VERSION "Generated from PQ35_46 ACAN KMatrix"

NS_ :

BS_:

BU_: XXX AFS Airbag Allrad AppGW_SK BAP_Tester BMS_Hybrid Bremse_ESP_AU714 Bremse_ESP_EPB_EBC460Vi Bremse_MK100_ESC Bremse_MK60EC Bremse_MK70MABS Bremse_TRW_EBC450M Bremse_TRW_ESP Daempfer EPB_TRW EPB_TRW_VW411CS ESP_AU316 FLA Gateway_PQ35 Getriebe_AG6 Getriebe_DL800_R8 Getriebe_DL800_ZSG_R8 Getriebe_DQ Getriebe_DQ_Hyb Getriebe_Sele Gurtmikro_PQ35 HCA LEH_Hybrid LH_EPS_APA LH_EPS_ZF_2G LH_EPS_ZF_3G LPG_Interface_Box LWR LWS Magne_Ride Motor_Diesel Motor_Hybrid Motor_Otto Motor_Slave PDC_PLA Quersperre_VAQ RKA_Plus SAK Waehlhebel Waehlhebel_Sele

BO_ 1416 mMotor_7: 8 XXX
 SG_ MO7_Hoeheninfo : 16|8@1+ (0.0078125,0) [0|1.984375] "" Bremse_ESP_EPB_EBC460Vi,Bremse_MK100_ESC,Bremse_MK60EC,Bremse_MK70MABS,Bremse_TRW_EBC450M,Bremse_TRW_ESP,ESP_AU316,Gateway_PQ35,Getriebe_DL800_R8,Getriebe_DQ,Getriebe_DQ_Hyb,Getriebe_Sele
 SG_ MO7_LL_Solldz : 0|1@1+ (1,0) [0|1] "" Gateway_PQ35
 SG_ MO7_Fehler_VBegr : 1|1@1+ (1,0) [0|1] "" Gateway_PQ35
 SG_ MO7_Sta_VBegr : 2|1@1+ (1,0) [0|1] "" Gateway_PQ35,Getriebe_AG6,Getriebe_DL800_R8,Getriebe_DQ,Getriebe_DQ_Hyb
 SG_ MO7_Fehlereintr : 3|1@1+ (1,0) [0|1] "" Gateway_PQ35
 SG_ MO7_StaOeltemp : 4|1@1+ (1,0) [0|1] "" Gateway_PQ35,Getriebe_DL800_R8,Getriebe_DQ,Getriebe_DQ_Hyb
 SG_ MO7_Sta_PTC : 5|3@1+ (1,0) [0|7] "" Gateway_PQ35
 SG_ MO7_DFM : 8|8@1+ (0.4,0) [0|101.6] "Unit_PerCent" Gateway_PQ35
 SG_ MO7_Gradient_Dz : 24|7@1+ (1,0) [0|126] "Unit_MinutInver" Gateway_PQ35
 SG_ MO7_GradientVorz : 31|1@1+ (1,0) [0|1] "" Gateway_PQ35
 SG_ MO7_Ladedruckneu : 32|8@1+ (0.02,0) [0|5.08] "Unit_Bar" Gateway_PQ35
 SG_ MO7_GenLdResp : 40|2@1+ (3,0) [0|9] "Unit_Secon" Gateway_PQ35
 SG_ MO7_PTC_bereit : 42|2@1+ (1,0) [0|0] "" Gateway_PQ35
 SG_ MO7_Mot_weckfaehig : 44|1@1+ (1,0) [0|1] "" Gateway_PQ35
 SG_ MO7_Zus_Kuehl : 45|1@1+ (1,0) [0|1] "" Gateway_PQ35
 SG_ MO7_SleepInd : 46|1@1+ (1,0) [0|1] "" Gateway_PQ35
 SG_ MO7_RueckLLDz : 47|1@1+ (1,0) [0|1] "" Gateway_PQ35
 SG_ MO7_Lastabwurf : 48|2@1+ (1,0) [0|3] "" Gateway_PQ35
 SG_ MO7_Gen_ein : 50|1@1+ (1,0) [0|1] "" Gateway_PQ35
 SG_ MO7_Lastabw_Heiz : 51|1@1+ (1,0) [0|1] "" Gateway_PQ35
 SG_ MO7_StaGluehk : 52|4@1+ (8,0) [0|112] "Unit_PerCent" Gateway_PQ35
 SG_ MO7_Oeltemp : 56|8@1+ (1,-60) [-58|194] "Unit_DegreCelsi" Gateway_PQ35,Getriebe_DL800_R8,Getriebe_DQ,Getriebe_DQ_Hyb,Getriebe_Sele

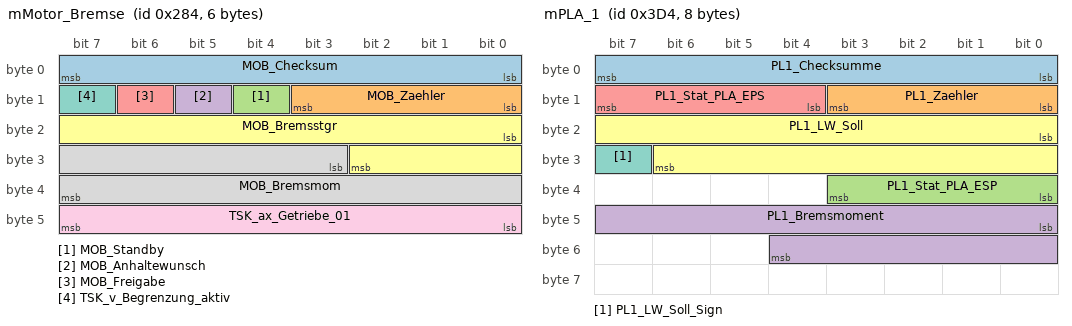
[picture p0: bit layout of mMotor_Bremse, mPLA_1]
BO_ 644 mMotor_Bremse: 6 XXX
 SG_ MOB_Checksum : 0|8@1+ (1,0) [0|255] "" Bremse_ESP_EPB_EBC460Vi,Bremse_MK100_ESC,Bremse_MK60EC,Bremse_TRW_EBC450M,Bremse_TRW_ESP
 SG_ MOB_Zaehler : 8|4@1+ (1,0) [0|15] "" Bremse_ESP_EPB_EBC460Vi,Bremse_MK100_ESC,Bremse_MK60EC,Bremse_TRW_EBC450M,Bremse_TRW_ESP
 SG_ MOB_Standby : 12|1@1+ (1,0) [0|1] "" Bremse_ESP_EPB_EBC460Vi,Bremse_MK100_ESC,Bremse_MK60EC,Bremse_TRW_EBC450M,Bremse_TRW_ESP
 SG_ MOB_Anhaltewunsch : 13|1@1+ (1,0) [0|1] "" Bremse_ESP_EPB_EBC460Vi,Bremse_MK100_ESC,Bremse_MK60EC,Bremse_TRW_EBC450M,Bremse_TRW_ESP,Getriebe_DL800_R8,Getriebe_DQ
 SG_ MOB_Freigabe : 14|1@1+ (1,0) [0|1] "" Bremse_ESP_EPB_EBC460Vi,Bremse_MK100_ESC,Bremse_MK60EC,Bremse_TRW_EBC450M,Bremse_TRW_ESP,Gateway_PQ35
 SG_ MOB_Bremsstgr : 16|11@1+ (0.048851978505129457743,0) [0|99.999999999999999999921] "Unit_PerCent" Bremse_ESP_EPB_EBC460Vi,Bremse_TRW_EBC450M,Bremse_TRW_ESP
 SG_ TSK_v_Begrenzung_aktiv : 15|1@1+ (1,0) [0|1] "" Getriebe_DQ
 SG_ MOB_Bremsmom : 27|13@1+ (4,0) [0|32760] "Unit_NewtoMeter" Bremse_MK100_ESC,Bremse_MK60EC
 SG_ TSK_ax_Getriebe_01 : 40|8@1+ (0.048,-2.016) [-2.016|10.176] "Unit_MeterPerSeconSquar" Getriebe_DQ

BO_ 980 mPLA_1: 8 XXX
 SG_ PL1_Checksumme : 0|8@1+ (1,0) [0|255] "" Bremse_ESP_EPB_EBC460Vi,Bremse_MK100_ESC,Bremse_MK60EC,Bremse_TRW_EBC450M,Bremse_TRW_ESP,Getriebe_DQ,Getriebe_DQ_Hyb,LH_EPS_APA,LH_EPS_ZF_2G,LH_EPS_ZF_3G
 SG_ PL1_Zaehler : 8|4@1+ (1,0) [0|15] "" Bremse_ESP_EPB_EBC460Vi,Bremse_MK100_ESC,Bremse_MK60EC,Bremse_TRW_EBC450M,Bremse_TRW_ESP,Getriebe_DQ,Getriebe_DQ_Hyb,LH_EPS_APA,LH_EPS_ZF_2G,LH_EPS_ZF_3G
 SG_ PL1_Stat_PLA_ESP : 32|4@1+ (1,0) [4|10] "" Bremse_ESP_EPB_EBC460Vi,Bremse_MK60EC,Bremse_TRW_EBC450M,Bremse_TRW_ESP
 SG_ PL1_Bremsmoment : 40|13@1+ (4,0) [0|32760] "Unit_NewtoMeter" Bremse_ESP_EPB_EBC460Vi,Bremse_MK100_ESC,Bremse_MK60EC,Bremse_TRW_EBC450M,Bremse_TRW_ESP,Getriebe_DQ,Getriebe_DQ_Hyb
 SG_ PL1_Stat_PLA_EPS : 12|4@1+ (1,0) [0|15] "" Bremse_MK100_ESC,LH_EPS_APA,LH_EPS_ZF_2G,LH_EPS_ZF_3G
 SG_ PL1_LW_Soll : 16|15@1+ (0.04375,0) [0|1433.55625] "Unit_DegreOfArc" LH_EPS_APA,LH_EPS_ZF_2G,LH_EPS_ZF_3G
 SG_ PL1_LW_Soll_Sign : 31|1@1+ (1,0) [0|1] "" LH_EPS_APA,LH_EPS_ZF_2G,LH_EPS_ZF_3G

BO_ 1488 mSysteminfo_1: 8 XXX
 SG_ SY1_Lenker : 28|1@1+ (1,0) [0|1] "" Bremse_ESP_EPB_EBC460Vi,Bremse_MK100_ESC,Bremse_MK60EC,Bremse_TRW_EBC450M,Bremse_TRW_ESP,ESP_AU316,Motor_Diesel
 SG_ SY1_CAN_extern : 0|1@1+ (1,0) [0|1] "" XXX
 SG_ SY1_Diag_Ant : 1|1@1+ (1,0) [0|1] "" XXX
 SG_ SY1_Sleep_Komf : 2|1@1+ (1,0) [0|1] "" XXX
 SG_ SY1_Diag_Komf : 3|1@1+ (1,0) [0|1] "" XXX
 SG_ SY1_Sleep_Info : 4|1@1+ (1,0) [0|1] "" XXX
 SG_ SY1_Diag_Info : 5|1@1+ (1,0) [0|1] "" XXX
 SG_ SY1_CAN_Info : 6|1@1+ (1,0) [0|1] "" XXX
 SG_ SY1_Verbauinfo : 7|1@1+ (1,0) [0|1] "" Bremse_MK100_ESC,Motor_Diesel
 SG_ SY1_Fzg_Klasse : 8|4@1+ (1,0) [0|9] "" XXX
 SG_ SY1_Fzg_Marke : 12|4@1+ (1,0) [0|15] "" XXX
 SG_ SY1_Fzg_Derivat : 16|4@1+ (1,0) [0|15] "" SAK
 SG_ SY1_Fzg_Gen : 20|4@1+ (1,0) [0|15] "" SAK
 SG_ SY1_Fzg_Index : 24|4@1+ (1,0) [0|15] "" XXX
 SG_ SY1_Tueren : 29|1@1+ (1,0) [0|1] "" XXX
 SG_ SY1_Transportmode : 30|1@1+ (1,0) [0|1] "" Daempfer,Motor_Diesel,Motor_Hybrid,Motor_Otto
 SG_ SY1_Fehlereintr : 31|1@1+ (1,0) [0|1] "" XXX
 SG_ SY1_Komf_NV : 32|4@1+ (1,0) [0|9] "" XXX
 SG_ SY1_Komf_HV : 36|4@1+ (1,0) [0|9] "" XXX
 SG_ SY1_Ant_NV : 40|4@1+ (1,0) [0|9] "" XXX
 SG_ SY1_Ant_HV : 44|4@1+ (1,0) [0|9] "" XXX
 SG_ SY1_Relais_FAS_Zweig : 48|2@1+ (1,0) [0|3] "" HCA
 SG_ SY1_ELV_Lock_Supply : 50|1@1+ (1,0) [0|1] "" XXX
 SG_ SY1_QRS_Messmodus : 51|1@1+ (1,0) [0|1] "" Motor_Diesel,Motor_Hybrid,Motor_Otto
 SG_ SY1_NWDF_gueltig : 54|1@1+ (1,0) [0|1] "" AFS,Allrad,FLA,LWR,PDC_PLA
 SG_ SY1_NWDF : 55|1@1+ (1,0) [0|1] "" AFS,Allrad,FLA,LWR,PDC_PLA
 SG_ SY1_Notbrems_Status : 56|1@1+ (1,0) [0|1] "" XXX

BO_ 1838 NMH_BMS: 7 XXX
 SG_ NMH_BMS_Start_1 : 0|1@1+ (1,0) [1|1] "" Bremse_ESP_EPB_EBC460Vi,Bremse_MK100_ESC,Bremse_MK60EC,Bremse_MK70MABS,Bremse_TRW_EBC450M,Bremse_TRW_ESP,EPB_TRW_VW411CS,Gateway_PQ35,Getriebe_AG6,Getriebe_DL800_ZSG_R8,LEH_Hybrid,Motor_Diesel,Motor_Hybrid,Motor_Otto
 SG_ NMH_BMS_Start_2 : 1|1@1+ (1,0) [1|1] "" XXX
 SG_ NMH_BMS_Normal_Mode_1 : 2|1@1+ (1,0) [1|1] "" XXX
 SG_ NMH_BMS_Normal_Mode_2 : 3|1@1+ (1,0) [1|1] "" XXX
 SG_ NMH_BMS_Car_WakeUp : 6|1@1+ (1,0) [1|1] "" XXX
 SG_ NMH_BMS_Per_WakeUp : 8|5@1+ (1,0) [0|3] "" XXX
 SG_ NMH_BMS_Fkt_WakeUp : 13|3@1+ (1,0) [0|0] "" XXX
 SG_ NMH_BMS_NM_aktiv_Klemme_15 : 16|1@1+ (1,0) [1|1] "" XXX
 SG_ NMH_BMS_NM_aktiv_Diagnose : 17|1@1+ (1,0) [1|1] "" XXX
 SG_ NMH_BMS_NM_aktiv_Start : 18|1@1+ (1,0) [1|1] "" XXX
 SG_ NMH_BMS_NL_aktiv_4 : 19|1@1+ (1,0) [1|1] "" XXX
 SG_ NMH_BMS_NL_aktiv_5 : 20|1@1+ (1,0) [1|1] "" XXX
 SG_ NMH_BMS_NL_aktiv_6 : 21|1@1+ (1,0) [1|1] "" XXX
 SG_ NMH_BMS_NL_aktiv_7 : 22|1@1+ (1,0) [1|1] "" XXX
 SG_ NMH_BMS_NL_aktiv_8 : 23|1@1+ (1,0) [1|1] "" XXX
 SG_ NMH_BMS_NL_0 : 24|1@1+ (1,0) [1|1] "" XXX
 SG_ NMH_BMS_NL_1 : 25|1@1+ (1,0) [1|1] "" XXX
 SG_ NMH_BMS_NL_2 : 26|1@1+ (1,0) [0|1] "" XXX
 SG_ NMH_BMS_NL_3 : 27|1@1+ (1,0) [0|1] "" XXX
 SG_ NMH_BMS_NL_4 : 28|1@1+ (1,0) [0|1] "" XXX
 SG_ NMH_BMS_NL_5 : 29|1@1+ (1,0) [0|1] "" XXX
 SG_ NMH_BMS_NL_6 : 30|1@1+ (1,0) [0|1] "" XXX
 SG_ NMH_BMS_NL_7 : 31|1@1+ (1,0) [0|1] "" XXX
 SG_ NMH_BMS_TimeOut_Fehler : 33|1@1+ (1,0) [1|1] "" XXX
 SG_ NMH_BMS_CAN_Diag_deaktiv : 34|1@1+ (1,0) [1|1] "" XXX
 SG_ NMH_BMS_KompSchutz : 35|1@1+ (1,0) [1|1] "" XXX
 SG_ NMH_BMS_Mute_Mode : 36|1@1+ (1,0) [1|1] "" XXX
 SG_ NMH_BMS_Transport_Mode : 37|1@1+ (1,0) [1|1] "" XXX
 SG_ NMH_BMS_Abschaltstufe_aktiv : 38|1@1+ (1,0) [1|1] "" XXX
 SG_ NMH_BMS_Eindraht_Fehler : 39|1@1+ (1,0) [1|1] "" XXX

BO_ 1839 NMH_EM: 7 XXX
 SG_ NMH_EM_Start_1 : 0|1@1+ (1,0) [1|1] "" BMS_Hybrid,Bremse_ESP_EPB_EBC460Vi,Bremse_MK100_ESC,Bremse_MK60EC,Bremse_MK70MABS,Bremse_TRW_EBC450M,Bremse_TRW_ESP,EPB_TRW_VW411CS,Gateway_PQ35,Getriebe_AG6,Getriebe_DL800_ZSG_R8,Motor_Diesel,Motor_Hybrid,Motor_Otto
 SG_ NMH_EM_Start_2 : 1|1@1+ (1,0) [1|1] "" XXX
 SG_ NMH_EM_Normal_Mode_1 : 2|1@1+ (1,0) [1|1] "" XXX
 SG_ NMH_EM_Normal_Mode_2 : 3|1@1+ (1,0) [1|1] "" XXX
 SG_ NMH_EM_Car_WakeUp : 6|1@1+ (1,0) [1|1] "" XXX
 SG_ NMH_EM_Per_WakeUp : 8|5@1+ (1,0) [0|3] "" XXX
 SG_ NMH_EM_Fkt_WakeUp : 13|3@1+ (1,0) [0|0] "" XXX
 SG_ NMH_EM_NM_aktiv_Klemme_15 : 16|1@1+ (1,0) [1|1] "" XXX
 SG_ NMH_EM_NM_aktiv_Diagnose : 17|1@1+ (1,0) [1|1] "" XXX
 SG_ NMH_EM_NM_aktiv_Start : 18|1@1+ (1,0) [1|1] "" XXX
 SG_ NMH_EM_NL_aktiv_4 : 19|1@1+ (1,0) [0|1] "" XXX
 SG_ NMH_EM_NL_aktiv_5 : 20|1@1+ (1,0) [1|1] "" XXX
 SG_ NMH_EM_NL_aktiv_6 : 21|1@1+ (1,0) [1|1] "" XXX
 SG_ NMH_EM_NL_aktiv_7 : 22|1@1+ (1,0) [1|1] "" XXX
 SG_ NMH_EM_NL_aktiv_8 : 23|1@1+ (1,0) [1|1] "" XXX
 SG_ NMH_EM_NL_0 : 24|1@1+ (1,0) [1|1] "" XXX
 SG_ NMH_EM_NL_1 : 25|1@1+ (1,0) [1|1] "" XXX
 SG_ NMH_EM_NL_2 : 26|1@1+ (1,0) [0|1] "" XXX
 SG_ NMH_EM_NL_3 : 27|1@1+ (1,0) [0|1] "" XXX
 SG_ NMH_EM_NL_4 : 28|1@1+ (1,0) [0|1] "" XXX
 SG_ NMH_EM_NL_5 : 29|1@1+ (1,0) [0|1] "" XXX
 SG_ NMH_EM_NL_6 : 30|1@1+ (1,0) [0|1] "" XXX
 SG_ NMH_EM_NL_7 : 31|1@1+ (1,0) [0|1] "" XXX
 SG_ NMH_EM_TimeOut_Fehler : 33|1@1+ (1,0) [1|1] "" XXX
 SG_ NMH_EM_CAN_Diag_deaktiv : 34|1@1+ (1,0) [1|1] "" XXX
 SG_ NMH_EM_KompSchutz : 35|1@1+ (1,0) [1|1] "" XXX
 SG_ NMH_EM_Mute_Mode : 36|1@1+ (1,0) [1|1] "" XXX
 SG_ NMH_EM_Transport_Mode : 37|1@1+ (1,0) [1|1] "" XXX
 SG_ NMH_EM_Abschaltstufe_aktiv : 38|1@1+ (1,0) [1|1] "" XXX
 SG_ NMH_EM_Eindraht_Fehler : 39|1@1+ (1,0) [1|1] "" XXX

BO_ 1849 NMH_EPB: 7 XXX
 SG_ NMH_EPB_Start_1 : 0|1@1+ (1,0) [1|1] "" BMS_Hybrid,Bremse_ESP_EPB_EBC460Vi,Bremse_MK100_ESC,Bremse_MK60EC,Bremse_MK70MABS,Bremse_TRW_EBC450M,Bremse_TRW_ESP,Gateway_PQ35,Getriebe_AG6,Getriebe_DL800_ZSG_R8,LEH_Hybrid,Motor_Diesel,Motor_Hybrid,Motor_Otto
 SG_ NMH_EPB_Start_2 : 1|1@1+ (1,0) [1|1] "" XXX
 SG_ NMH_EPB_Normal_Mode_1 : 2|1@1+ (1,0) [1|1] "" XXX
 SG_ NMH_EPB_Normal_Mode_2 : 3|1@1+ (1,0) [1|1] "" XXX
 SG_ NMH_EPB_Car_WakeUp : 6|1@1+ (1,0) [1|1] "" XXX
 SG_ NMH_EPB_Per_WakeUp : 8|5@1+ (1,0) [0|5] "" XXX
 SG_ NMH_EPB_Fkt_WakeUp : 13|3@1+ (1,0) [0|0] "" XXX
 SG_ NMH_EPB_NM_aktiv_Klemme_15 : 16|1@1+ (1,0) [1|1] "" XXX
 SG_ NMH_EPB_NM_aktiv_Diagnose : 17|1@1+ (1,0) [1|1] "" XXX
 SG_ NMH_EPB_NM_aktiv_Start : 18|1@1+ (1,0) [1|1] "" XXX
 SG_ NMH_EPB_NL_aktiv_4 : 19|1@1+ (1,0) [1|1] "" XXX
 SG_ NMH_EPB_NL_aktiv_5 : 20|1@1+ (1,0) [1|1] "" XXX
 SG_ NMH_EPB_NL_aktiv_6 : 21|1@1+ (1,0) [1|1] "" XXX
 SG_ NMH_EPB_NL_aktiv_7 : 22|1@1+ (1,0) [1|1] "" XXX
 SG_ NMH_EPB_NL_aktiv_8 : 23|1@1+ (1,0) [1|1] "" XXX
 SG_ NMH_EPB_NL_0 : 24|1@1+ (1,0) [0|1] "" XXX
 SG_ NMH_EPB_NL_1 : 25|1@1+ (1,0) [0|1] "" XXX
 SG_ NMH_EPB_NL_2 : 26|1@1+ (1,0) [0|1] "" XXX
 SG_ NMH_EPB_NL_3 : 27|1@1+ (1,0) [0|1] "" XXX
 SG_ NMH_EPB_NL_4 : 28|1@1+ (1,0) [0|1] "" XXX
 SG_ NMH_EPB_NL_5 : 29|1@1+ (1,0) [0|1] "" XXX
 SG_ NMH_EPB_NL_6 : 30|1@1+ (1,0) [0|1] "" XXX
 SG_ NMH_EPB_NL_7 : 31|1@1+ (1,0) [0|1] "" XXX
 SG_ NMH_EPB_TimeOut_Fehler : 33|1@1+ (1,0) [1|1] "" XXX
 SG_ NMH_EPB_CAN_Diag_deaktiv : 34|1@1+ (1,0) [1|1] "" XXX
 SG_ NMH_EPB_KompSchutz : 35|1@1+ (1,0) [1|1] "" XXX
 SG_ NMH_EPB_Mute_Mode : 36|1@1+ (1,0) [1|1] "" XXX
 SG_ NMH_EPB_Transport_Mode : 37|1@1+ (1,0) [1|1] "" XXX
 SG_ NMH_EPB_Abschaltstufe_aktiv : 38|1@1+ (1,0) [1|1] "" XXX
 SG_ NMH_EPB_Eindraht_Fehler : 39|1@1+ (1,0) [1|1] "" XXX

BO_ 1824 NMH_Gateway: 7 XXX
 SG_ NMH_GW_Start_1 : 0|1@1+ (1,0) [1|1] "" BMS_Hybrid,Bremse_ESP_EPB_EBC460Vi,Bremse_MK100_ESC,Bremse_MK60EC,Bremse_MK70MABS,Bremse_TRW_EBC450M,Bremse_TRW_ESP,EPB_TRW_VW411CS,ESP_AU316,Getriebe_AG6,Getriebe_DL800_ZSG_R8,LEH_Hybrid,Motor_Diesel,Motor_Hybrid,Motor_Otto
 SG_ NMH_GW_Start_2 : 1|1@1+ (1,0) [1|1] "" XXX
 SG_ NMH_GW_Normal_Mode_1 : 2|1@1+ (1,0) [1|1] "" XXX
 SG_ NMH_GW_Normal_Mode_2 : 3|1@1+ (1,0) [1|1] "" XXX
 SG_ NMH_GW_Car_WakeUp : 6|1@1+ (1,0) [1|1] "" XXX
 SG_ NMH_GW_Per_WakeUp : 8|5@1+ (1,0) [0|12] "" XXX
 SG_ NMH_GW_Fkt_WakeUp : 13|3@1+ (1,0) [0|7] "" XXX
 SG_ NMH_GW_NM_aktiv_Klemme_15 : 16|1@1+ (1,0) [1|1] "" XXX
 SG_ NMH_GW_NM_aktiv_Diagnose : 17|1@1+ (1,0) [1|1] "" XXX
 SG_ NMH_GW_NM_aktiv_Start : 18|1@1+ (1,0) [1|1] "" XXX
 SG_ NMH_GW_NL_aktiv_4 : 19|1@1+ (1,0) [1|1] "" XXX
 SG_ NMH_GW_NL_aktiv_5 : 20|1@1+ (1,0) [1|1] "" XXX
 SG_ NMH_GW_NL_aktiv_6 : 21|1@1+ (1,0) [1|1] "" XXX
 SG_ NMH_GW_NL_aktiv_7 : 22|1@1+ (1,0) [1|1] "" XXX
 SG_ NMH_GW_NL_aktiv_8 : 23|1@1+ (1,0) [1|1] "" XXX
 SG_ NMH_GW_NL_0 : 24|1@1+ (1,0) [1|1] "" XXX
 SG_ NMH_GW_NL_1 : 25|1@1+ (1,0) [0|1] "" XXX
 SG_ NMH_GW_NL_2 : 26|1@1+ (1,0) [0|1] "" XXX
 SG_ NMH_GW_NL_3 : 27|1@1+ (1,0) [0|1] "" XXX
 SG_ NMH_GW_NL_4 : 28|1@1+ (1,0) [0|1] "" XXX
 SG_ NMH_GW_NL_5 : 29|1@1+ (1,0) [0|1] "" XXX
 SG_ NMH_GW_NL_6 : 30|1@1+ (1,0) [0|1] "" XXX
 SG_ NMH_GW_NL_7 : 31|1@1+ (1,0) [0|1] "" XXX
 SG_ NMH_GW_TimeOut_Fehler : 33|1@1+ (1,0) [1|1] "" XXX
 SG_ NMH_GW_CAN_Diag_deaktiv : 34|1@1+ (1,0) [1|1] "" XXX
 SG_ NMH_GW_KompSchutz : 35|1@1+ (1,0) [1|1] "" XXX
 SG_ NMH_GW_Mute_Mode : 36|1@1+ (1,0) [1|1] "" XXX
 SG_ NMH_GW_Transport_Mode : 37|1@1+ (1,0) [1|1] "" XXX
 SG_ NMH_GW_Abschaltstufe_aktiv : 38|1@1+ (1,0) [1|1] "" XXX
 SG_ NMH_GW_Eindraht_Fehler : 39|1@1+ (1,0) [1|1] "" XXX

BO_ 1826 NMH_Getriebe: 7 XXX
 SG_ NMH_Getriebe_Start_1 : 0|1@1+ (1,0) [1|1] "" BMS_Hybrid,Bremse_ESP_EPB_EBC460Vi,Bremse_MK100_ESC,Bremse_MK60EC,Bremse_MK70MABS,Bremse_TRW_EBC450M,Bremse_TRW_ESP,EPB_TRW_VW411CS,Gateway_PQ35,Getriebe_DL800_ZSG_R8,LEH_Hybrid,Motor_Diesel,Motor_Hybrid,Motor_Otto
 SG_ NMH_Getriebe_Start_2 : 1|1@1+ (1,0) [1|1] "" XXX
 SG_ NMH_Getriebe_Normal_Mode_1 : 2|1@1+ (1,0) [1|1] "" XXX
 SG_ NMH_Getriebe_Normal_Mode_2 : 3|1@1+ (1,0) [1|1] "" XXX
 SG_ NMH_Getriebe_Car_WakeUp : 6|1@1+ (1,0) [1|1] "" XXX
 SG_ NMH_Getriebe_Per_WakeUp : 8|5@1+ (1,0) [0|3] "" XXX
 SG_ NMH_Getriebe_Fkt_WakeUp : 13|3@1+ (1,0) [0|0] "" XXX
 SG_ NMH_Getriebe_NM_aktiv_Klemme_15 : 16|1@1+ (1,0) [1|1] "" XXX
 SG_ NMH_Getriebe_NM_aktiv_Diagnose : 17|1@1+ (1,0) [1|1] "" XXX
 SG_ NMH_Getriebe_NM_aktiv_Start : 18|1@1+ (1,0) [1|1] "" XXX
 SG_ NMH_Getriebe_NL_aktiv_4 : 19|1@1+ (1,0) [1|1] "" XXX
 SG_ NMH_Getriebe_NL_aktiv_5 : 20|1@1+ (1,0) [1|1] "" XXX
 SG_ NMH_Getriebe_NL_aktiv_6 : 21|1@1+ (1,0) [1|1] "" XXX
 SG_ NMH_Getriebe_NL_aktiv_7 : 22|1@1+ (1,0) [1|1] "" XXX
 SG_ NMH_Getriebe_NL_aktiv_8 : 23|1@1+ (1,0) [1|1] "" XXX
 SG_ NMH_Getriebe_NL_0 : 24|1@1+ (1,0) [0|1] "" XXX
 SG_ NMH_Getriebe_NL_1 : 25|1@1+ (1,0) [0|1] "" XXX
 SG_ NMH_Getriebe_NL_2 : 26|1@1+ (1,0) [0|1] "" XXX
 SG_ NMH_Getriebe_NL_3 : 27|1@1+ (1,0) [0|1] "" XXX
 SG_ NMH_Getriebe_NL_4 : 28|1@1+ (1,0) [0|1] "" XXX
 SG_ NMH_Getriebe_NL_5 : 29|1@1+ (1,0) [0|1] "" XXX
 SG_ NMH_Getriebe_NL_6 : 30|1@1+ (1,0) [0|1] "" XXX
 SG_ NMH_Getriebe_NL_7 : 31|1@1+ (1,0) [0|1] "" XXX
 SG_ NMH_Getriebe_TimeOut_Fehler : 33|1@1+ (1,0) [1|1] "" XXX
 SG_ NMH_Getriebe_CAN_Diag_deaktiv : 34|1@1+ (1,0) [1|1] "" XXX
 SG_ NMH_Getriebe_KompSchutz : 35|1@1+ (1,0) [1|1] "" XXX
 SG_ NMH_Getriebe_Mute_Mode : 36|1@1+ (1,0) [1|1] "" XXX
 SG_ NMH_Getriebe_Transport_Mode : 37|1@1+ (1,0) [1|1] "" XXX
 SG_ NMH_Getriebe_Abschaltstufe_aktiv : 38|1@1+ (1,0) [1|1] "" XXX
 SG_ NMH_Getriebe_Eindraht_Fehler : 39|1@1+ (1,0) [1|1] "" XXX

BO_ 1834 NMH_Getriebe_02: 7 XXX
 SG_ NMH_GE_02_Start_1 : 0|1@1+ (1,0) [1|1] "" BMS_Hybrid,Bremse_ESP_EPB_EBC460Vi,Bremse_MK100_ESC,Bremse_MK60EC,Bremse_MK70MABS,Bremse_TRW_EBC450M,Bremse_TRW_ESP,EPB_TRW_VW411CS,Gateway_PQ35,Getriebe_AG6,LEH_Hybrid,Motor_Diesel,Motor_Hybrid,Motor_Otto
 SG_ NMH_GE_02_Start_2 : 1|1@1+ (1,0) [1|1] "" XXX
 SG_ NMH_GE_02_Normal_Mode_1 : 2|1@1+ (1,0) [1|1] "" XXX
 SG_ NMH_GE_02_Normal_Mode_2 : 3|1@1+ (1,0) [1|1] "" XXX
 SG_ NMH_GE_02_Car_WakeUp : 6|1@1+ (1,0) [1|1] "" XXX
 SG_ NMH_GE_02_Per_WakeUp : 8|5@1+ (1,0) [0|3] "" XXX
 SG_ NMH_GE_02_Fkt_WakeUp : 13|3@1+ (1,0) [0|0] "" XXX
 SG_ NMH_GE_02_NM_aktiv_Klemme_15 : 16|1@1+ (1,0) [1|1] "" XXX
 SG_ NMH_GE_02_NM_aktiv_Diagnose : 17|1@1+ (1,0) [1|1] "" XXX
 SG_ NMH_GE_02_NM_aktiv_Start : 18|1@1+ (1,0) [1|1] "" XXX
 SG_ NMH_GE_02_N_Haltephase : 19|1@1+ (1,0) [1|1] "" XXX
 SG_ NMH_GE_02_Positionsanzeige : 20|1@1+ (1,0) [1|1] "" XXX
 SG_ NMH_GE_02_kein_NL : 24|1@1+ (1,0) [1|1] "" XXX
 SG_ NMH_GE_02_NL_Daten_EEPROM : 25|1@1+ (1,0) [1|1] "" XXX
 SG_ NMH_GE_02_NL_Drucksens : 26|1@1+ (1,0) [1|1] "" XXX
 SG_ NMH_GE_02_NL_Abtrieb : 27|1@1+ (1,0) [1|1] "" XXX
 SG_ NMH_GE_02_NL_Waehlhebel : 28|1@1+ (1,0) [1|1] "" XXX
 SG_ NMH_GE_02_NL_Wegfahrsperre : 29|1@1+ (1,0) [1|1] "" XXX
 SG_ NMH_GE_02_Signalfehler : 32|1@1+ (1,0) [1|1] "" XXX
 SG_ NMH_GE_02_TimeOut_Fehler : 33|1@1+ (1,0) [1|1] "" XXX
 SG_ NMH_GE_02_CAN_Diag_deaktiv : 34|1@1+ (1,0) [1|1] "" XXX
 SG_ NMH_GE_02_KompSchutz : 35|1@1+ (1,0) [1|1] "" XXX
 SG_ NMH_GE_02_Mute_Mode : 36|1@1+ (1,0) [1|1] "" XXX
 SG_ NMH_GE_02_Transport_Mode : 37|1@1+ (1,0) [1|1] "" XXX
 SG_ NMH_GE_02_Abschaltstufe_aktiv : 38|1@1+ (1,0) [1|1] "" XXX
 SG_ NMH_GE_02_Eindraht_Fehler : 39|1@1+ (1,0) [1|1] "" XXX

BO_ 1836 NMH_Lademanager: 7 XXX
 SG_ NMH_Lademanager_Start_1 : 0|1@1+ (1,0) [1|1] "" BMS_Hybrid,Bremse_ESP_EPB_EBC460Vi,Bremse_MK100_ESC,Bremse_MK60EC,Bremse_MK70MABS,Bremse_TRW_EBC450M,Bremse_TRW_ESP,EPB_TRW_VW411CS,Gateway_PQ35,Getriebe_AG6,Getriebe_DL800_ZSG_R8,LEH_Hybrid,Motor_Diesel,Motor_Hybrid,Motor_Otto
 SG_ NMH_Lademanager_Start_2 : 1|1@1+ (1,0) [1|1] "" XXX
 SG_ NMH_Lademanager_Normal_Mode_1 : 2|1@1+ (1,0) [1|1] "" XXX
 SG_ NMH_Lademanager_Normal_Mode_2 : 3|1@1+ (1,0) [1|1] "" XXX
 SG_ NMH_Lademanager_Car_WakeUp : 6|1@1+ (1,0) [1|1] "" XXX
 SG_ NMH_Lademanager_Per_WakeUp : 8|5@1+ (1,0) [0|10] "" XXX
 SG_ NMH_Lademanager_Fkt_WakeUp : 13|3@1+ (1,0) [0|5] "" XXX
 SG_ NMH_Lademanager_NM_aktiv_Klemme_15 : 16|1@1+ (1,0) [1|1] "" XXX
 SG_ NMH_Lademanager_NM_aktiv_Diagnose : 17|1@1+ (1,0) [1|1] "" XXX
 SG_ NMH_Lademanager_NM_aktiv_Start : 18|1@1+ (1,0) [1|1] "" XXX
 SG_ NMH_Lademanager_NL_aktiv_4 : 19|1@1+ (1,0) [1|1] "" XXX
 SG_ NMH_Lademanager_NL_aktiv_5 : 20|1@1+ (1,0) [1|1] "" XXX
 SG_ NMH_Lademanager_NL_aktiv_6 : 21|1@1+ (1,0) [1|1] "" XXX
 SG_ NMH_Lademanager_NL_aktiv_7 : 22|1@1+ (1,0) [1|1] "" XXX
 SG_ NMH_Lademanager_NL_aktiv_8 : 23|1@1+ (1,0) [1|1] "" XXX
 SG_ NMH_Lademanager_NL_0 : 24|1@1+ (1,0) [0|1] "" XXX
 SG_ NMH_Lademanager_NL_1 : 25|1@1+ (1,0) [0|1] "" XXX
 SG_ NMH_Lademanager_NL_2 : 26|1@1+ (1,0) [0|1] "" XXX
 SG_ NMH_Lademanager_NL_3 : 27|1@1+ (1,0) [0|1] "" XXX
 SG_ NMH_Lademanager_NL_4 : 28|1@1+ (1,0) [0|1] "" XXX
 SG_ NMH_Lademanager_NL_5 : 29|1@1+ (1,0) [0|1] "" XXX
 SG_ NMH_Lademanager_NL_6 : 30|1@1+ (1,0) [0|1] "" XXX
 SG_ NMH_Lademanager_NL_7 : 31|1@1+ (1,0) [0|1] "" XXX
 SG_ NMH_Lademanager_TimeOut_Fehler : 33|1@1+ (1,0) [1|1] "" XXX
 SG_ NMH_Lademanager_CAN_Diag_deaktiv : 34|1@1+ (1,0) [1|1] "" XXX
 SG_ NMH_Lademanager_KompSchutz : 35|1@1+ (1,0) [1|1] "" XXX
 SG_ NMH_Lademanager_Mute_Mode : 36|1@1+ (1,0) [1|1] "" XXX
 SG_ NMH_Lademanager_Transport_Mode : 37|1@1+ (1,0) [1|1] "" XXX
 SG_ NMH_Lademanager_Abschaltstufe_aktiv : 38|1@1+ (1,0) [1|1] "" XXX
 SG_ NMH_Lademanager_Eindraht_Fehler : 39|1@1+ (1,0) [1|1] "" XXX

BO_ 1825 NMH_Motor: 7 XXX
 SG_ NMH_MO_Start_1 : 0|1@1+ (1,0) [1|1] "" BMS_Hybrid,Bremse_ESP_EPB_EBC460Vi,Bremse_MK100_ESC,Bremse_MK60EC,Bremse_MK70MABS,Bremse_TRW_EBC450M,Bremse_TRW_ESP,EPB_TRW_VW411CS,ESP_AU316,Gateway_PQ35,Getriebe_AG6,Getriebe_DL800_ZSG_R8,LEH_Hybrid
 SG_ NMH_MO_Start_2 : 1|1@1+ (1,0) [1|1] "" XXX
 SG_ NMH_MO_Normal_Mode_1 : 2|1@1+ (1,0) [1|1] "" XXX
 SG_ NMH_MO_Normal_Mode_2 : 3|1@1+ (1,0) [1|1] "" XXX
 SG_ NMH_MO_Car_WakeUp : 6|1@1+ (1,0) [1|1] "" XXX
 SG_ NMH_MO_Per_WakeUp : 8|5@1+ (1,0) [0|5] "" XXX
 SG_ NMH_MO_Fkt_WakeUp : 13|3@1+ (1,0) [0|0] "" XXX
 SG_ NMH_MO_NM_aktiv_Klemme_15 : 16|1@1+ (1,0) [1|1] "" XXX
 SG_ NMH_MO_NM_aktiv_Diagnose : 17|1@1+ (1,0) [1|1] "" XXX
 SG_ NMH_MO_NM_aktiv_Start : 18|1@1+ (1,0) [1|1] "" XXX
 SG_ NMH_MO_NL_aktiv_4 : 19|1@1+ (1,0) [1|1] "" XXX
 SG_ NMH_MO_NL_aktiv_5 : 20|1@1+ (1,0) [1|1] "" XXX
 SG_ NMH_MO_NL_aktiv_6 : 21|1@1+ (1,0) [1|1] "" XXX
 SG_ NMH_MO_NL_aktiv_7 : 22|1@1+ (1,0) [1|1] "" XXX
 SG_ NMH_MO_NL_aktiv_8 : 23|1@1+ (1,0) [1|1] "" XXX
 SG_ NMH_MO_NL_0 : 24|1@1+ (1,0) [0|1] "" XXX
 SG_ NMH_MO_NL_1 : 25|1@1+ (1,0) [1|1] "" XXX
 SG_ NMH_MO_NL_2 : 26|1@1+ (1,0) [1|1] "" XXX
 SG_ NMH_MO_NL_3 : 27|1@1+ (1,0) [1|1] "" XXX
 SG_ NMH_MO_NL_4 : 28|1@1+ (1,0) [1|1] "" XXX
 SG_ NMH_MO_NL_5 : 29|1@1+ (1,0) [1|1] "" XXX
 SG_ NMH_MO_NL_6 : 30|1@1+ (1,0) [0|1] "" XXX
 SG_ NMH_MO_NL_7 : 31|1@1+ (1,0) [0|1] "" XXX
 SG_ NMH_MO_TimeOut_Fehler : 33|1@1+ (1,0) [1|1] "" XXX
 SG_ NMH_MO_CAN_Diag_deaktiv : 34|1@1+ (1,0) [1|1] "" XXX
 SG_ NMH_MO_KompSchutz : 35|1@1+ (1,0) [1|1] "" XXX
 SG_ NMH_MO_Mute_Mode : 36|1@1+ (1,0) [1|1] "" XXX
 SG_ NMH_MO_Transport_Mode : 37|1@1+ (1,0) [1|1] "" XXX
 SG_ NMH_MO_Abschaltstufe_aktiv : 38|1@1+ (1,0) [1|1] "" XXX
 SG_ NMH_MO_Eindraht_Fehler : 39|1@1+ (1,0) [1|1] "" XXX

BO_ 1652 BAP_ACC: 8 XXX
 SG_ BAP_Data_ACC : 0|16@1+ (1,0) [0|65535] "" Gateway_PQ35

BO_ 1654 BAP_Anzeige: 8 XXX
 SG_ BAP_Data_Anzeige : 0|16@1+ (1,0) [0|65535] "" HCA,Motor_Hybrid,PDC_PLA

BO_ 1657 BAP_HYB: 8 XXX
 SG_ BAP_Data_HYB : 0|16@1+ (1,0) [0|65535] "" Gateway_PQ35

BO_ 1651 BAP_LDW: 8 XXX
 SG_ BAP_Data_LDW : 0|16@1+ (1,0) [0|65535] "" Gateway_PQ35

BO_ 1754 BAP_OPS: 8 XXX
 SG_ BAP_Data_OPS : 0|16@1+ (1,0) [0|65535] "" Gateway_PQ35

BO_ 1656 BAP_OPS_02: 8 XXX
 SG_ BAP_Data_OPS_02 : 0|16@1+ (1,0) [0|65535] "" Gateway_PQ35

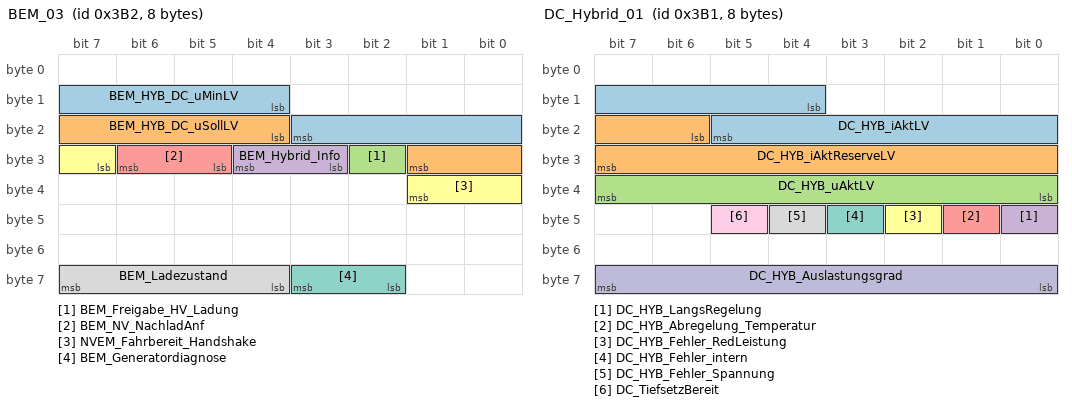
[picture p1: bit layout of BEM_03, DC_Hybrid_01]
BO_ 946 BEM_03: 8 XXX
 SG_ BEM_HYB_DC_uMinLV : 12|8@1+ (0.1,0) [0|25.3] "Unit_Volt" LEH_Hybrid
 SG_ BEM_HYB_DC_uSollLV : 20|6@1+ (0.1,10.6) [10.6|16] "Unit_Volt" LEH_Hybrid
 SG_ BEM_Freigabe_HV_Ladung : 26|1@1+ (1,0) [0|1] "" XXX
 SG_ BEM_Hybrid_Info : 27|2@1+ (1,0) [0|3] "" XXX
 SG_ BEM_NV_NachladAnf : 29|2@1+ (1,0) [0|3] "" XXX
 SG_ NVEM_Fahrbereit_Handshake : 31|3@1+ (1,0) [0|7] "" XXX
 SG_ BEM_Generatordiagnose : 58|2@1+ (1,0) [0|3] "" XXX
 SG_ BEM_Ladezustand : 60|4@1+ (10,0) [0|100] "Unit_PerCent" XXX

BO_ 945 DC_Hybrid_01: 8 XXX
 SG_ DC_HYB_iAktLV : 12|10@1+ (1,-511) [-511|510] "Unit_Amper" Gateway_PQ35
 SG_ DC_HYB_iAktReserveLV : 22|10@1+ (1,-511) [-511|510] "Unit_Amper" Gateway_PQ35
 SG_ DC_HYB_uAktLV : 32|8@1+ (0.1,0) [0|25.3] "Unit_Volt" Gateway_PQ35
 SG_ DC_HYB_LangsRegelung : 40|1@1+ (1,0) [0|1] "" Gateway_PQ35
 SG_ DC_HYB_Abregelung_Temperatur : 41|1@1+ (1,0) [0|1] "" Gateway_PQ35
 SG_ DC_HYB_Fehler_RedLeistung : 42|1@1+ (1,0) [0|1] "" Gateway_PQ35
 SG_ DC_HYB_Fehler_intern : 43|1@1+ (1,0) [0|1] "" Gateway_PQ35
 SG_ DC_HYB_Fehler_Spannung : 44|1@1+ (1,0) [0|1] "" Gateway_PQ35
 SG_ DC_TiefsetzBereit : 45|1@1+ (1,0) [0|1] "" Gateway_PQ35
 SG_ DC_HYB_Auslastungsgrad : 56|8@1+ (0.4,0) [0|100] "Unit_PerCent" Gateway_PQ35

BO_ 18 GSG_WFS_Anfrage: 8 XXX
 SG_ GSG_WFS_RND : 0|32@1+ (1,0) [0|4294967295] "" Gateway_PQ35
 SG_ GSG_WFS_CRC : 32|32@1+ (1,0) [0|4294967295] "" Gateway_PQ35

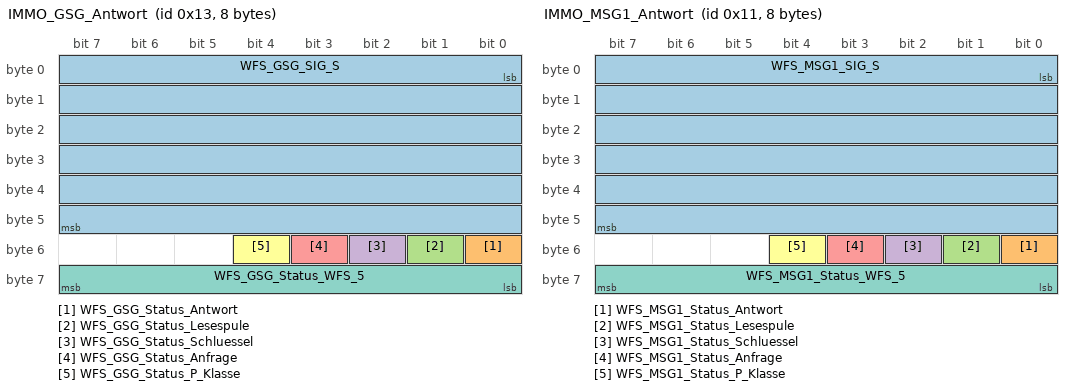
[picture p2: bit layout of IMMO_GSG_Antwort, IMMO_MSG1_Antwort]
BO_ 19 IMMO_GSG_Antwort: 8 XXX
 SG_ WFS_GSG_SIG_S : 0|48@1+ (1,0) [0|0] "" XXX
 SG_ WFS_GSG_Status_Antwort : 48|1@1+ (1,0) [0|1] "" XXX
 SG_ WFS_GSG_Status_Lesespule : 49|1@1+ (1,0) [0|1] "" XXX
 SG_ WFS_GSG_Status_Schluessel : 50|1@1+ (1,0) [0|1] "" XXX
 SG_ WFS_GSG_Status_Anfrage : 51|1@1+ (1,0) [0|1] "" XXX
 SG_ WFS_GSG_Status_P_Klasse : 52|1@1+ (1,0) [0|1] "" XXX
 SG_ WFS_GSG_Status_WFS_5 : 56|8@1+ (1,0) [0|255] "" XXX

BO_ 17 IMMO_MSG1_Antwort: 8 XXX
 SG_ WFS_MSG1_SIG_S : 0|48@1+ (1,0) [0|0] "" Motor_Diesel,Motor_Hybrid,Motor_Otto
 SG_ WFS_MSG1_Status_Antwort : 48|1@1+ (1,0) [0|1] "" Motor_Diesel,Motor_Hybrid,Motor_Otto
 SG_ WFS_MSG1_Status_Lesespule : 49|1@1+ (1,0) [0|1] "" Motor_Diesel,Motor_Hybrid,Motor_Otto
 SG_ WFS_MSG1_Status_Schluessel : 50|1@1+ (1,0) [0|1] "" Motor_Diesel,Motor_Hybrid,Motor_Otto
 SG_ WFS_MSG1_Status_Anfrage : 51|1@1+ (1,0) [0|1] "" Motor_Diesel,Motor_Hybrid,Motor_Otto
 SG_ WFS_MSG1_Status_P_Klasse : 52|1@1+ (1,0) [0|1] "" Motor_Diesel,Motor_Hybrid,Motor_Otto
 SG_ WFS_MSG1_Status_WFS_5 : 56|8@1+ (1,0) [0|255] "" Motor_Diesel,Motor_Hybrid,Motor_Otto

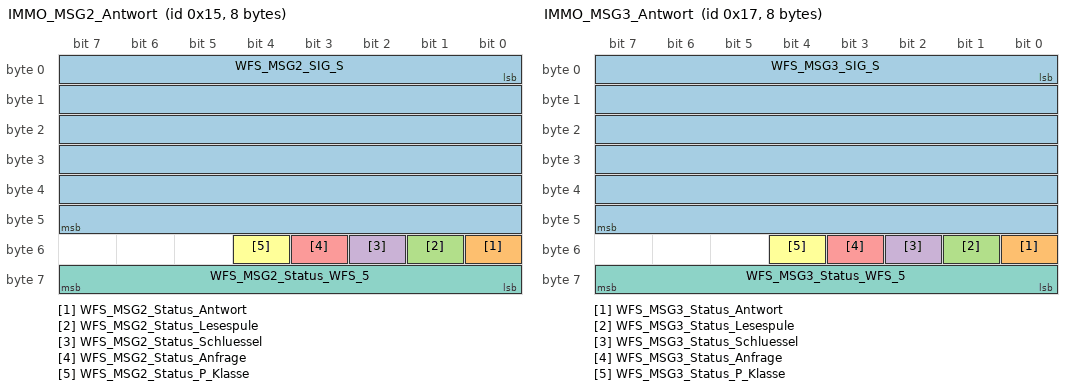
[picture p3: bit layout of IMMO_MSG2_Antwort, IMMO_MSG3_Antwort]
BO_ 21 IMMO_MSG2_Antwort: 8 XXX
 SG_ WFS_MSG2_SIG_S : 0|48@1+ (1,0) [0|0] "" Motor_Slave
 SG_ WFS_MSG2_Status_Antwort : 48|1@1+ (1,0) [0|1] "" Motor_Slave
 SG_ WFS_MSG2_Status_Lesespule : 49|1@1+ (1,0) [0|1] "" Motor_Slave
 SG_ WFS_MSG2_Status_Schluessel : 50|1@1+ (1,0) [0|1] "" Motor_Slave
 SG_ WFS_MSG2_Status_Anfrage : 51|1@1+ (1,0) [0|1] "" Motor_Slave
 SG_ WFS_MSG2_Status_P_Klasse : 52|1@1+ (1,0) [0|1] "" Motor_Slave
 SG_ WFS_MSG2_Status_WFS_5 : 56|8@1+ (1,0) [0|255] "" Motor_Slave

BO_ 23 IMMO_MSG3_Antwort: 8 XXX
 SG_ WFS_MSG3_SIG_S : 0|48@1+ (1,0) [0|0] "" XXX
 SG_ WFS_MSG3_Status_Antwort : 48|1@1+ (1,0) [0|1] "" XXX
 SG_ WFS_MSG3_Status_Lesespule : 49|1@1+ (1,0) [0|1] "" XXX
 SG_ WFS_MSG3_Status_Schluessel : 50|1@1+ (1,0) [0|1] "" XXX
 SG_ WFS_MSG3_Status_Anfrage : 51|1@1+ (1,0) [0|1] "" XXX
 SG_ WFS_MSG3_Status_P_Klasse : 52|1@1+ (1,0) [0|1] "" XXX
 SG_ WFS_MSG3_Status_WFS_5 : 56|8@1+ (1,0) [0|255] "" XXX

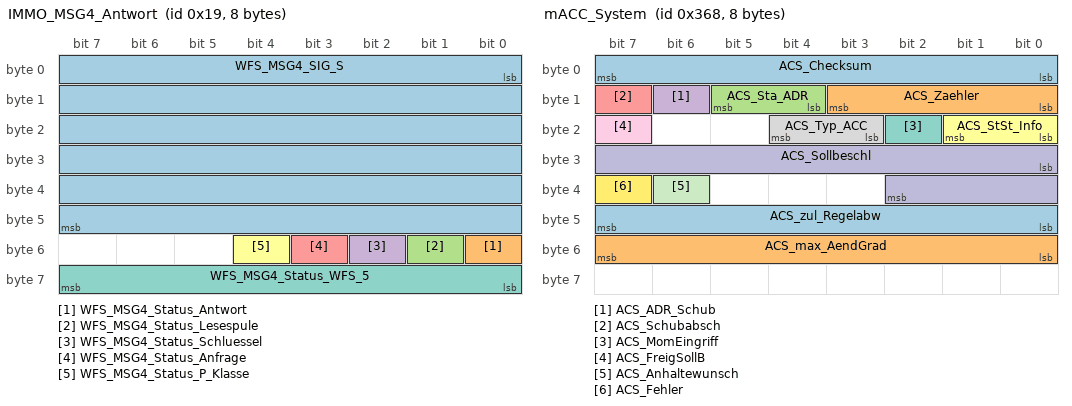
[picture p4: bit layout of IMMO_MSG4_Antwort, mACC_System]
BO_ 25 IMMO_MSG4_Antwort: 8 XXX
 SG_ WFS_MSG4_SIG_S : 0|48@1+ (1,0) [0|0] "" LEH_Hybrid
 SG_ WFS_MSG4_Status_Antwort : 48|1@1+ (1,0) [0|1] "" LEH_Hybrid
 SG_ WFS_MSG4_Status_Lesespule : 49|1@1+ (1,0) [0|1] "" LEH_Hybrid
 SG_ WFS_MSG4_Status_Schluessel : 50|1@1+ (1,0) [0|1] "" LEH_Hybrid
 SG_ WFS_MSG4_Status_Anfrage : 51|1@1+ (1,0) [0|1] "" LEH_Hybrid
 SG_ WFS_MSG4_Status_P_Klasse : 52|1@1+ (1,0) [0|1] "" LEH_Hybrid
 SG_ WFS_MSG4_Status_WFS_5 : 56|8@1+ (1,0) [0|255] "" LEH_Hybrid

BO_ 1879 ISO_ACC_Req: 8 XXX
 SG_ ISO_ACC_Req_Data : 0|64@1+ (1,0) [0|0] "" XXX

BO_ 1985 ISO_ACC_Resp: 8 XXX
 SG_ ISO_ACC_Resp_Data : 0|64@1+ (1,0) [0|0] "" Gateway_PQ35

BO_ 1892 ISO_AGA_Req: 8 XXX
 SG_ ISO_AGA_Req_Data : 0|64@1+ (1,0) [0|0] "" XXX

BO_ 1813 ISO_Airbag_01_Req: 8 XXX
 SG_ ISO_Airbag_01_Req_Data : 0|64@1+ (1,0) [0|0] "" Airbag

BO_ 1919 ISO_Airbag_01_Resp: 8 XXX
 SG_ ISO_Airbag_01_Resp_Data : 0|64@1+ (1,0) [0|0] "" Gateway_PQ35

BO_ 1807 ISO_Allrad_Req: 8 XXX
 SG_ ISO_Allrad_Req_Data : 0|64@1+ (1,0) [0|0] "" Allrad

BO_ 1913 ISO_Allrad_Resp: 8 XXX
 SG_ ISO_Allrad_Resp_Data : 0|64@1+ (1,0) [0|0] "" Gateway_PQ35

BO_ 1874 ISO_EPB_Req: 8 XXX
 SG_ ISO_EPB_Req_Data : 0|64@1+ (1,0) [0|0] "" EPB_TRW_VW411CS,RKA_Plus

BO_ 1980 ISO_EPB_Resp: 8 XXX
 SG_ ISO_EPB_Resp_Data : 0|64@1+ (1,0) [0|0] "" Gateway_PQ35

BO_ 1802 ISO_EPH_Req: 8 XXX
 SG_ ISO_EPH_Req_Data : 0|64@1+ (1,0) [0|0] "" PDC_PLA

BO_ 1908 ISO_EPH_Resp: 8 XXX
 SG_ ISO_EPH_Resp_Data : 0|64@1+ (1,0) [0|0] "" Gateway_PQ35

BO_ 1840 ISO_FLA_Req: 8 XXX
 SG_ ISO_FLA_Req_Data : 0|64@1+ (1,0) [0|0] "" FLA

BO_ 1946 ISO_FLA_Resp: 8 XXX
 SG_ ISO_FLA_Resp_Data : 0|64@1+ (1,0) [0|0] "" Gateway_PQ35

BO_ 1795 ISO_Funktionaler_Req_Abgas: 8 XXX
 SG_ ISO_Funktionaler_Req_Abgas : 0|64@1+ (1,0) [0|0] "" BMS_Hybrid,Getriebe_AG6,Getriebe_DL800_R8,Getriebe_DL800_ZSG_R8,Getriebe_DQ,Getriebe_DQ_Hyb,Getriebe_Sele,LEH_Hybrid,Motor_Diesel,Motor_Hybrid,Motor_Otto

BO_ 2015 ISO_Funktionaler_Req_OBD: 8 XXX
 SG_ ISO_OBD_Funktionaler_Req_Data : 0|64@1+ (1,0) [0|0] "" BMS_Hybrid,Getriebe_AG6,Getriebe_DL800_R8,Getriebe_DL800_ZSG_R8,Getriebe_DQ,Getriebe_DQ_Hyb,Getriebe_Sele,LEH_Hybrid,Motor_Diesel,Motor_Hybrid,Motor_Otto

BO_ 2017 ISO_Getriebe_01_Req: 8 XXX
 SG_ ISO_Getriebe_01_Req_Data : 0|64@1+ (1,0) [0|0] "" Getriebe_AG6,Getriebe_DL800_R8,Getriebe_DQ,Getriebe_DQ_Hyb,Getriebe_Sele

BO_ 2025 ISO_Getriebe_01_Resp: 8 XXX
 SG_ ISO_Getriebe_01_Resp_Data : 0|64@1+ (1,0) [0|0] "" Gateway_PQ35

BO_ 1891 ISO_Gurtmikro_Req: 8 XXX
 SG_ ISO_Gurtmikro_Req_Data : 0|64@1+ (1,0) [0|0] "" Gurtmikro_PQ35

BO_ 1997 ISO_Gurtmikro_Resp: 8 XXX
 SG_ ISO_Gurtmikro_Resp_Data : 0|64@1+ (1,0) [0|0] "" Gateway_PQ35

BO_ 1860 ISO_Ladegeraet_Req: 8 XXX
 SG_ ISO_Ladegeraet_Req_Data : 0|64@1+ (1,0) [0|0] "" Motor_Slave

BO_ 1810 ISO_Lenkhilfe_Req: 8 XXX
 SG_ ISO_Lenkhilfe_Req_Data : 0|64@1+ (1,0) [0|0] "" LH_EPS_ZF_3G

BO_ 1916 ISO_Lenkhilfe_Resp: 8 XXX
 SG_ ISO_Lenkhilfe_Resp_Data : 0|64@1+ (1,0) [0|0] "" Gateway_PQ35

BO_ 1832 ISO_LIN_Flash_Req: 8 XXX
 SG_ ISO_LIN_Flash_Req_Data : 0|64@1+ (1,0) [0|0] "" AFS

BO_ 1938 ISO_LIN_Flash_Resp: 8 XXX
 SG_ ISO_LIN_Flash_Resp_Data : 0|64@1+ (1,0) [0|0] "" Gateway_PQ35

BO_ 1876 ISO_LWRAFS_Req: 8 XXX
 SG_ ISO_LWRAFS_Req_Data : 0|64@1+ (1,0) [0|0] "" AFS

BO_ 1982 ISO_LWRAFS_Resp: 8 XXX
 SG_ ISO_LWRAFS_Resp_Data : 0|64@1+ (1,0) [0|0] "" Gateway_PQ35

BO_ 2016 ISO_MO_01_Req: 8 XXX
 SG_ ISO_MO_01_Req_Data : 0|64@1+ (1,0) [0|0] "" Motor_Diesel,Motor_Hybrid,Motor_Otto

BO_ 2024 ISO_MO_01_Resp: 8 XXX
 SG_ ISO_MO_01_Resp_Data : 0|64@1+ (1,0) [0|0] "" Gateway_PQ35

BO_ 2018 ISO_OBD_01_Req: 8 XXX
 SG_ ISO_OBD_01_Req_Data : 0|64@1+ (1,0) [0|0] "" Motor_Slave

BO_ 2026 ISO_OBD_01_Resp: 8 XXX
 SG_ ISO_OBD_01_Resp_Data : 0|64@1+ (1,0) [0|0] "" Gateway_PQ35

BO_ 2019 ISO_OBD_02_Req: 8 XXX
 SG_ ISO_OBD_02_Req_Data : 0|64@1+ (1,0) [0|0] "" Getriebe_DL800_ZSG_R8

BO_ 2027 ISO_OBD_02_Resp: 8 XXX
 SG_ ISO_OBD_02_Resp_Data : 0|64@1+ (1,0) [0|0] "" Gateway_PQ35

BO_ 2020 ISO_OBD_03_Req: 8 XXX
 SG_ ISO_OBD_03_Req_Data : 0|64@1+ (1,0) [0|0] "" XXX

BO_ 2028 ISO_OBD_03_Resp: 8 XXX
 SG_ ISO_OBD_03_Resp_Data : 0|64@1+ (1,0) [0|0] "" Gateway_PQ35

BO_ 2021 ISO_OBD_04_Req: 8 XXX
 SG_ ISO_OBD_04_Req_Data : 0|64@1+ (1,0) [0|0] "" BMS_Hybrid

BO_ 2029 ISO_OBD_04_Resp: 8 XXX
 SG_ ISO_OBD_04_Resp_Data : 0|64@1+ (1,0) [0|0] "" Gateway_PQ35

BO_ 2022 ISO_OBD_05_Req: 8 XXX
 SG_ ISO_OBD_05_Req_Data : 0|64@1+ (1,0) [0|0] "" LEH_Hybrid

BO_ 2030 ISO_OBD_05_Resp: 8 XXX
 SG_ ISO_OBD_05_Resp_Data : 0|64@1+ (1,0) [0|0] "" Gateway_PQ35

BO_ 2023 ISO_OBD_06_Req: 8 XXX
 SG_ ISO_OBD_06_Req_Data : 0|64@1+ (1,0) [0|0] "" XXX

BO_ 2031 ISO_OBD_06_Resp: 8 XXX
 SG_ ISO_OBD_06_Resp_Data : 0|64@1+ (1,0) [0|0] "" Gateway_PQ35

BO_ 1822 ISO_Quersperre_Req: 8 XXX
 SG_ ISO_Quersperre_Req_Data : 0|64@1+ (1,0) [0|0] "" XXX

BO_ 1928 ISO_Quersperre_Resp: 8 XXX
 SG_ ISO_Quersperre_Resp_Data : 0|64@1+ (1,0) [0|0] "" Gateway_PQ35

BO_ 1386 mACC_GRA_Anzeige: 8 XXX
 SG_ ACA_Checksum : 0|8@1+ (1,0) [0|255] "" Getriebe_AG6
 SG_ ACA_StaACC : 8|3@1+ (1,0) [0|7] "" PDC_PLA
 SG_ ACA_ID_StaACC : 11|5@1+ (1,0) [0|0] "" XXX
 SG_ ACA_Fahrerhinw : 16|1@1+ (1,0) [0|1] "" XXX
 SG_ ACA_AnzDisplay : 17|1@1+ (1,0) [0|1] "" XXX
 SG_ ACA_Zeitluecke : 18|4@1+ (1,0) [0|15] "" XXX
 SG_ ACA_V_Wunsch : 24|8@1+ (1,0) [0|254] "Unit_KiloMeterPerHour" Getriebe_AG6,Getriebe_DL800_R8,Getriebe_DQ,Getriebe_DQ_Hyb
 SG_ ACA_kmh_mph : 32|1@1+ (1,0) [0|1] "" XXX
 SG_ ACA_Akustik1 : 33|1@1+ (1,0) [0|1] "" XXX
 SG_ ACA_Akustik2 : 34|1@1+ (1,0) [0|1] "" XXX
 SG_ ACA_PrioDisp : 35|2@1+ (1,0) [0|3] "" XXX
 SG_ ACA_gemZeitl : 40|4@1+ (1,0) [0|15] "" XXX
 SG_ ACA_ACC_Verz : 44|1@1+ (1,0) [0|1] "" XXX
 SG_ ACA_StaGRA : 48|3@1+ (1,0) [0|7] "" XXX
 SG_ ACA_ID_StaGRA : 51|5@1+ (1,0) [0|0] "" XXX
 SG_ ACA_Codierung : 56|1@1+ (1,0) [0|1] "" Getriebe_DL800_R8,Getriebe_DQ
 SG_ ACA_Tachokranz : 57|1@1+ (1,0) [0|1] "" XXX
 SG_ ACA_Aend_Zeitluecke : 58|1@1+ (1,0) [0|1] "" XXX
 SG_ ACA_Zaehler : 60|4@1+ (1,0) [0|15] "" Getriebe_AG6

BO_ 872 mACC_System: 8 XXX
 SG_ ACS_Checksum : 0|8@1+ (1,0) [0|255] "" Daempfer,Getriebe_AG6,Getriebe_DQ,Motor_Diesel,Motor_Otto
 SG_ ACS_Zaehler : 8|4@1+ (1,0) [0|15] "" Daempfer,Getriebe_AG6,Getriebe_DQ,Motor_Diesel,Motor_Otto
 SG_ ACS_Sta_ADR : 12|2@1+ (1,0) [0|3] "" Getriebe_DQ,Motor_Diesel,Motor_Otto
 SG_ ACS_ADR_Schub : 14|1@1+ (1,0) [0|1] "" Getriebe_DQ,Motor_Diesel,Motor_Otto
 SG_ ACS_Schubabsch : 15|1@1+ (1,0) [0|1] "" Getriebe_DQ,Motor_Diesel,Motor_Otto
 SG_ ACS_StSt_Info : 16|2@1+ (1,0) [0|3] "" Motor_Diesel,Motor_Otto
 SG_ ACS_MomEingriff : 18|1@1+ (1,0) [0|1] "" Getriebe_DQ,Motor_Diesel,Motor_Otto
 SG_ ACS_Typ_ACC : 19|2@1+ (1,0) [0|3] "" Getriebe_DQ,Motor_Diesel,Motor_Otto
 SG_ ACS_FreigSollB : 23|1@1+ (1,0) [0|1] "" Daempfer,Getriebe_DQ,Motor_Diesel,Motor_Otto
 SG_ ACS_Sollbeschl : 24|11@1+ (0.005,-7.22) [-7.22|3.005] "Unit_MeterPerSeconSquar" Daempfer,Getriebe_AG6,Getriebe_DQ,Motor_Diesel,Motor_Otto
 SG_ ACS_Anhaltewunsch : 38|1@1+ (1,0) [0|1] "" Motor_Diesel,Motor_Otto
 SG_ ACS_Fehler : 39|1@1+ (1,0) [0|1] "" XXX
 SG_ ACS_zul_Regelabw : 40|8@1+ (0.005,0) [0|1.265] "Unit_MeterPerSeconSquar" Motor_Diesel,Motor_Otto
 SG_ ACS_max_AendGrad : 48|8@1+ (0.02,0) [0.02|5.06] "Unit_MeterPerSeconSquar" Motor_Diesel,Motor_Otto

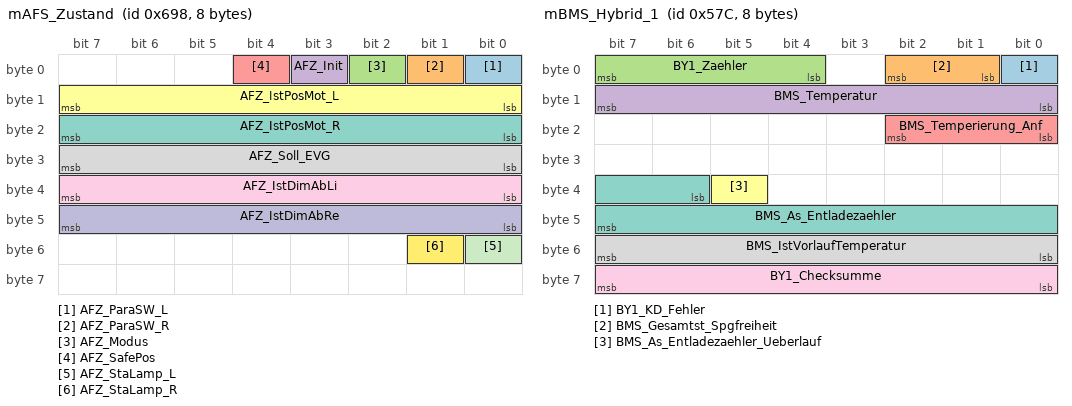
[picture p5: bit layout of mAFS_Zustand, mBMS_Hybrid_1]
BO_ 1688 mAFS_Zustand: 8 XXX
 SG_ AFZ_ParaSW_L : 0|1@1+ (1,0) [0|1] "" XXX
 SG_ AFZ_ParaSW_R : 1|1@1+ (1,0) [0|1] "" XXX
 SG_ AFZ_Modus : 2|1@1+ (1,0) [0|1] "" XXX
 SG_ AFZ_Init : 3|1@1+ (1,0) [0|1] "" XXX
 SG_ AFZ_SafePos : 4|1@1+ (1,0) [0|1] "" XXX
 SG_ AFZ_IstPosMot_L : 8|8@1+ (0.4,0) [0|100] "Unit_PerCent" XXX
 SG_ AFZ_IstPosMot_R : 16|8@1+ (0.4,0) [0|100] "Unit_PerCent" XXX
 SG_ AFZ_Soll_EVG : 24|8@1+ (0.4,0) [0|100] "Unit_PerCent" XXX
 SG_ AFZ_IstDimAbLi : 32|8@1+ (0.4,0) [0|100] "Unit_PerCent" XXX
 SG_ AFZ_IstDimAbRe : 40|8@1+ (0.4,0) [0|100] "Unit_PerCent" XXX
 SG_ AFZ_StaLamp_L : 48|1@1+ (1,0) [0|1] "" XXX
 SG_ AFZ_StaLamp_R : 49|1@1+ (1,0) [0|1] "" XXX

BO_ 1360 mAirbag_2: 8 XXX
 SG_ AB2_Checksum : 0|8@1+ (1,0) [0|255] "" Gateway_PQ35
 SG_ AB2_Beleg_HF : 8|2@1+ (1,0) [0|3] "" Gateway_PQ35
 SG_ AB2_Beleg_HBF : 10|2@1+ (1,0) [0|3] "" Gateway_PQ35
 SG_ AB2_Beleg_HM : 12|2@1+ (1,0) [0|3] "" Gateway_PQ35
 SG_ AB2_Beleg_BF : 14|2@1+ (1,0) [0|3] "" Gateway_PQ35,Gurtmikro_PQ35
 SG_ AB2_OOP_Fa : 16|3@1+ (1,0) [0|7] "" Gateway_PQ35
 SG_ AB2_OOP_BF : 19|3@1+ (1,0) [0|7] "" Gateway_PQ35
 SG_ AB2_Sta_BF : 22|2@1+ (1,0) [0|3] "" Gateway_PQ35
 SG_ AB2_Gurt_2FaS : 24|2@1+ (1,0) [0|3] "" Gateway_PQ35
 SG_ AB2_Gurt_2BfS : 26|2@1+ (1,0) [0|3] "" Gateway_PQ35
 SG_ AB2_Gurt_2Mi : 28|2@1+ (1,0) [0|3] "" Gateway_PQ35
 SG_ AB2_Gurt_3FaS : 30|2@1+ (1,0) [0|3] "" Gateway_PQ35
 SG_ AB2_Gurt_3BfS : 32|2@1+ (1,0) [0|3] "" Gateway_PQ35
 SG_ AB2_Gurt_3Mi : 34|2@1+ (1,0) [0|3] "" Gateway_PQ35
 SG_ AB_Deaktivierung_HV : 36|3@1+ (1,0) [0|7] "" Gateway_PQ35
 SG_ AB_Abschaltanf_SIH_BF : 39|1@1+ (1,0) [0|1] "" Gateway_PQ35
 SG_ AB2_Zaehler : 60|4@1+ (1,0) [0|15] "" Gateway_PQ35

BO_ 1404 mBMS_Hybrid_1: 8 XXX
 SG_ BY1_KD_Fehler : 0|1@1+ (1,0) [0|1] "" Gateway_PQ35
 SG_ BMS_Gesamtst_Spgfreiheit : 1|2@1+ (1,0) [0|3] "" Gateway_PQ35
 SG_ BY1_Zaehler : 4|4@1+ (1,0) [0|15] "" Gateway_PQ35
 SG_ BMS_Temperatur : 8|8@1+ (0.5,-40) [-40|86.5] "Unit_DegreCelsi" Gateway_PQ35
 SG_ BMS_Temperierung_Anf : 16|3@1+ (1,0) [0|7] "" Gateway_PQ35
 SG_ BMS_As_Entladezaehler_Ueberlauf : 37|1@1+ (1,0) [0|1] "" Gateway_PQ35
 SG_ BMS_As_Entladezaehler : 38|10@1+ (1,0) [0|1023] "Unit_AmperSecon" Gateway_PQ35
 SG_ BMS_IstVorlaufTemperatur : 48|8@1+ (0.5,-40) [-40|86.5] "Unit_DegreCelsi" Gateway_PQ35
 SG_ BY1_Checksumme : 56|8@1+ (1,0) [0|255] "" Gateway_PQ35

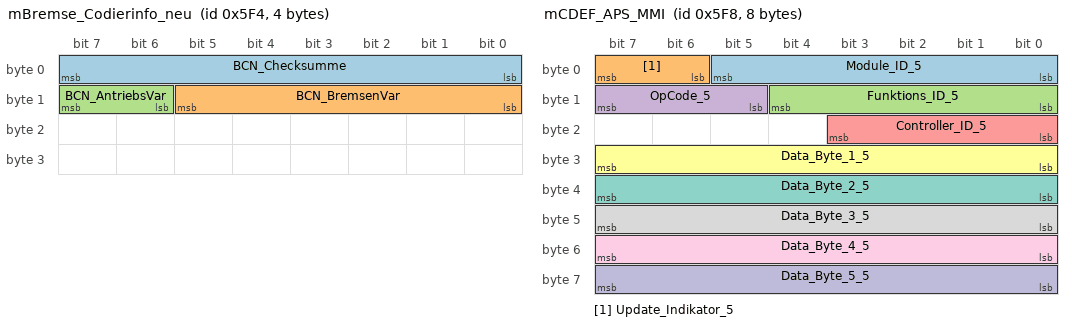
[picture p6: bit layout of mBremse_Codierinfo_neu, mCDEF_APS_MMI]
BO_ 1524 mBremse_Codierinfo_neu: 4 XXX
 SG_ BCN_Checksumme : 0|8@1+ (1,0) [0|255] "" Bremse_ESP_AU714,Bremse_MK60EC
 SG_ BCN_BremsenVar : 8|6@1+ (1,0) [0|63] "" Bremse_ESP_AU714,Bremse_MK60EC
 SG_ BCN_AntriebsVar : 14|2@1+ (1,0) [0|3] "" Bremse_ESP_AU714,Bremse_MK60EC

BO_ 1528 mCDEF_APS_MMI: 8 XXX
 SG_ Module_ID_5 : 0|6@1+ (1,0) [0|63] "" Gateway_PQ35
 SG_ Update_Indikator_5 : 6|2@1+ (1,0) [0|3] "" Gateway_PQ35
 SG_ Funktions_ID_5 : 8|5@1+ (1,0) [0|31] "" Gateway_PQ35
 SG_ OpCode_5 : 13|3@1+ (1,0) [0|7] "" Gateway_PQ35
 SG_ Controller_ID_5 : 16|4@1+ (1,0) [0|15] "" Gateway_PQ35
 SG_ Data_Byte_1_5 : 24|8@1+ (1,0) [0|255] "" Gateway_PQ35
 SG_ Data_Byte_2_5 : 32|8@1+ (1,0) [0|255] "" Gateway_PQ35
 SG_ Data_Byte_3_5 : 40|8@1+ (1,0) [0|255] "" Gateway_PQ35
 SG_ Data_Byte_4_5 : 48|8@1+ (1,0) [0|255] "" Gateway_PQ35
 SG_ Data_Byte_5_5 : 56|8@1+ (1,0) [0|255] "" Gateway_PQ35

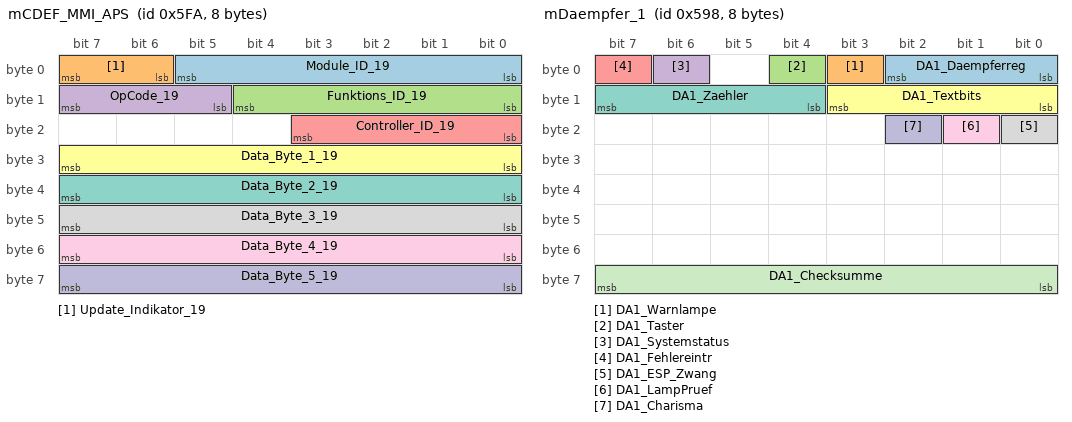
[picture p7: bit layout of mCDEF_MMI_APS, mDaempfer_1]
BO_ 1530 mCDEF_MMI_APS: 8 XXX
 SG_ Module_ID_19 : 0|6@1+ (1,0) [0|63] "" PDC_PLA
 SG_ Update_Indikator_19 : 6|2@1+ (1,0) [0|3] "" PDC_PLA
 SG_ Funktions_ID_19 : 8|5@1+ (1,0) [0|31] "" PDC_PLA
 SG_ OpCode_19 : 13|3@1+ (1,0) [0|7] "" PDC_PLA
 SG_ Controller_ID_19 : 16|4@1+ (1,0) [0|15] "" PDC_PLA
 SG_ Data_Byte_1_19 : 24|8@1+ (1,0) [0|255] "" PDC_PLA
 SG_ Data_Byte_2_19 : 32|8@1+ (1,0) [0|255] "" PDC_PLA
 SG_ Data_Byte_3_19 : 40|8@1+ (1,0) [0|255] "" PDC_PLA
 SG_ Data_Byte_4_19 : 48|8@1+ (1,0) [0|255] "" PDC_PLA
 SG_ Data_Byte_5_19 : 56|8@1+ (1,0) [0|255] "" PDC_PLA

BO_ 1504 mClima_1: 8 XXX
 SG_ CL1_LL_Dz : 0|1@1+ (1,0) [0|1] "" Motor_Diesel,Motor_Hybrid,Motor_Otto
 SG_ CL1_Fa_Zuheiz : 1|1@1+ (1,0) [0|1] "" Motor_Diesel,Motor_Hybrid,Motor_Otto
 SG_ CL1_Hecksch : 2|1@1+ (1,0) [0|1] "" XXX
 SG_ CL1_Frontsch : 3|1@1+ (1,0) [0|1] "" XXX
 SG_ CL1_Kompressor : 4|1@1+ (1,0) [0|1] "" Motor_Diesel,Motor_Hybrid,Motor_Otto
 SG_ CL1_Heizleist : 5|1@1+ (1,0) [0|1] "" Motor_Diesel
 SG_ CL1_Sta_Moment : 6|1@1+ (1,0) [0|1] "" Motor_Hybrid,Motor_Otto
 SG_ CL1_Sta_Druck : 7|1@1+ (1,0) [0|1] "" Motor_Hybrid,Motor_Otto
 SG_ CL1_Aussentemp : 8|8@1+ (0.5,-50) [-50|77] "Unit_DegreCelsi" XXX
 SG_ CL1_Druck : 16|8@1+ (0.2,0) [0|50.8] "Unit_Bar" Motor_Diesel,Motor_Hybrid,Motor_Otto
 SG_ CL1_Kompr_Last : 24|8@1+ (0.25,0) [0|63.5] "Unit_NewtoMeter" Motor_Diesel,Motor_Hybrid,Motor_Otto
 SG_ CL1_Gebl_last : 32|8@1+ (0.4,0) [0|100] "Unit_PerCent" BMS_Hybrid,Motor_Otto
 SG_ CL1_Luefter : 40|8@1+ (0.4,0) [0|100] "Unit_PerCent" Motor_Diesel,Motor_Hybrid,Motor_Otto
 SG_ CL1_Einheit_Temp : 48|1@1+ (1,0) [0|1] "" XXX
 SG_ CL1_AC_Schalter : 49|1@1+ (1,0) [0|1] "" Motor_Diesel,Motor_Hybrid,Motor_Otto
 SG_ CL1_WAPU_Zuschaltung : 50|1@1+ (1,0) [0|1] "" XXX
 SG_ CL1_Restwaerme : 51|1@1+ (1,0) [0|1] "" XXX
 SG_ CL1_PTC_Hzg : 52|3@1+ (25,0) [0|100] "Unit_PerCent" XXX
 SG_ CL1_Fehlereintr : 55|1@1+ (1,0) [0|1] "" XXX
 SG_ KL_Thermomanagement : 56|2@1+ (1,0) [0|3] "" Motor_Diesel,Motor_Hybrid,Motor_Otto
 SG_ KL_VK_Betriebsdauer : 58|6@1+ (1,0) [0|60] "Unit_Minut" XXX

BO_ 1432 mDaempfer_1: 8 XXX
 SG_ DA1_Daempferreg : 0|3@1+ (1,0) [0|7] "" Gateway_PQ35
 SG_ DA1_Warnlampe : 3|1@1+ (1,0) [0|1] "" Gateway_PQ35
 SG_ DA1_Taster : 4|1@1+ (1,0) [0|1] "" Gateway_PQ35
 SG_ DA1_Systemstatus : 6|1@1+ (1,0) [0|1] "" Gateway_PQ35
 SG_ DA1_Fehlereintr : 7|1@1+ (1,0) [0|1] "" Gateway_PQ35
 SG_ DA1_Textbits : 8|4@1+ (1,0) [0|0] "" Gateway_PQ35
 SG_ DA1_Zaehler : 12|4@1+ (1,0) [0|15] "" Bremse_ESP_AU714,Bremse_MK100_ESC,Bremse_MK60EC,Gateway_PQ35
 SG_ DA1_ESP_Zwang : 16|1@1+ (1,0) [0|1] "" Bremse_ESP_AU714,Bremse_MK100_ESC,Bremse_MK60EC,Gateway_PQ35
 SG_ DA1_LampPruef : 17|1@1+ (1,0) [0|1] "" Gateway_PQ35
 SG_ DA1_Charisma : 18|1@1+ (1,0) [0|1] "" Gateway_PQ35
 SG_ DA1_Checksumme : 56|8@1+ (1,0) [0|255] "" Bremse_ESP_AU714,Bremse_MK100_ESC,Bremse_MK60EC,Gateway_PQ35

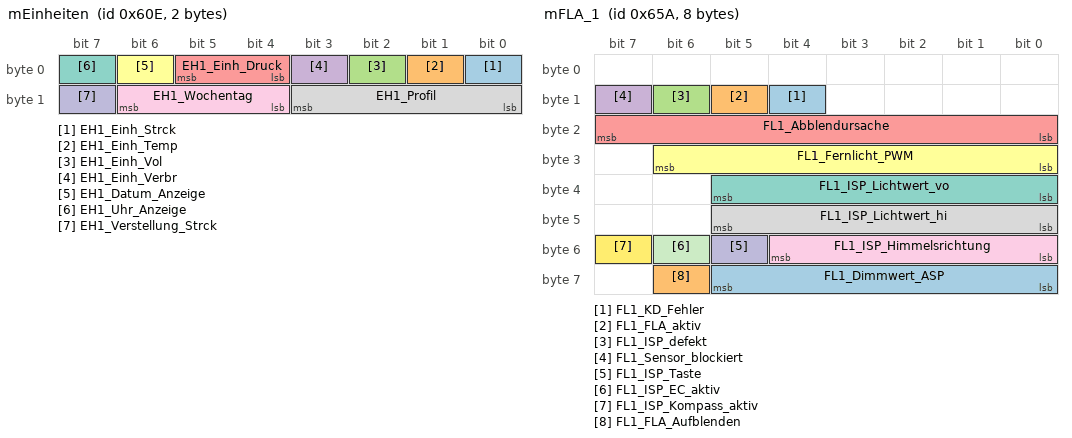
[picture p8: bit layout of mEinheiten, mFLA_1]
BO_ 1550 mEinheiten: 2 XXX
 SG_ EH1_Einh_Strck : 0|1@1+ (1,0) [0|1] "" XXX
 SG_ EH1_Einh_Temp : 1|1@1+ (1,0) [0|1] "" XXX
 SG_ EH1_Einh_Vol : 2|1@1+ (1,0) [0|1] "" Motor_Diesel
 SG_ EH1_Einh_Verbr : 3|1@1+ (1,0) [0|1] "" XXX
 SG_ EH1_Einh_Druck : 4|2@1+ (1,0) [0|3] "" XXX
 SG_ EH1_Datum_Anzeige : 6|1@1+ (1,0) [0|1] "" XXX
 SG_ EH1_Uhr_Anzeige : 7|1@1+ (1,0) [0|1] "" XXX
 SG_ EH1_Profil : 8|4@1+ (1,0) [0|15] "" XXX
 SG_ EH1_Wochentag : 12|3@1+ (1,0) [0|7] "" XXX
 SG_ EH1_Verstellung_Strck : 15|1@1+ (1,0) [0|1] "" XXX

BO_ 1406 mEM_Hybrid_1: 1 XXX
 SG_ EY1_KD_Fehler : 0|1@1+ (1,0) [0|1] "" Gateway_PQ35

BO_ 1626 mFLA_1: 8 XXX
 SG_ FL1_KD_Fehler : 12|1@1+ (1,0) [0|1] "" Gateway_PQ35
 SG_ FL1_FLA_aktiv : 13|1@1+ (1,0) [0|1] "" Gateway_PQ35
 SG_ FL1_ISP_defekt : 14|1@1+ (1,0) [0|1] "" Gateway_PQ35
 SG_ FL1_Sensor_blockiert : 15|1@1+ (1,0) [0|1] "" Gateway_PQ35
 SG_ FL1_Abblendursache : 16|8@1+ (1,0) [0|255] "" Gateway_PQ35
 SG_ FL1_Fernlicht_PWM : 24|7@1+ (1,0) [0|100] "Unit_PerCent" Gateway_PQ35
 SG_ FL1_ISP_Lichtwert_vo : 32|6@1+ (1,0) [0|61] "" Gateway_PQ35
 SG_ FL1_ISP_Lichtwert_hi : 40|6@1+ (1,0) [0|61] "" Gateway_PQ35
 SG_ FL1_ISP_Himmelsrichtung : 48|5@1+ (12,0) [0|348] "Unit_DegreOfArc" Gateway_PQ35
 SG_ FL1_ISP_Taste : 53|1@1+ (1,0) [0|1] "" Gateway_PQ35
 SG_ FL1_ISP_EC_aktiv : 54|1@1+ (1,0) [0|1] "" Gateway_PQ35
 SG_ FL1_ISP_Kompass_aktiv : 55|1@1+ (1,0) [0|1] "" Gateway_PQ35
 SG_ FL1_Dimmwert_ASP : 56|6@1+ (1.613,0) [0|100.006] "Unit_PerCent" Gateway_PQ35
 SG_ FL1_FLA_Aufblenden : 62|1@1+ (1,0) [0|1] "" Gateway_PQ35

CM_ SG_ 1416 MO7_Hoeheninfo "Korrekturfaktor Hoehe (1 entspricht 1013 mbar; 0,9 entspricht 1000m; 0,8 entspricht 2000m; 1,1 entspricht -1000m) | (Korrekturfaktor linear skaliert: delta Hoehe 1000m entsprechen delta Druck 101,3 mbar)";
CM_ SG_ 1416 MO7_LL_Solldz "Leerlauf-Solldrehzahl wurde angehoben, weil BSG_Last, Byte 2, Bit 0 oder Energiemananager 1, Byte 1, Bit 0 gesetzt war oder eine Klimaanforderung vorlag | Rueckmeldung Leerlauf-Solldrehzahl 1 fuer Lastmanagement";
CM_ SG_ 1416 MO7_Fehler_VBegr "Fehlerbit wird vom Motor-SG gesetzt, wenn dieses nicht in die Geschwindigkeits-begrenzung gehen kann, ein Fehler waehrend der v-Begrenzung auftritt oder v > v(begr.) - v(delta) | Geschwindigkeitsbegrenzung aktivierbar";
CM_ SG_ 1416 MO7_Sta_VBegr "Motor begrenzt aktuell die Geschwindigkeit des Fahrzeugs; Reaktion auf externe oder interne Anforderung | Statusbit Geschwindigkeitsbegrenzung aktiv";
CM_ SG_ 1416 MO7_Fehlereintr "Bei gesetztem Bit ist mindestens ein Kundendienstfehler eingetragen";
CM_ SG_ 1416 MO7_StaOeltemp "n.i.O. steht fuer Fehlerwert, ausserhalb des Messbereichs (ungenau), nicht verbaut oder noch kein aktueller Wert | Info aus Aufbereitung der TOG-Botschaft (nicht VW D1/Colorado, aber im Touareg GP/ D1 GP) | * Initwert 1 bei nicht verbautem Sensor oder nicht verfuegbarer Sensorinformation aus TOG-Botschaft | Fehlerstatus Oeltemperatur";
CM_ SG_ 1416 MO7_Sta_PTC "Rueckmeldung fuer das Lastmanagement, dass die PTC / Gluehstifte ausgeschaltet wurden";
CM_ SG_ 1416 MO7_DFM "Messwert Tastverhaeltnis DFM-Signal | (Nicht Audi D3 / C6!) (bei umgesetzter neuer Generatorschnittstelle wird das Signal im Colorado GP, D1GP/BY61x und Phaeton ab MJ07 nicht mehr bedient (abhaengig vom Motor-Projekt)) | Klemme_DFM";
CM_ SG_ 1416 MO7_Gradient_Dz "Differenz der Motordrehzahlen n(t) - n(t-20msec) aus der CAN-Botschaft 'Motor 1' | Motordrehzahlgradient";
CM_ SG_ 1416 MO7_GradientVorz "Positiv steht fuer steigende Drehzahl; Negativ fuer fallende Drehzahl | Vorzeichen Motordrehzahlgradient";
CM_ SG_ 1416 MO7_Ladedruckneu "Zur Anzeige im Kombi (z.Zt. nur Porsche Colorado, PQ35 Bi-Turbo, Audi RS6, TT-R) | Kombi im PQ35-Bi-Turbo und Audi RS6 und TT-R interpretiert die normierten CAN-Werte (0-254) als 0-100% der Anzeigeskala | (Aenderung Wertebereich fuer PQ35/46 mit V5.1.6 und Neuprojekte ohne Empfaenger) | | VW361/7: Nutzung als Anzeige ePowermeter (Rohwerte 1..253, 0..100,8%, Faktor 0.4, 0x0=Init/keine Anzeige, 0xFE=Funktion deaktiv/ausgegraut, 0xFF=Fehler/keine Anzeige) | VW120/7: Nutzung als Anzeige ePerformance (Rohwerte 1..253, 0..100,8%, Faktor 0.4, 0x0=Init/keine Anzeige, 0xFE=Funktion deaktiv/ausgegraut, 0xFF=Fehler/keine Anzeige)";
CM_ SG_ 1416 MO7_GenLdResp "Dient der Vermeidung der vom Generator erzeugten, mechanischen Lastspruengen und Leerlaufschwankungen durch traegere Ausregelung. Diese Massnahme darf nur kurzfristig bzw. als Notlauf wirksam sein (nicht VW D1/Colorado und PQ35/46). | Generator_Load_Response_Motor";
CM_ SG_ 1416 MO7_PTC_bereit "Bereitschaft dreistufiges PTC !!! (im AU716 und C6 ab 22/08) | Bereitschaft PTC-Heizung | 00 kein dreistufiges PTC verbaut | 0x 2x 300 W PTC-Stufe soll nicht eingeschaltet werden bzw. ist defekt (Diagnose) | 1x 2x 300 W PTC-Stufe soll eingeschaltet werden und ist bereit | x0 400 W PTC-Stufe soll nicht eingeschaltet werden bzw. ist defekt (Diagnose) | x1 400 W PTC-Stufe soll eingeschaltet werden und ist bereit";
CM_ SG_ 1416 MO7_Mot_weckfaehig "Anhand dieses Signals lernt das BSG, ob es zukuenftig bei bestimmten Ereignissen (Tuerkontakt, Anforderung Standheizung) ueber das Gateway das Wecken des Antriebs-CANs initieren soll. (nicht Audi) | Motor weckfaehig ueber CAN";
CM_ SG_ 1416 MO7_Zus_Kuehl "PQ25/35 (Diesel NAR): Ansteuerung Heckscheibenheizung | Nur Colorado V10 TDI: Zur Unterstuetzung der Motorkuehlung fordert Motor von Klima oder Zusatzheizung die Schaltung des Heizwasserkreislauf-Bypasses an (0: nein; 1: ja)";
CM_ SG_ 1416 MO7_SleepInd "Die Sleep-Bereitschaft wird nach Klemme 15 aus durch Setzen dieses Bits signalisiert | NMHigh-Teilnehmer der PQ35/46 muessen das Signal nach Kl.-15 aus weiterhin bedienen oder dauerhaft auf 1 = \"Sleep bereit\" setzen!";
CM_ SG_ 1416 MO7_RueckLLDz "Leerlauf-Solldrehzahl wurde aufgrund einer Lastmanagement-Anforderung (BSG_Last Byte 1, Bit 5 oder Energiemanager 1, Byte 1, Bit 1) auf die zweite Stufe angehoben | (nicht VW D1/Colorado) | Rueckmeldung_Leerlauf-Solldrehzahl 2";
CM_ SG_ 1416 MO7_Lastabwurf "Anforderung eines Lastabwurfs (fuer Notlauf): | Stufe 0: Keine Reduktion der Generatorspannung | Stufe 1: Generatorspannung = 13,3V | Stufe 2: Generatorspannung = 12,6V | Stufe 3: Generatorspannung = 11,8V | Anmerkung: Stufe 3 nur fuer aeussersten Notfall! | Schaltaktionen erfolgen seitens BEM mit Load-Response. | Solange die Generatorspannung reduziert ist, bleiben auch die Hochleistungsheizsysteme (Frontscheiben-heizung und PTC-Heizung) ausgeschaltet. Die Reduktion der Generatorspannung auf Stufe 2 und 3 darf max. fuer 10 sec aktiviert werden, danach wird das BEM die Generatorspannungsreduktion auf Stufe 1 setzen, solange bis Generatorspannung vom Motorsteuergeraet auf Stufe 0 gesetzt wird. | (nicht VW D1/Colorado, nicht PQ35/46);(im Touareg GP R5 TDI (fuer BSG)) | Lastabwurf (nur Generatorspannung)";
CM_ SG_ 1416 MO7_Gen_ein "Einschalten des Generators nach Motorstart. Einschalten evtl. mit Load-Response. | Anmerkung: Solange der Generator ausgeschaltet ist, bleiben auch die Hochleistungsheizsysteme deaktiviert. Spaetestens 5 s nach Motorstart wird der Generator zugeschaltet unabhaengig vom Einschaltsignal! | (im AU716 und C6 ab 22/08, nicht VW D1/Colorado ausser V6 TDI) | Im PQ25/35/46 wg. BEM im Gateway erforderlich.";
CM_ SG_ 1416 MO7_Lastabw_Heiz "Lastabwurf der Hochleistungsheizsysteme (z.B. Abschaltung von Frontscheibenheizung, PTC-Heizung und Heckscheibenheizung nach Motorstart und im Notfall). | Anmerkung: Der Lastabwurf der Hochleistungs-heizsysteme wird auch bei reduzierter Generatorspannung durchgefuehrt (siehe Byte 7 Bit 1,0). | (nicht VW D1/Colorado, ausser V6 TDI, nicht PQ35/46)";
CM_ SG_ 1416 MO7_StaGluehk "Einschaltzustand der Gluehkerzenheizung in Prozent (nicht VW D1/Colorado) | Gluehkerzen_Brennraum";
CM_ SG_ 1416 MO7_Oeltemp "realer Messbereich ca. -40..150 Grad | 0 fuer nicht verbaut | Info aus Aufbereitung der TOG-Botschaft (nicht VW D1/Colorado, aber im Touareg GP/D1 GP) | Oeltemperatur";
CM_ SG_ 644 MOB_Checksum "Pruefsumme mit Endwert 0x0, Definition im CAN Lastenheft (HS-CAN V4.2a, LS-CAN V1.42)";
CM_ SG_ 644 MOB_Zaehler "Freilaufender Botschaftszaehler gem. CAN-Lastenheft";
CM_ SG_ 644 MOB_Standby "Veranlasst Bremsbooster / die Bremse den Leerweg zu ueberfahren, bevor Bremsdruck erzeugt wird.";
CM_ SG_ 644 MOB_Anhaltewunsch "Erweiterung fuer ACC Follow to Stop | Anhaltewunsch";
CM_ SG_ 644 MOB_Freigabe "Anforderung Bremsstellgroesse (mMotor_Bremse: Byte 4,3) bzw. Summenradbremsmoment (mMotor_Bremse: Byte 5,4) wird freigegeben (Vorhalt) | Bremslicht wird angesteuert | Freigabe Bremsanforderung";
CM_ SG_ 644 MOB_Bremsstgr "Byte 3 LSB, Byte 4(2..0) MSB | Angeforderte (normierte) radbremsmomenten-proportionale Stellgroesse (im PQ46) | Anforderung Bremsstellgroesse";
CM_ SG_ 644 TSK_v_Begrenzung_aktiv "Limiter oder HGB begrenzen die Beschleunigung/das Moment";
CM_ SG_ 644 MOB_Bremsmom "13 Bit, in Byte 4 stehen die niederwertigsten 5 Bit, in Byte 5 die hoeherwertigen Bits | Alternativ zu Bremsdruckanforderung. Aeltere Systeme hoeren nur auf Bremsdruck, neue Systeme auf Radbremsmoment (im Touareg GP, D1GP, Golf GP, T5GP) | Anforderung Summenradbremsmoment";
CM_ SG_ 644 TSK_ax_Getriebe_01 "Beschleunigungsanforderung des Beschleunigungsreglers (u. a. fuer ACC, GRA, Speed Limiter). Das Signal wird vom Getriebe benutzt, um die von GRA/ACC geforderte Sollbeschleunigung in dem verbrauchsguenstigsten Gang einzustellen.";
CM_ SG_ 980 PL1_Checksumme "Pruefsumme mit Endwert 0x0, Definition im CAN Lastenheft (HS-CAN V4.2a, LS-CAN V1.42) | Achtung! Pruefsumme wird nur ueber Bytes 2-4 gebildet!";
CM_ SG_ 980 PL1_Zaehler "Ueberlaufender Botschaftszaehler, zur Lebenderkennung";
CM_ SG_ 980 PL1_Stat_PLA_ESP "Zustand der Statusmaschine des PLA fuer die korrespondierende Statusmaschine in der Bremse.";
CM_ SG_ 980 PL1_Bremsmoment "Anforderung eines Summenradbremsmomentes";
CM_ SG_ 980 PL1_Stat_PLA_EPS "16 Statuswerte (siehe LH PLA) | Status PLA EPS";
CM_ SG_ 980 PL1_LW_Soll "positiver Lenkradwinkel: nach links; negativer Lenkradwinkel: nach rechts | Solllenkwinkel";
CM_ SG_ 980 PL1_LW_Soll_Sign "Vorzeichen Solllenkwinkel";
CM_ SG_ 1488 SY1_Lenker "Info wird im Gateway-SG kodiert | Unkodierte PQ35/46-Gateway-SG geben 0 aus";
CM_ SG_ 1488 SY1_CAN_extern "zweipoliger Schalter, der den CAN-Antrieb auf den Diagnosestecker legt, ist geschlossen oder es werden Nutzdaten des CAN-Antrieb auf den Diagnose-CAN gespiegelt | CAN-Extern zugeschaltet";
CM_ SG_ 1488 SY1_Diag_Ant "mindestens ein Teilnehmer hat die Diagnoseeroeffnung auf dem CAN bestaetigt; im PQ35/46 derzeit nicht unterstuetzt | CAN-Antrieb in Diagnose";
CM_ SG_ 1488 SY1_Sleep_Komf "CAN-Komfort-Netzwerk schlaeft | VW526: Auf dem Sub_CAN_Infotainment wird durch das Gateway entsprechend des Zustandes der Busaktivitaet (NM) auf dem VW526_CAN_Dashboard gesendet (BAES): 0 = VW526_CAN_Dashboard aktiv; 1 = VW526_CAN_Dashboard in Busruhe";
CM_ SG_ 1488 SY1_Diag_Komf "mindestens ein Teilnehmer hat die Diagnoseeroeffnung auf dem Komfort-CAN bestaetigt; im PQ35/46 derzeit nicht unterstuetzt | CAN-Komfort in Diagnose";
CM_ SG_ 1488 SY1_Sleep_Info "CAN-Infotainment-Netzwerk schlaeft";
CM_ SG_ 1488 SY1_Diag_Info "mindestens ein Teilnehmer hat die Diagnoseeroeffnung auf dem Infotainment-CAN bestaetigt; im PQ35/46 derzeit nicht unterstuetzt | CAN-Infotainment in Diagnose";
CM_ SG_ 1488 SY1_CAN_Info "der CAN-Infotainment ist vom CAN-Komfort physikalisch getrennt";
CM_ SG_ 1488 SY1_Verbauinfo "ungueltig bedeutet: Verbauinformation ist noch nicht vollstaendig: Gateway nicht kodiert";
CM_ SG_ 1488 SY1_Fzg_Klasse "bei PQ24 wird z.Zt. A0-Klasse ausgegeben | Fahrzeug-Klasse";
CM_ SG_ 1488 SY1_Fzg_Marke "Marke wird im Gateway-SG kodiert: Unkodierte PQ35-Gateway-SG geben '1' aus | Fahrzeug-Marke";
CM_ SG_ 1488 SY1_Fzg_Derivat "Achtung: Derivate, die sich im Bordnetz nicht unterscheiden, werden ggfs. zusammengefasst | Derivat wird im Gateway-SG kodiert | Unkodierte PQ35/46-Gateway-SG geben 15d aus | 0 = Kurzheck oder Multivan | 1 = Stufenheck oder Nutzfzg. | 2 = Variant | 3 = Fliessheck | 4 = Coupe, Sportwagen | 5 = Cabrio, Roadstar, Spider | 6 = Offroad | 7 = CityVan, PickUp | 8 = MPV | 9 = sonstige | Nach Kenntnisstand des Senders | Fh = nicht bekannt";
CM_ SG_ 1488 SY1_Fzg_Gen "z.B. 5 fuer PQ35 | Fahrzeug-Generation";
CM_ SG_ 1488 SY1_Fzg_Index "Im PQ35/46 und AU210/AU316 derzeit nicht unterstuetzt: 15d fuer 'nicht bekannt' wird ausgegeben";
CM_ SG_ 1488 SY1_Tueren "Info wird im Gateway-SG kodiert | Unkodierte PQ35/46-Gateway-SG geben 0 aus";
CM_ SG_ 1488 SY1_Transportmode "1 = Transportmodus aktiv, funktionale Einschraenkungen bzw. Aenderungen fuer den Fzg.-Transport";
CM_ SG_ 1488 SY1_Fehlereintr "Bei gesetztem Bit ist mindestens ein KD-Fehler unter der Gateway Adresse abgelegt";
CM_ SG_ 1488 SY1_Komf_NV "CAN-Stand Komfort-Daten-Nebenversion | Anmerkung: das Gateway-Steuergeraet erfuellt die Funktionalitaet dieser CAN-Version | Hinweis PQ35/46/25: Mit Datenfestlegungsversion KCAN/ICAN >=3.9.x wird in diesem Signal der Wert auf \"9\" eingefroren und nicht weiter hochgezaehlt!";
CM_ SG_ 1488 SY1_Komf_HV "CAN-Stand Komfort-Daten-Hauptversion | Anmerkung: das Gateway-Steuergeraet erfuellt die Funktionalitaet dieser CAN-Version | Hinweis PQ35/46/25: Mit Datenfestlegungsversion KCAN/ICAN >=3.9.x wird in diesem Signal der Wert auf \"3\" eingefroren und nicht weiter hochgezaehlt!";
CM_ SG_ 1488 SY1_Ant_NV "CAN-Stand Antrieb-Daten-Nebenversion | Anmerkung: das Gateway-Steuergeraet erfuellt die Funktionalitaet dieser CAN-Version | Hinweis PQ35/46/25: Mit Datenfestlegungsversion ACAN >=5.9.x wird in diesem Signal der Wert auf \"9\" eingefroren und nicht weiter hochgezaehlt!";
CM_ SG_ 1488 SY1_Ant_HV "CAN-Stand Antrieb-Daten-Hauptversion | Anmerkung: das Gateway-Steuergeraet erfuellt die Funktionalitaet dieser CAN-Version | Hinweis PQ35/46/25: Mit Datenfestlegungsversion ACAN >=5.9.x wird in diesem Signal der Wert auf \"5\" eingefroren und nicht weiter hochgezaehlt!";
CM_ SG_ 1488 SY1_Relais_FAS_Zweig "FAS-Zweig (mit ACC, SWA,...) wird vom CAN-Antrieb ueber ein Relais abgetrennt: | 01: gewolltes Abschalten (zu schuetzende Kommunikation, z. B. im Hochlauf) | 10: nach zweimaligem BusOff bis \"Kl. 15\" aus abgetrennt | (im PQ46 und Touareg GP, D1GP/BY61x) | Hinweis: PQ46 bedient diese Bits auch dann, wenn die konkrete Hardwarevariante die Ansteuerung des Trennrelais nicht unterstuetzt | Fahrzeug-Konzepte ohne CAN-Relais schicken dauerhaft 00 (z. Zt. PQ35, VW47x, ...) | T5 GP mit Rekuperation / Start-Stopp: Bei einmal erkanntem Bus Off wird der Wert = 2 gesetzt u. nach 5 Sek stabilem Bus wieder zurueckgesetzt.";
CM_ SG_ 1488 SY1_ELV_Lock_Supply "Gateway gibt eine zusaetzliche Freigabe fuer die ELV (elektrische Lenkradverriegelung) (z. Zt. nur PQ46)";
CM_ SG_ 1488 SY1_QRS_Messmodus "1 = Quick-Ruhestrommessmodus (frueher: Fabrikmodus), Fzg geht innerhalb 1min in Ruhestrom | siehe auch Lastenheft LH_TRM_QRS";
CM_ SG_ 1488 SY1_NWDF_gueltig "Gueltigkeit der Netzwerk-Diagnose Freigabe (Byte 7, Bit 7)";
CM_ SG_ 1488 SY1_NWDF "Netzwerk-Diagnose Freigabe zur zentralen Aktivierung der Netzwerkdiagnose";
CM_ SG_ 1488 SY1_Notbrems_Status "Gateway erkennt Notbremssituation (z. Zt. nur PQ46, PQ35 ab MJ07) | Notbremsstatus";
CM_ SG_ 1838 NMH_BMS_Start_1 "Zustand Start (<--Sleep)";
CM_ SG_ 1838 NMH_BMS_Start_2 "Zustand Start (<--Prepare to Sleep)";
CM_ SG_ 1838 NMH_BMS_Normal_Mode_1 "Zustand Normal Mode (<-- Start)";
CM_ SG_ 1838 NMH_BMS_Normal_Mode_2 "Zustand Normal Mode (<-- Ready to Sleep)";
CM_ SG_ 1838 NMH_BMS_Car_WakeUp "Car WakeUp optional";
CM_ SG_ 1838 NMH_BMS_Per_WakeUp "Weckurasche Peripherie | 0 = wenn Funktionswakeup | 1 = CAN | 2 = P-Wakeup, Ursache nicht bekannt | 3 = KL 15 HW (falls vorhanden)";
CM_ SG_ 1838 NMH_BMS_Fkt_WakeUp "\"Weckursache Funktion\" | 0 = wenn Peripheriewakeup";
CM_ SG_ 1838 NMH_BMS_NM_aktiv_Klemme_15 "NM-Nachlaufursache, nicht \"Ready To Sleep\" | 1 = Klemme 15 ein";
CM_ SG_ 1838 NMH_BMS_NM_aktiv_Diagnose "NM-Nachlaufursache, nicht \"Ready To Sleep\" | 1 = Diagnose bei Kl 15 aus";
CM_ SG_ 1838 NMH_BMS_NM_aktiv_Start "NM-Nachlaufursache, nicht \"Ready To Sleep\" | 1 = Mindestaktivzeit Zustand \"Start\"";
CM_ SG_ 1838 NMH_BMS_NL_aktiv_4 "Nachlaufursache 4 | 1 = HV aktiv (Vorhalt)";
CM_ SG_ 1838 NMH_BMS_NL_aktiv_5 "Nachlaufursache 5";
CM_ SG_ 1838 NMH_BMS_NL_aktiv_6 "Nachlaufursache 6";
CM_ SG_ 1838 NMH_BMS_NL_aktiv_7 "Nachlaufursache 7";
CM_ SG_ 1838 NMH_BMS_NL_aktiv_8 "Nachlaufursache 8";
CM_ SG_ 1838 NMH_BMS_NL_0 "Nachlauf 0 | 1 = EEPROM Schreibzugriff";
CM_ SG_ 1838 NMH_BMS_NL_1 "Nachlauf 1 | 1 = Luefter aktiv";
CM_ SG_ 1838 NMH_BMS_NL_2 "Nachlauf 2";
CM_ SG_ 1838 NMH_BMS_NL_3 "Nachlauf 3";
CM_ SG_ 1838 NMH_BMS_NL_4 "Nachlauf 4";
CM_ SG_ 1838 NMH_BMS_NL_5 "Nachlauf 5";
CM_ SG_ 1838 NMH_BMS_NL_6 "Nachlauf 6";
CM_ SG_ 1838 NMH_BMS_NL_7 "Nachlauf 7";
CM_ SG_ 1838 NMH_BMS_TimeOut_Fehler "1 = Timeout Fehlerspeichereintrag";
CM_ SG_ 1838 NMH_BMS_CAN_Diag_deaktiv "1 = Keine CAN Bus bezogene Eigendiagnose";
CM_ SG_ 1838 NMH_BMS_KompSchutz "1 = Funktionseinschraenkung aufgrund Komponentenschutz / WFS aktiv";
CM_ SG_ 1838 NMH_BMS_Mute_Mode "1 = Funktionseinschraenkung aufgrund Mute Mode aktiv, nur VW";
CM_ SG_ 1838 NMH_BMS_Transport_Mode "1 = Funktionseinschraenkung aufgrund Transport Mode aktiv";
CM_ SG_ 1838 NMH_BMS_Abschaltstufe_aktiv "1 = Funktionsabschaltung wegen Abschaltstufe";
CM_ SG_ 1838 NMH_BMS_Eindraht_Fehler "1 = Eindrahtbetrieb erkannt";
CM_ SG_ 1839 NMH_EM_Start_1 "Zustand Start (<--Sleep)";
CM_ SG_ 1839 NMH_EM_Start_2 "Zustand Start (<--Prepare to Sleep)";
CM_ SG_ 1839 NMH_EM_Normal_Mode_1 "Zustand Normal Mode (<-- Start)";
CM_ SG_ 1839 NMH_EM_Normal_Mode_2 "Zustand Normal Mode (<-- Ready to Sleep)";
CM_ SG_ 1839 NMH_EM_Car_WakeUp "Car WakeUp optional";
CM_ SG_ 1839 NMH_EM_Per_WakeUp "Weckurasche Peripherie | 0 = wenn Funktionswakeup | 1 = CAN | 2 = P-Wakeup, Ursache nicht bekannt | 3 = KL 15 HW (falls vorhanden)";
CM_ SG_ 1839 NMH_EM_Fkt_WakeUp "\"Weckursache Funktion\" | 0 = wenn Peripheriewakeup";
CM_ SG_ 1839 NMH_EM_NM_aktiv_Klemme_15 "NM-Nachlaufursache, nicht \"Ready To Sleep\" | 1 = Klemme 15 ein";
CM_ SG_ 1839 NMH_EM_NM_aktiv_Diagnose "NM-Nachlaufursache, nicht \"Ready To Sleep\" | 1 = Diagnose bei Kl 15 aus";
CM_ SG_ 1839 NMH_EM_NM_aktiv_Start "NM-Nachlaufursache, nicht \"Ready To Sleep\" | 1 = Mindestaktivzeit Zustand \"Start\"";
CM_ SG_ 1839 NMH_EM_NL_aktiv_4 "Nachlaufursache 4 | 1 = HV-Entladung nicht moeglich";
CM_ SG_ 1839 NMH_EM_NL_aktiv_5 "Nachlaufursache 5";
CM_ SG_ 1839 NMH_EM_NL_aktiv_6 "Nachlaufursache 6";
CM_ SG_ 1839 NMH_EM_NL_aktiv_7 "Nachlaufursache 7";
CM_ SG_ 1839 NMH_EM_NL_aktiv_8 "Nachlaufursache 8";
CM_ SG_ 1839 NMH_EM_NL_0 "Nachlauf 0 | 1 = EEPROM Schreibzugriff";
CM_ SG_ 1839 NMH_EM_NL_1 "Nachlauf 1 | 1 = Ansteuerung der Kuehlpumpe an der LE";
CM_ SG_ 1839 NMH_EM_NL_2 "Nachlauf 2";
CM_ SG_ 1839 NMH_EM_NL_3 "Nachlauf 3";
CM_ SG_ 1839 NMH_EM_NL_4 "Nachlauf 4";
CM_ SG_ 1839 NMH_EM_NL_5 "Nachlauf 5";
CM_ SG_ 1839 NMH_EM_NL_6 "Nachlauf 6";
CM_ SG_ 1839 NMH_EM_NL_7 "Nachlauf 7";
CM_ SG_ 1839 NMH_EM_TimeOut_Fehler "1 = Timeout Fehlerspeichereintrag";
CM_ SG_ 1839 NMH_EM_CAN_Diag_deaktiv "1 = Keine CAN Bus bezogene Eigendiagnose";
CM_ SG_ 1839 NMH_EM_KompSchutz "1 = Funktionseinschraenkung aufgrund Komponentenschutz / WFS aktiv";
CM_ SG_ 1839 NMH_EM_Mute_Mode "1 = Funktionseinschraenkung aufgrund Mute Mode aktiv, nur VW";
CM_ SG_ 1839 NMH_EM_Transport_Mode "1 = Funktionseinschraenkung aufgrund Transport Mode aktiv";
CM_ SG_ 1839 NMH_EM_Abschaltstufe_aktiv "1 = Funktionsabschaltung wegen Abschaltstufe";
CM_ SG_ 1839 NMH_EM_Eindraht_Fehler "1 = Eindrahtbetrieb erkannt";
CM_ SG_ 1849 NMH_EPB_Start_1 "Zustand Start (<--Sleep)";
CM_ SG_ 1849 NMH_EPB_Start_2 "Zustand Start (<--Prepare to Sleep)";
CM_ SG_ 1849 NMH_EPB_Normal_Mode_1 "Zustand Normal Mode (<-- Start)";
CM_ SG_ 1849 NMH_EPB_Normal_Mode_2 "Zustand Normal Mode (<-- Ready to Sleep)";
CM_ SG_ 1849 NMH_EPB_Car_WakeUp "Car WakeUp optional";
CM_ SG_ 1849 NMH_EPB_Per_WakeUp "Weckurasche Peripherie | 0 = wenn Funktionswakeup | 1 = CAN | 2 = P-Wakeup, Ursache nicht bekannt | 3 = KL 15 HW (falls vorhanden) | 5 = Schalter EPB";
CM_ SG_ 1849 NMH_EPB_Fkt_WakeUp "\"Weckursache Funktion\" | 0 = wenn Peripheriewakeup";
CM_ SG_ 1849 NMH_EPB_NM_aktiv_Klemme_15 "NM-Nachlaufursache, nicht \"Ready To Sleep\" | 1 = Klemme 15 ein";
CM_ SG_ 1849 NMH_EPB_NM_aktiv_Diagnose "NM-Nachlaufursache, nicht \"Ready To Sleep\" | 1 = Diagnose bei Kl 15 aus";
CM_ SG_ 1849 NMH_EPB_NM_aktiv_Start "NM-Nachlaufursache, nicht \"Ready To Sleep\" | 1 = Mindestaktivzeit Zustand \"Start\"";
CM_ SG_ 1849 NMH_EPB_NL_aktiv_4 "Nachlaufursache 4";
CM_ SG_ 1849 NMH_EPB_NL_aktiv_5 "Nachlaufursache 5";
CM_ SG_ 1849 NMH_EPB_NL_aktiv_6 "Nachlaufursache 6";
CM_ SG_ 1849 NMH_EPB_NL_aktiv_7 "Nachlaufursache 7";
CM_ SG_ 1849 NMH_EPB_NL_aktiv_8 "Nachlaufursache 8";
CM_ SG_ 1849 NMH_EPB_NL_0 "Nachlauf 0";
CM_ SG_ 1849 NMH_EPB_NL_1 "Nachlauf 1";
CM_ SG_ 1849 NMH_EPB_NL_2 "Nachlauf 2";
CM_ SG_ 1849 NMH_EPB_NL_3 "Nachlauf 3";
CM_ SG_ 1849 NMH_EPB_NL_4 "Nachlauf 4";
CM_ SG_ 1849 NMH_EPB_NL_5 "Nachlauf 5";
CM_ SG_ 1849 NMH_EPB_NL_6 "Nachlauf 6";
CM_ SG_ 1849 NMH_EPB_NL_7 "Nachlauf 7";
CM_ SG_ 1849 NMH_EPB_TimeOut_Fehler "1 = Timeout Fehlerspeichereintrag";
CM_ SG_ 1849 NMH_EPB_CAN_Diag_deaktiv "1 = Keine CAN Bus bezogene Eigendiagnose";
CM_ SG_ 1849 NMH_EPB_KompSchutz "1 = Funktionseinschraenkung aufgrund Komponentenschutz / WFS aktiv";
CM_ SG_ 1849 NMH_EPB_Mute_Mode "1 = Funktionseinschraenkung aufgrund Mute Mode aktiv, nur VW";
CM_ SG_ 1849 NMH_EPB_Transport_Mode "1 = Funktionseinschraenkung aufgrund Transport Mode aktiv";
CM_ SG_ 1849 NMH_EPB_Abschaltstufe_aktiv "1 = Funktionsabschaltung wegen Abschaltstufe";
CM_ SG_ 1849 NMH_EPB_Eindraht_Fehler "1 = Eindrahtbetrieb erkannt";
CM_ SG_ 1824 NMH_GW_Start_1 "Zustand Start (<--Sleep)";
CM_ SG_ 1824 NMH_GW_Start_2 "Zustand Start (<--Prepare to Sleep)";
CM_ SG_ 1824 NMH_GW_Normal_Mode_1 "Zustand Normal Mode (<-- Start)";
CM_ SG_ 1824 NMH_GW_Normal_Mode_2 "Zustand Normal Mode (<-- Ready to Sleep)";
CM_ SG_ 1824 NMH_GW_Car_WakeUp "Car WakeUp optional";
CM_ SG_ 1824 NMH_GW_Per_WakeUp "Weckursache Peripherie | 0 = wenn Funktionswakeup | 1 = CAN | 2 = P-WakeUp, Ursache nicht bekannt | 3 = KL 15 HW (falls vorhanden) | 4 = Weckereignis am Antriebs-CAN-Transceiver erkannt | 5 = Weckereignis am Kombi-CAN-Transceiver erkannt | 6 = Weckereignis am Komfort-CAN-Transceiver erkannt | 7 = Weckereignis am Infotainment-CAN-Transceiver erkannt | 8 = Weckereignis am Extended-CAN-Transceiver erkannt | 9 = Weckereignis am LIN1-Transceiver erkannt | 10 = Weckereignis am LIN2-Transceiver erkannt | 11 = Weckereignis an der (Kombi-)Wakeup-Leitung | 12 = Weckereignis am Diagnose-CAN-Transceiver erkannt";
CM_ SG_ 1824 NMH_GW_Fkt_WakeUp "\"Weckursache Funktion\" | 0 = wenn Peripheriewakeup | 1 = Antriebs-CAN-Ereignis fordert diesen Bus | 2 = Kombi-CAN-Ereignis fordert diesen Bus | 3 = Komfort-CAN-Ereignis fordert diesen Bus | 4 = Infotainment-CAN-Ereignis fordert diesen Bus | 5 = Extended-CAN-Ereignis fordert diesen Bus | 6 = LIN1-CAN-Ereignis fordert diesen Bus | 7 = LIN2-CAN-Ereignis fordert diesen Bus";
CM_ SG_ 1824 NMH_GW_NM_aktiv_Klemme_15 "NM-Nachlaufursache, nicht \"Ready To Sleep\" | 1 = Klemme 15 ein";
CM_ SG_ 1824 NMH_GW_NM_aktiv_Diagnose "NM-Nachlaufursache, nicht \"Ready To Sleep\" | 1 = Diagnose bei Kl 15 aus";
CM_ SG_ 1824 NMH_GW_NM_aktiv_Start "NM-Nachlaufursache, nicht \"Ready To Sleep\" | 1 = Mindestaktivzeit Zustand \"Start\"";
CM_ SG_ 1824 NMH_GW_NL_aktiv_4 "Nachlaufursache 4 | 1 = ACAN-Nachlauf ueber Sleep-Indication-Bit (ACAN) | 1 = Kombi-Wakeup-Leitung aktiv (KombiCAN)";
CM_ SG_ 1824 NMH_GW_NL_aktiv_5 "Nachlaufursache 5 | 1 = Komfort-CAN fordert Antriebs-CAN (ACAN) | 1 = Kombi fordert Komfort oder Kombi-Sleep-Indication-Bit (KombiCAN)";
CM_ SG_ 1824 NMH_GW_NL_aktiv_6 "Nachlaufursache 6 | 1 = Antriebs-CAN-Nachlauf (inkl. NM-High) (KombiCAN)";
CM_ SG_ 1824 NMH_GW_NL_aktiv_7 "Nachlaufursache 7 | 1 = Infortainment-CAN aktiv (KombiCAN)";
CM_ SG_ 1824 NMH_GW_NL_aktiv_8 "Nachlaufursache 8 | 1 = Komfort-CAN aktiv (KombiCAN)";
CM_ SG_ 1824 NMH_GW_NL_0 "Nachlauf 0";
CM_ SG_ 1824 NMH_GW_NL_1 "Nachlauf 1";
CM_ SG_ 1824 NMH_GW_NL_2 "Nachlauf 2";
CM_ SG_ 1824 NMH_GW_NL_3 "Nachlauf 3";
CM_ SG_ 1824 NMH_GW_NL_4 "Nachlauf 4";
CM_ SG_ 1824 NMH_GW_NL_5 "Nachlauf 5";
CM_ SG_ 1824 NMH_GW_NL_6 "Nachlauf 6";
CM_ SG_ 1824 NMH_GW_NL_7 "Nachlauf 7";
CM_ SG_ 1824 NMH_GW_TimeOut_Fehler "1 = Timeout Fehlerspeichereintrag";
CM_ SG_ 1824 NMH_GW_CAN_Diag_deaktiv "1 = Keine CAN Bus bezogene Eigendiagnose";
CM_ SG_ 1824 NMH_GW_KompSchutz "1 = Funktionseinschraenkung aufgrund Komponentenschutz / WFS aktiv";
CM_ SG_ 1824 NMH_GW_Mute_Mode "1 = Funktionseinschraenkung aufgrund Mute Mode aktiv, nur VW";
CM_ SG_ 1824 NMH_GW_Transport_Mode "1 = Funktionseinschraenkung aufgrund Transport Mode aktiv";
CM_ SG_ 1824 NMH_GW_Abschaltstufe_aktiv "1 = Funktionsabschaltung wegen Abschaltstufe";
CM_ SG_ 1824 NMH_GW_Eindraht_Fehler "1 = Eindrahtbetrieb erkannt";
CM_ SG_ 1826 NMH_Getriebe_Start_1 "Zustand Start (<--Sleep)";
CM_ SG_ 1826 NMH_Getriebe_Start_2 "Zustand Start (<--Prepare to Sleep)";
CM_ SG_ 1826 NMH_Getriebe_Normal_Mode_1 "Zustand Normal Mode (<-- Start)";
CM_ SG_ 1826 NMH_Getriebe_Normal_Mode_2 "Zustand Normal Mode (<-- Ready to Sleep)";
CM_ SG_ 1826 NMH_Getriebe_Car_WakeUp "Car WakeUp optional";
CM_ SG_ 1826 NMH_Getriebe_Per_WakeUp "Weckurasche Peripherie | 0 = wenn Funktionswakeup | 1 = CAN | 2 = P-Wakeup, Ursache nicht bekannt | 3 = KL 15 HW (falls vorhanden)";
CM_ SG_ 1826 NMH_Getriebe_Fkt_WakeUp "\"Weckursache Funktion\" | 0 = wenn Peripheriewakeup";
CM_ SG_ 1826 NMH_Getriebe_NM_aktiv_Klemme_15 "NM-Nachlaufursache, nicht \"Ready To Sleep\" | 1 = Klemme 15 ein";
CM_ SG_ 1826 NMH_Getriebe_NM_aktiv_Diagnose "NM-Nachlaufursache, nicht \"Ready To Sleep\" | 1 = Diagnose bei Kl 15 aus";
CM_ SG_ 1826 NMH_Getriebe_NM_aktiv_Start "NM-Nachlaufursache, nicht \"Ready To Sleep\" | 1 = Mindestaktivzeit Zustand \"Start\"";
CM_ SG_ 1826 NMH_Getriebe_NL_aktiv_4 "Nachlaufursache 4 | SQ100: kein Fahrzeugstillstand erkannt";
CM_ SG_ 1826 NMH_Getriebe_NL_aktiv_5 "Nachlaufursache 5 | SQ100: keine Freigabe Anzeige-Bedien-Konzept (ABK)";
CM_ SG_ 1826 NMH_Getriebe_NL_aktiv_6 "Nachlaufursache 6 | SQ100: keine Freigabe Schalt-Kupplungs-Applikation (ZFSCW)";
CM_ SG_ 1826 NMH_Getriebe_NL_aktiv_7 "Nachlaufursache 7";
CM_ SG_ 1826 NMH_Getriebe_NL_aktiv_8 "Nachlaufursache 8";
CM_ SG_ 1826 NMH_Getriebe_NL_0 "Nachlauf 0";
CM_ SG_ 1826 NMH_Getriebe_NL_1 "Nachlauf 1";
CM_ SG_ 1826 NMH_Getriebe_NL_2 "Nachlauf 2";
CM_ SG_ 1826 NMH_Getriebe_NL_3 "Nachlauf 3";
CM_ SG_ 1826 NMH_Getriebe_NL_4 "Nachlauf 4";
CM_ SG_ 1826 NMH_Getriebe_NL_5 "Nachlauf 5";
CM_ SG_ 1826 NMH_Getriebe_NL_6 "Nachlauf 6";
CM_ SG_ 1826 NMH_Getriebe_NL_7 "Nachlauf 7";
CM_ SG_ 1826 NMH_Getriebe_TimeOut_Fehler "1 = Timeout Fehlerspeichereintrag";
CM_ SG_ 1826 NMH_Getriebe_CAN_Diag_deaktiv "1 = Keine CAN Bus bezogene Eigendiagnose";
CM_ SG_ 1826 NMH_Getriebe_KompSchutz "1 = Funktionseinschraenkung aufgrund Komponentenschutz / WFS aktiv";
CM_ SG_ 1826 NMH_Getriebe_Mute_Mode "1 = Funktionseinschraenkung aufgrund Mute Mode aktiv, nur VW";
CM_ SG_ 1826 NMH_Getriebe_Transport_Mode "1 = Funktionseinschraenkung aufgrund Transport Mode aktiv";
CM_ SG_ 1826 NMH_Getriebe_Abschaltstufe_aktiv "1 = Funktionsabschaltung wegen Abschaltstufe";
CM_ SG_ 1826 NMH_Getriebe_Eindraht_Fehler "1 = Eindrahtbetrieb erkannt";
CM_ SG_ 1834 NMH_GE_02_Start_1 "Zustand Start (<--Sleep)";
CM_ SG_ 1834 NMH_GE_02_Start_2 "Zustand Start (<--Prepare to Sleep)";
CM_ SG_ 1834 NMH_GE_02_Normal_Mode_1 "Zustand Normal Mode (<-- Start)";
CM_ SG_ 1834 NMH_GE_02_Normal_Mode_2 "Zustand Normal Mode (<-- Ready to Sleep)";
CM_ SG_ 1834 NMH_GE_02_Car_WakeUp "Car WakeUp optional";
CM_ SG_ 1834 NMH_GE_02_Per_WakeUp "Weckurasche Peripherie | 0 = wenn Funktionswakeup | 1 = CAN | 2 = P-Wakeup, Ursache nicht bekannt | 3 = KL 15 HW (falls vorhanden)";
CM_ SG_ 1834 NMH_GE_02_Fkt_WakeUp "\"Weckursache Funktion\" | 0 = wenn Peripheriewakeup";
CM_ SG_ 1834 NMH_GE_02_NM_aktiv_Klemme_15 "NM-Nachlaufursache, nicht \"Ready To Sleep\" | 1 = Klemme 15 ein";
CM_ SG_ 1834 NMH_GE_02_NM_aktiv_Diagnose "NM-Nachlaufursache, nicht \"Ready To Sleep\" | 1 = Diagnose bei Kl 15 aus";
CM_ SG_ 1834 NMH_GE_02_NM_aktiv_Start "NM-Nachlaufursache, nicht \"Ready To Sleep\" | 1 = Mindestaktivzeit Zustand \"Start\"";
CM_ SG_ 1834 NMH_GE_02_N_Haltephase "Nachlaufursache 4";
CM_ SG_ 1834 NMH_GE_02_Positionsanzeige "NM-Nachlaufursache, nicht \"Ready To Sleep\" | 1 = Positionsanzeige aktiv";
CM_ SG_ 1834 NMH_GE_02_kein_NL "kein Lokaler Nachlauf";
CM_ SG_ 1834 NMH_GE_02_NL_Daten_EEPROM "Lokaler Nachlauf";
CM_ SG_ 1834 NMH_GE_02_NL_Drucksens "Lokaler Nachlauf";
CM_ SG_ 1834 NMH_GE_02_NL_Abtrieb "Lokaler Nachlauf";
CM_ SG_ 1834 NMH_GE_02_NL_Waehlhebel "Lokaler Nachlauf";
CM_ SG_ 1834 NMH_GE_02_NL_Wegfahrsperre "Lokaler Nachlauf";
CM_ SG_ 1834 NMH_GE_02_Signalfehler "1 = Signal Fehlerspeichereintrag";
CM_ SG_ 1834 NMH_GE_02_TimeOut_Fehler "1 = Timeout Fehlerspeichereintrag";
CM_ SG_ 1834 NMH_GE_02_CAN_Diag_deaktiv "1 = Keine CAN Bus bezogene Eigendiagnose";
CM_ SG_ 1834 NMH_GE_02_KompSchutz "1 = Funktionseinschraenkung aufgrund Komponentenschutz / WFS aktiv";
CM_ SG_ 1834 NMH_GE_02_Mute_Mode "1 = Funktionseinschraenkung aufgrund Mute Mode aktiv, nur VW";
CM_ SG_ 1834 NMH_GE_02_Transport_Mode "1 = Funktionseinschraenkung aufgrund Transport Mode aktiv";
CM_ SG_ 1834 NMH_GE_02_Abschaltstufe_aktiv "1 = Funktionsabschaltung wegen Abschaltstufe";
CM_ SG_ 1834 NMH_GE_02_Eindraht_Fehler "1 = Eindrahtbetrieb erkannt";
CM_ SG_ 1836 NMH_Lademanager_Start_1 "Zustand Start (<--Sleep)";
CM_ SG_ 1836 NMH_Lademanager_Start_2 "Zustand Start (<--Prepare to Sleep)";
CM_ SG_ 1836 NMH_Lademanager_Normal_Mode_1 "Zustand Normal Mode (<-- Start)";
CM_ SG_ 1836 NMH_Lademanager_Normal_Mode_2 "Zustand Normal Mode (<-- Ready to Sleep)";
CM_ SG_ 1836 NMH_Lademanager_Car_WakeUp "Car WakeUp optional";
CM_ SG_ 1836 NMH_Lademanager_Per_WakeUp "Weckurasche Peripherie | 0 = wenn Funktionswakeup | 1 = CAN | 2 = P-Wakeup, Ursache nicht bekannt | 3 = KL 15 HW (falls vorhanden) | 4 = Taster Sofortladen";
CM_ SG_ 1836 NMH_Lademanager_Fkt_WakeUp "\"Weckursache Funktion\" | 0 = wenn Peripheriewakeup";
CM_ SG_ 1836 NMH_Lademanager_NM_aktiv_Klemme_15 "NM-Nachlaufursache, nicht \"Ready To Sleep\" | 1 = Klemme 15 ein";
CM_ SG_ 1836 NMH_Lademanager_NM_aktiv_Diagnose "NM-Nachlaufursache, nicht \"Ready To Sleep\" | 1 = Diagnose bei Kl 15 aus";
CM_ SG_ 1836 NMH_Lademanager_NM_aktiv_Start "NM-Nachlaufursache, nicht \"Ready To Sleep\" | 1 = Mindestaktivzeit Zustand \"Start\"";
CM_ SG_ 1836 NMH_Lademanager_NL_aktiv_4 "Nachlaufursache 4 | Ladezeitberechnung";
CM_ SG_ 1836 NMH_Lademanager_NL_aktiv_5 "Nachlaufursache 5 | Ladevorgang aktiv";
CM_ SG_ 1836 NMH_Lademanager_NL_aktiv_6 "Nachlaufursache 6 | Batterietemperierung aktiv";
CM_ SG_ 1836 NMH_Lademanager_NL_aktiv_7 "Nachlaufursache 7";
CM_ SG_ 1836 NMH_Lademanager_NL_aktiv_8 "Nachlaufursache 8";
CM_ SG_ 1836 NMH_Lademanager_NL_0 "Nachlauf 0";
CM_ SG_ 1836 NMH_Lademanager_NL_1 "Nachlauf 1";
CM_ SG_ 1836 NMH_Lademanager_NL_2 "Nachlauf 2";
CM_ SG_ 1836 NMH_Lademanager_NL_3 "Nachlauf 3";
CM_ SG_ 1836 NMH_Lademanager_NL_4 "Nachlauf 4";
CM_ SG_ 1836 NMH_Lademanager_NL_5 "Nachlauf 5";
CM_ SG_ 1836 NMH_Lademanager_NL_6 "Nachlauf 6";
CM_ SG_ 1836 NMH_Lademanager_NL_7 "Nachlauf 7";
CM_ SG_ 1836 NMH_Lademanager_TimeOut_Fehler "1 = Timeout Fehlerspeichereintrag";
CM_ SG_ 1836 NMH_Lademanager_CAN_Diag_deaktiv "1 = Keine CAN Bus bezogene Eigendiagnose";
CM_ SG_ 1836 NMH_Lademanager_KompSchutz "1 = Funktionseinschraenkung aufgrund Komponentenschutz / WFS aktiv";
CM_ SG_ 1836 NMH_Lademanager_Mute_Mode "1 = Funktionseinschraenkung aufgrund Mute Mode aktiv, nur VW";
CM_ SG_ 1836 NMH_Lademanager_Transport_Mode "1 = Funktionseinschraenkung aufgrund Transport Mode aktiv";
CM_ SG_ 1836 NMH_Lademanager_Abschaltstufe_aktiv "1 = Funktionsabschaltung wegen Abschaltstufe";
CM_ SG_ 1836 NMH_Lademanager_Eindraht_Fehler "1 = Eindrahtbetrieb erkannt";
CM_ SG_ 1825 NMH_MO_Start_1 "Zustand Start (<--Sleep)";
CM_ SG_ 1825 NMH_MO_Start_2 "Zustand Start (<--Prepare to Sleep)";
CM_ SG_ 1825 NMH_MO_Normal_Mode_1 "Zustand Normal Mode (<-- Start)";
CM_ SG_ 1825 NMH_MO_Normal_Mode_2 "Zustand Normal Mode (<-- Ready to Sleep)";
CM_ SG_ 1825 NMH_MO_Car_WakeUp "Car WakeUp optional";
CM_ SG_ 1825 NMH_MO_Per_WakeUp "Weckurasche Peripherie | 0 = wenn Funktionswakeup | 1 = CAN | 2 = P-Wakeup, Ursache nicht bekannt | 3 = KL 15 HW (falls vorhanden) | 4 = HW-Weckleitung (alte MED9) | 5 = Ladestecker gesteckt";
CM_ SG_ 1825 NMH_MO_Fkt_WakeUp "\"Weckursache Funktion\" | 0 = wenn Peripheriewakeup";
CM_ SG_ 1825 NMH_MO_NM_aktiv_Klemme_15 "NM-Nachlaufursache, nicht \"Ready To Sleep\" | 1 = Klemme 15 ein";
CM_ SG_ 1825 NMH_MO_NM_aktiv_Diagnose "NM-Nachlaufursache, nicht \"Ready To Sleep\" | 1 = Diagnose bei Kl 15 aus";
CM_ SG_ 1825 NMH_MO_NM_aktiv_Start "NM-Nachlaufursache, nicht \"Ready To Sleep\" | 1 = Mindestaktivzeit Zustand \"Start\"";
CM_ SG_ 1825 NMH_MO_NL_aktiv_4 "Nachlaufursache 4 | 1 = EKP Vorlauf";
CM_ SG_ 1825 NMH_MO_NL_aktiv_5 "Nachlaufursache 5 | 1 = Standheizungs-Betrieb";
CM_ SG_ 1825 NMH_MO_NL_aktiv_6 "Nachlaufursache 6 | 1 = Hybrid-Manager deaktiviert alle Hochvolt-Verbraucher fuer stromloses Oeffnen der Batterieschuetze";
CM_ SG_ 1825 NMH_MO_NL_aktiv_7 "Nachlaufursache 7 | 1 = Innenraumklimatisierung (VW360/7) | 1 = Betankung (Drucktank VW361/7)";
CM_ SG_ 1825 NMH_MO_NL_aktiv_8 "Nachlaufursache 8 | 1 = LM_Systemanforderung (EGolf)";
CM_ SG_ 1825 NMH_MO_NL_0 "Nachlauf 0";
CM_ SG_ 1825 NMH_MO_NL_1 "Nachlauf 1 | 1 = Kuehlerluefter Steuerung / Zusatzwasserpumpe";
CM_ SG_ 1825 NMH_MO_NL_2 "Nachlauf 2 | 1 = Diagnosefunktionen aktiv";
CM_ SG_ 1825 NMH_MO_NL_3 "Nachlauf 3 | 1 = Wegfahrsperre aktiv";
CM_ SG_ 1825 NMH_MO_NL_4 "Nachlauf 4 | 1 = EEPROM Zugriffe RAM/ROM Tests";
CM_ SG_ 1825 NMH_MO_NL_5 "Nachlauf 5 | 1 = Sonstige Nachlaeufe aktiv";
CM_ SG_ 1825 NMH_MO_NL_6 "Nachlauf 6";
CM_ SG_ 1825 NMH_MO_NL_7 "Nachlauf 7";
CM_ SG_ 1825 NMH_MO_TimeOut_Fehler "1 = Timeout Fehlerspeichereintrag";
CM_ SG_ 1825 NMH_MO_CAN_Diag_deaktiv "1 = Keine CAN Bus bezogene Eigendiagnose";
CM_ SG_ 1825 NMH_MO_KompSchutz "1 = Funktionseinschraenkung aufgrund Komponentenschutz / WFS aktiv";
CM_ SG_ 1825 NMH_MO_Mute_Mode "1 = Funktionseinschraenkung aufgrund Mute Mode aktiv, nur VW";
CM_ SG_ 1825 NMH_MO_Transport_Mode "1 = Funktionseinschraenkung aufgrund Transport Mode aktiv";
CM_ SG_ 1825 NMH_MO_Abschaltstufe_aktiv "1 = Funktionsabschaltung wegen Abschaltstufe";
CM_ SG_ 1825 NMH_MO_Eindraht_Fehler "1 = Eindrahtbetrieb erkannt";
CM_ SG_ 1654 BAP_Data_Anzeige "ASG: KBI => FSG: ACC, VZA, HCA, SWA";
CM_ SG_ 1754 BAP_Data_OPS "FSG: OPS => ASG: RNS, Radio, KBI";
CM_ SG_ 1656 BAP_Data_OPS_02 "FSG: OPS => ASG: RNS, KBI";
CM_ SG_ 946 BEM_HYB_DC_uMinLV "Abregelgrenze: minimal erlaubte Bordnetzspannung im Hochsetzbetrieb (Hybrid)";
CM_ SG_ 946 BEM_HYB_DC_uSollLV "Sollwert fuer die Bordnetzspannung im Tiefsetzbetrieb vom Traktionsnetz ins Bordnetz (Hybrid)";
CM_ SG_ 946 BEM_Freigabe_HV_Ladung "Signalisierung, dass ein Aufladen der HV-Batterie aus der 12V-Seite heraus moeglich ist. | Praemissen: | Ladegeraet an 12V-Seite oder | guter Ladezustand der 12V-Batterie";
CM_ SG_ 946 BEM_Hybrid_Info "Einschraenkung des Hybridbetriebs durch Energiemanagement | 0 = keine Einschraenkung des Hybridbetriebs durch das Energiemanagement [Hybridfreigabe] | 1 = Motorstart ueber 12V-Starter nur bei v = 0 km/h moeglich | 2 = kein Motorstart ueber 12V-Starter nach elektrischem Fahrtbetrieb moeglich | [Motorstart nur ueber E-Maschine] | 3 = Systemfehler";
CM_ SG_ 946 BEM_NV_NachladAnf "Bei Energiedefizit auf der Niedervoltseite wird der Lademanager aufgefordert, die Niedervoltseite nachzuladen.";
CM_ SG_ 946 NVEM_Fahrbereit_Handshake "Signal wird verwendet, wenn eine NV-Batteriepruefung vor Herstellen der Fahrbereitschaft erfolgen muss";
CM_ SG_ 946 BEM_Generatordiagnose "Ansteuerung Generatorwarnleuchte im Kombi | 0 = keine Anzeige | 1 = Ladekontrollanzeige ein (Vorhalt) | 2 = rotes Batteriesymbol und Text (Generator defekt) | 3 = Text (Hybrid DC-DC-Wandler defekt)";
CM_ SG_ 946 BEM_Ladezustand "Ladezustand der Niedervoltbatterie";
CM_ SG_ 945 DC_HYB_iAktLV "Momentanwert: Strom vom DC/DC-Wandler in das Bordnetz";
CM_ SG_ 945 DC_HYB_iAktReserveLV "Momentanwert: Stromreserve vom DC/DC-Wandler in Richtung 12V-Bordnetz";
CM_ SG_ 945 DC_HYB_uAktLV "Momentanwert: NV-Bordnetzspannung am DC/DC-Wandler";
CM_ SG_ 945 DC_HYB_LangsRegelung "aktueller Regelmode des DC/DC-Wandlers. | 0: normale Regelung | 1: langsame Regelung";
CM_ SG_ 945 DC_HYB_Abregelung_Temperatur "Abregelung aufgrund Uebertemperatur im Leistungsteil (Hochtemperatur-Abregelung)";
CM_ SG_ 945 DC_HYB_Fehler_RedLeistung "Fehler: eingeschraenkte Leistungsfaehigkeit des DC/DC-Wandlers aufgrund eines internen Fehlers";
CM_ SG_ 945 DC_HYB_Fehler_intern "Fehler: DC/DC-Wandler ist aufgrund eines internen Hardware-Fehlers abgeschaltet";
CM_ SG_ 945 DC_HYB_Fehler_Spannung "Abschaltung aufgrund Unter-/Ueberspannung auf der Ein-/Ausgangsseite";
CM_ SG_ 945 DC_TiefsetzBereit "Kennzeichnung, dass der DC/DC-Wandler im Sollmodus Tiefsetzbetrieb ist und auf Spannungsvorgabe wartet. Fehler werden ueber das Signal DC_HYB_Fehler_intern signalisiert.";
CM_ SG_ 945 DC_HYB_Auslastungsgrad "Momentanwert: Auslastung DC/DC (DFM Signal), entspricht I_akt / I_max";
CM_ SG_ 18 GSG_WFS_RND "Zufallszahl Anfrage";
CM_ SG_ 19 WFS_GSG_SIG_S "Signatur Antwort";
CM_ SG_ 19 WFS_GSG_Status_Antwort "0 bei Dummy-Antwort, wenn WFS n.i.O. ist";
CM_ SG_ 19 WFS_GSG_Status_Lesespule "nur Info; keine Auswirkung auf Freischaltung";
CM_ SG_ 19 WFS_GSG_Status_Schluessel "nur Info; keine Auswirkung auf Freischaltung";
CM_ SG_ 19 WFS_GSG_Status_Anfrage "Signatur der Anfrage i.O.?";
CM_ SG_ 19 WFS_GSG_Status_P_Klasse "Leistungsklasse i.O.?";
CM_ SG_ 17 WFS_MSG1_SIG_S "Signatur Antwort";
CM_ SG_ 17 WFS_MSG1_Status_Antwort "0 bei Dummy-Antwort, wenn WFS n.i.O. ist";
CM_ SG_ 17 WFS_MSG1_Status_Lesespule "nur Info; keine Auswirkung auf Freischaltung";
CM_ SG_ 17 WFS_MSG1_Status_Schluessel "nur Info; keine Auswirkung auf Freischaltung";
CM_ SG_ 17 WFS_MSG1_Status_Anfrage "Signatur der Anfrage i.O.?";
CM_ SG_ 17 WFS_MSG1_Status_P_Klasse "Leistungsklasse i.O.?";
CM_ SG_ 21 WFS_MSG2_SIG_S "Signatur Antwort";
CM_ SG_ 21 WFS_MSG2_Status_Antwort "0 bei Dummy-Antwort, wenn WFS n.i.O. ist";
CM_ SG_ 21 WFS_MSG2_Status_Lesespule "nur Info; keine Auswirkung auf Freischaltung";
CM_ SG_ 21 WFS_MSG2_Status_Schluessel "nur Info; keine Auswirkung auf Freischaltung";
CM_ SG_ 21 WFS_MSG2_Status_Anfrage "Signatur der Anfrage i.O.?";
CM_ SG_ 21 WFS_MSG2_Status_P_Klasse "Leistungsklasse i.O.?";
CM_ SG_ 23 WFS_MSG3_SIG_S "Signatur Antwort";
CM_ SG_ 23 WFS_MSG3_Status_Antwort "0 bei Dummy-Antwort, wenn WFS n.i.O. ist";
CM_ SG_ 23 WFS_MSG3_Status_Lesespule "nur Info; keine Auswirkung auf Freischaltung";
CM_ SG_ 23 WFS_MSG3_Status_Schluessel "nur Info; keine Auswirkung auf Freischaltung";
CM_ SG_ 23 WFS_MSG3_Status_Anfrage "Signatur der Anfrage i.O.?";
CM_ SG_ 23 WFS_MSG3_Status_P_Klasse "Leistungsklasse i.O.?";
CM_ SG_ 25 WFS_MSG4_SIG_S "Signatur Antwort";
CM_ SG_ 25 WFS_MSG4_Status_Antwort "0 bei Dummy-Antwort, wenn WFS n.i.O. ist";
CM_ SG_ 25 WFS_MSG4_Status_Lesespule "nur Info; keine Auswirkung auf Freischaltung";
CM_ SG_ 25 WFS_MSG4_Status_Schluessel "nur Info; keine Auswirkung auf Freischaltung";
CM_ SG_ 25 WFS_MSG4_Status_Anfrage "Signatur der Anfrage i.O.?";
CM_ SG_ 25 WFS_MSG4_Status_P_Klasse "Leistungsklasse i.O.?";
CM_ SG_ 1879 ISO_ACC_Req_Data "ISO Request Kanal";
CM_ SG_ 1985 ISO_ACC_Resp_Data "ISO Response Kanal";
CM_ SG_ 1892 ISO_AGA_Req_Data "ISO-Request-Kanal Aussensound | | Verwendet auch als TP 2.0 Empfangskanal 1 fuer Allrad_SG";
CM_ SG_ 1813 ISO_Airbag_01_Req_Data "ISO Request Kanal";
CM_ SG_ 1919 ISO_Airbag_01_Resp_Data "ISO Response Kanal";
CM_ SG_ 1807 ISO_Allrad_Req_Data "ISO Request Kanal";
CM_ SG_ 1913 ISO_Allrad_Resp_Data "ISO Response Kanal";
CM_ SG_ 1874 ISO_EPB_Req_Data "ISO Request Kanal | | ACHTUNG: CAN-Identifier identisch zu mTP_Dyn_RKA_Plus_1 | Im SVW411 als Request-ID ISO-TP fuer die Parkbremse verwendet! | Im Audi TTNF als dynamischer TP2.0-Kanal fuer RKA-Plus verwendet!";
CM_ SG_ 1980 ISO_EPB_Resp_Data "ISO Response Kanal";
CM_ SG_ 1802 ISO_EPH_Req_Data "ISO Request Kanal";
CM_ SG_ 1908 ISO_EPH_Resp_Data "ISO Response Kanal";
CM_ SG_ 1840 ISO_FLA_Req_Data "ISO Request Kanal";
CM_ SG_ 1946 ISO_FLA_Resp_Data "ISO Response Kanal";
CM_ SG_ 1795 ISO_Funktionaler_Req_Abgas "ISO Request Kanal";
CM_ SG_ 2015 ISO_OBD_Funktionaler_Req_Data "ISO Request Kanal";
CM_ SG_ 2017 ISO_Getriebe_01_Req_Data "ISO Request Kanal";
CM_ SG_ 2025 ISO_Getriebe_01_Resp_Data "ISO Response Kanal";
CM_ SG_ 1891 ISO_Gurtmikro_Req_Data "ISO Request Kanal";
CM_ SG_ 1997 ISO_Gurtmikro_Resp_Data "ISO Response Kanal";
CM_ SG_ 1860 ISO_Ladegeraet_Req_Data "ISO Request Kanal | | Achtung: ID zugleich TP 2.0 Empfangskanal 1 fuer MotorSlave_SG 1 oder LPG-SG";
CM_ SG_ 1810 ISO_Lenkhilfe_Req_Data "ISO Request Kanal";
CM_ SG_ 1916 ISO_Lenkhilfe_Resp_Data "ISO Response Kanal";
CM_ SG_ 1832 ISO_LIN_Flash_Req_Data "ISO Request Kanal";
CM_ SG_ 1938 ISO_LIN_Flash_Resp_Data "ISO Response Kanal";
CM_ SG_ 1876 ISO_LWRAFS_Req_Data "ISO Request Kanal";
CM_ SG_ 1982 ISO_LWRAFS_Resp_Data "ISO Response Kanal";
CM_ SG_ 2016 ISO_MO_01_Req_Data "ISO Request Kanal";
CM_ SG_ 2024 ISO_MO_01_Resp_Data "ISO Response Kanal";
CM_ SG_ 2018 ISO_OBD_01_Req_Data "PQ35, VW611: Motor_Slave";
CM_ SG_ 2026 ISO_OBD_01_Resp_Data "PQ35, VW611: Motor_Slave";
CM_ SG_ 2019 ISO_OBD_02_Req_Data "AU714: Getriebe_02";
CM_ SG_ 2027 ISO_OBD_02_Resp_Data "AU714: Getriebe_02";
CM_ SG_ 2021 ISO_OBD_04_Req_Data "VW120/7, VW253/7, VW36x/7, VW019, AU210/7: BMS";
CM_ SG_ 2029 ISO_OBD_04_Resp_Data "VW120/7, VW253/7, VW36x/7, VW019, AU210/7: BMS";
CM_ SG_ 2022 ISO_OBD_05_Req_Data "VW120/7, VW253/7, VW36x/7, VW019, AU210/7: EMotor";
CM_ SG_ 2030 ISO_OBD_05_Resp_Data "VW120/7, VW253/7, VW36x/7, VW019, AU210/7: EMotor";
CM_ SG_ 1822 ISO_Quersperre_Req_Data "ISO Request Kanal";
CM_ SG_ 1928 ISO_Quersperre_Resp_Data "ISO Response Kanal";
CM_ SG_ 1386 ACA_Checksum "Pruefsumme mit Endwert 0x0, Definition im CAN Lastenheft (HS-CAN V4.2a, LS-CAN V1.42)";
CM_ SG_ 1386 ACA_StaACC "Status nur zur Anzeige im Kombi | Achtung: ACC aktiv nicht im Sinne Status ADR | siehe Schnittstellenbeschreibung ACC/Kombi";
CM_ SG_ 1386 ACA_ID_StaACC "siehe Schnittstellenbeschreibung ACC/Kombi | Index ACC System Status";
CM_ SG_ 1386 ACA_Fahrerhinw "Zur optischen Information des Fahrers, dass Systemgrenze erreicht ist | Ansteuerung optischer Fahrerhinweis";
CM_ SG_ 1386 ACA_AnzDisplay "siehe Schnittstellenbeschreibung ACC/Kombi | Anzeige Display";
CM_ SG_ 1386 ACA_Zeitluecke "Anzeige im Kombi, wenn ADR aktiv oder ADR passiv | Gesetzte Zeitluecke";
CM_ SG_ 1386 ACA_V_Wunsch "Anzeige im Kombi, wenn ADR aktiv oder ADR passiv | Wunschgeschwindigkeit";
CM_ SG_ 1386 ACA_kmh_mph "ADR zeigt damit an, dass es mit der Anzeige im Kombi synchronisiert arbeitet | Info Einheit der Geschwindigkeit";
CM_ SG_ 1386 ACA_Akustik1 "Loest niederprioren Gong (\"leise\") im Kombi aus und ist im Kombi bei aktuellem Bild mit Anzeigeprioritaet 2 gekoppelt. Mitteldisplay wird in jedem Fall angezeigt | Ansteuerung Akustik 1";
CM_ SG_ 1386 ACA_Akustik2 "Loest Summer (\"laut\") im Kombi aus und ist im Kombi bei aktuellem Bild mit Anzeigeprioritaet 1 gekoppelt. Mitteldisplay wird in jedem Fall angezeigt | Ansteuerung Akustik 2";
CM_ SG_ 1386 ACA_PrioDisp "siehe Schnittstellenbeschreibung ACC/Kombi | Anzeige Display Prioritaet";
CM_ SG_ 1386 ACA_gemZeitl "Aktuelle Distanz zum vorausfahrenden Fahrzeug, auf das geregelt wird; die Einheit ist Stufen der Zeitluecke (vgl. Gesetzte Zeitluecke) | Zeitluecke gemessen";
CM_ SG_ 1386 ACA_ACC_Verz "Bei gesetztem Bit befindet sich das ACC Fahrzeug in einer Verzoegerung | ACC Verzoegerung";
CM_ SG_ 1386 ACA_StaGRA "primaere GRA Zustandsanzeige | GRA System Status";
CM_ SG_ 1386 ACA_ID_StaGRA "GRA Zustandsanzeige Ergaenzung | Index GRA Status Anzeige";
CM_ SG_ 1386 ACA_Codierung "Sendercodierung";
CM_ SG_ 1386 ACA_Tachokranz "Zusaetzliche Status- und Einstellbereichsanzeige im Tachometer (z. Zt. nur Touareg GP) | Tachokranz";
CM_ SG_ 1386 ACA_Aend_Zeitluecke "Anzeige der Zeitlueckenaenderung im Kombiinstrument (z. Zt. nur Touareg GP) | Anzeige Aenderung Zeitluecke";
CM_ SG_ 1386 ACA_Zaehler "Definition im CAN-Lastenheft | Botschaftszaehler";
CM_ SG_ 872 ACS_Checksum "Pruefsumme mit Endwert 0x0, Definition im CAN Lastenheft (HS-CAN V4.2a, LS-CAN V1.42)";
CM_ SG_ 872 ACS_Zaehler "Definition im CAN Lastenheft | Botschaftszaehler";
CM_ SG_ 872 ACS_Sta_ADR "Aktivierung ADR durchlaeuft Algorithmus, in den der GRA_Status (Motor 2) eingeht | Status ADR";
CM_ SG_ 872 ACS_ADR_Schub "ADR Schub";
CM_ SG_ 872 ACS_Schubabsch "Verhinderung Schubabschaltung";
CM_ SG_ 872 ACS_StSt_Info "Stopp-Freigabe/Start-Anforderung fuer den Start-Stopp-Koordinator;0 = Motorlauf langfristig nicht notwendig [Stoppfreigabe] ;1 = Motoranlauf nicht zwingend notwendig [Stoppverbot, keine Startanforderung];2 = Motoranlauf zwingend notwendig [Startanforderung];3 = Systemfehler | ACC Start Stopp Info";
CM_ SG_ 872 ACS_MomEingriff "Das Setzen dieses Bits bedeutet, dass kein Momenteneingriff erfolgen soll. Wird fuer Komfortfunktion verwendet | Verhinderung Momenteneingriff";
CM_ SG_ 872 ACS_Typ_ACC "Motor plausibilisiert seine eigene Kodierung. | | Sollte ausschliesslich die Funktion FrontAssist verbaut sein, wird ueber den Status \"ACC_nicht_verbaut\" die Nichtverfuegbarkeit des ACC-Systems allen empfangenden Partnersteuergeraeten angezeigt.";
CM_ SG_ 872 ACS_FreigSollB "Beschleunigungsanforderung in Byte 4,5 wird mit diesem Bit aktiviert | Freigabe Sollbeschleunigung";
CM_ SG_ 872 ACS_Sollbeschl "Byte 4 LSB, Byte 5 (2...0) MSB Eingriff in Motorsteuergeraet (aktiv, wenn Byte 3 Bit 7 gesetzt ist) | Sollbeschleunigung";
CM_ SG_ 872 ACS_Anhaltewunsch "Erweiterung fuer ACC Follow to Stop (im PQ46) | Anhaltewunsch";
CM_ SG_ 872 ACS_Fehler "Bei gesetztem Bit ist mindestens ein Kundendienstfehler eingetragen | Fehlerspeichereintrag ACC-SG";
CM_ SG_ 872 ACS_zul_Regelabw "Betrag der regulaer zulaessigen Regelabweichung zwischen angefordeter und umgesetzter Sollbeschleunigung;Wird fuer Komfortfunktion verwendet | Zulaessige Regelabweichung";
CM_ SG_ 872 ACS_max_AendGrad "Betrag des max. zulaessigen Gradienten zur Aenderung der aktuell umgesetzten Sollbeschleunigung;Wird fuer Komfortfunktion verwendet | Maximaler Aenderungsgradient";
CM_ SG_ 1688 AFZ_ParaSW_L "Erst wenn AFS Master und die beiden Scheinwerfer parametriesiert/codiert sind ist die Grundeinstellung moeglich";
CM_ SG_ 1688 AFZ_ParaSW_R "Erst wenn AFS Master und die beiden Scheinwerfer parametriesiert/codiert sind ist die Grundeinstellung moeglich";
CM_ SG_ 1688 AFZ_Modus "Touristenloesung ueber Anpassung anwaehlbar (Schwenken deaktiviert)";
CM_ SG_ 1688 AFZ_Init "Initialisierungslauf beider Kurvenlicht Schrittmotoren, erfolgt defaultmaessig beim Motorstart";
CM_ SG_ 1688 AFZ_SafePos "AFS Sicherheitsposition beider Scheinwerfer des dyn. Kurvenlichts";
CM_ SG_ 1688 AFZ_IstPosMot_L "(Gespiegelt vom AFS-Subbus) | Position des Aktuators in Prozent des maximalen Stellweges; | vor dem Initialisierungslauf (z. Zt. Motorstart) wird der Initwert ausgegeben | 0% ist die Position (auf Block) des Schrittmotors | 100% maximaler Verstellweg des Schrittmotors (nicht die Grenze des Scheinwerfers!)";
CM_ SG_ 1688 AFZ_IstPosMot_R "(Gespiegelt vom AFS-Subbus) | Position des Aktuators in Prozent des maximalen Stellweges; | vor dem Initialisierungslauf (z. Zt. Motorstart) wird der Initwert ausgegeben | 0% ist die Position (auf Block) des Schrittmotors | 100% maximaler Verstellweg des Schrittmotors (nicht die Grenze des Scheinwerfers!)";
CM_ SG_ 1688 AFZ_Soll_EVG "100% entsprechen 35 Watt | Die Last schaltet nur das ILM";
CM_ SG_ 1688 AFZ_IstDimAbLi "(Gespiegelt vom AFS-Subbus) | 0% - 100% bezogen auf die Versorgungsspannung des linken Moduls";
CM_ SG_ 1688 AFZ_IstDimAbRe "(Gespiegelt vom AFS-Subbus) | 0% - 100% bezogen auf die Versorgungsspannung des rechten Moduls";
CM_ SG_ 1688 AFZ_StaLamp_L "Statusmeldung des Lampenausfalls fuer das linke statische Kurvenlicht";
CM_ SG_ 1688 AFZ_StaLamp_R "Statusmeldung des Lampenausfalls fuer das rechte statische Kurvenlicht";
CM_ SG_ 1360 AB2_Checksum "Pruefsumme mit Endwert 0x0, Definition im CAN Lastenheft (HS-CAN V4.2a, LS-CAN V1.42)";
CM_ SG_ 1360 AB2_Beleg_HF "ueber Gurt-Wickelband | Belegungserkennung hinten Fahrer";
CM_ SG_ 1360 AB2_Beleg_HBF "ueber Gurt-Wickelband | Belegungserkennung hinten Beifahrer";
CM_ SG_ 1360 AB2_Beleg_HM "ueber Gurt-Wickelband | Belegungserkennung hinten Mitte";
CM_ SG_ 1360 AB2_Beleg_BF "Wird in US-Steuergeraeten Audi8R/VW8R/AB8.4E++ bedient, optional bei der RdW, falls SBE-EuroNCAP entschieden wird | Belegungserkennung Beifahrersitz";
CM_ SG_ 1360 AB2_OOP_Fa "000 | 001 | 01X (z.Zt. Vorhalt) | 100 Ausl. mit 100 % | 101 Ausl. mit 70 % | 110 Ausl. mit 30 % | 111 (z.Zt. Vorhalt) | OOP Fahrer (reserviert)";
CM_ SG_ 1360 AB2_OOP_BF "000 | 001 | 01X (z.Zt. Vorhalt) | 100 Ausl. mit 100 % | 101 Ausl. mit 70 %;110 Ausl. mit 30 %;111 (z.Zt. Vorhalt) | OOP Beifahrer (reserviert)";
CM_ SG_ 1360 AB2_Sta_BF "Der Fahrer soll bei einem Statuswechsel des Beifahrerairbags (ausgeloest durch die Beifahrerinsassenerkennung oder den Schluesselschlossschalter) aufmerksam gemacht werden durch eine Anzeige im Kombi!;Nur Audi, gueltig fuer: AB2 (4-Tuerer AU352), B7, C6, D3 | Aufmerksamkeitserhoehung Beifahrerairbagstatus";
CM_ SG_ 1360 AB2_Gurt_2FaS "Gurtwarnung 2. Reihe Fahrerseite fuer EuroNCAP 6. Stern";
CM_ SG_ 1360 AB2_Gurt_2BfS "Gurtwarnung 2. Reihe Beifahrerseite fuer EuroNCAP 6. Stern";
CM_ SG_ 1360 AB2_Gurt_2Mi "Gurtwarnung 2. Reihe Mitte fuer EuroNCAP 6. Stern";
CM_ SG_ 1360 AB2_Gurt_3FaS "Gurtwarnung 3. Reihe Fahrerseite fuer EuroNCAP 6. Stern";
CM_ SG_ 1360 AB2_Gurt_3BfS "Gurtwarnung 3. Reihe Beifahrerseite fuer EuroNCAP 6. Stern";
CM_ SG_ 1360 AB2_Gurt_3Mi "Gurtwarnung 3. Reihe Mitte fuer EuroNCAP 6. Stern";
CM_ SG_ 1360 AB_Deaktivierung_HV "Deaktivierung des HV-Systems und der HV-Teilnehmer im Crash (u.a. Hybrid- und Elektrofahrzeuge) | Nur unterstuetzt im VW120/7 u. VW253/7 in Kombination mit AB2_Zaehler!";
CM_ SG_ 1360 AB_Abschaltanf_SIH_BF "Die Insassenerkennung auf der Beifahrerseite fordert bei Uebertemperatur eine Abschaltung der Sitzheizung an. Die Uebertemperatur kann bei niederohmigen Nebenschluessen der Sitzheizungsmatte als Folge von zu hohem resultierenden Strom auftreten.";
CM_ SG_ 1360 AB2_Zaehler "ueberlaufender Botschaftszaehler zur Lebenderkennung | Nur unterstuetzt im VW120/7 u. VW253/7 in Kombination mit AB_Deaktivierung_HV!";
CM_ SG_ 1404 BY1_KD_Fehler "Info fuer Diagnose | bei gesetztem Bit befindet sich mindestens ein Kundendienstfehler im Fehlerspeicher";
CM_ SG_ 1404 BMS_Gesamtst_Spgfreiheit "0 = Funktion nicht aktiviert | 1 = HV-System spannungsfrei (U_Zwkr von BMS, LE und Ladegeraet < 20V, DCLadestecker nicht gesteckt und Service Disconnect entriegelt) | 2 = HV-System nicht spannungsfrei (U_Zwkr von BMS, LE und Ladegeraet >= 20V, Ladestecker gesteckt oder Service Disconnect verriegelt) | 3 = Fehler (z. B. Fehler in der eigenen Sensorik, ein Signal fehlt oder Fehler in Leistungselektronik oder Ladegeraet)";
CM_ SG_ 1404 BY1_Zaehler "Ueberlaufender Botschaftszaehler, zur Lebenderkennung";
CM_ SG_ 1404 BMS_Temperatur "battery temperature / Momentanwert: Temperatur der Traktionsbatterie";
CM_ SG_ 1404 BMS_Temperierung_Anf "Temperierungsbedarf der HV-Batterie";
CM_ SG_ 1404 BMS_As_Entladezaehler_Ueberlauf "Wird beim ersten Ueberlauf von BMS_As_Entladezaehler auf 1 gesetzt. Reset ueber KL15-Wechsel";
CM_ SG_ 1404 BMS_As_Entladezaehler "Signal zur Berechnung des Lastprofils durch die RWB";
CM_ SG_ 1404 BMS_IstVorlaufTemperatur "Aktuelle Vorlauftemperatur der Batterie";
CM_ SG_ 1404 BY1_Checksumme "Pruefsumme mit Endwert 0x0, Definition im CAN Lastenheft (HS-CAN V4.2a, LS-CAN V1.42)";
CM_ SG_ 1524 BCN_Checksumme "Pruefsumme mit Endwert 0x0, Definition im CAN Lastenheft (HS-CAN V4.2a, LS-CAN V1.42)";
CM_ SG_ 1524 BCN_BremsenVar "Bremsenvariante | 00H keine Variante hinterlegt";
CM_ SG_ 1524 BCN_AntriebsVar "Ausgegeben wird die Antriebsvariante zur Codierplausibilisierung im ESP-Steuergeraet";
CM_ SG_ 1528 Module_ID_5 "APS";
CM_ SG_ 1528 Data_Byte_1_5 "Festlegung der Datenbytes siehe CAN Data Exchange Function Datenfestlegung | Datenbyte 1";
CM_ SG_ 1528 Data_Byte_2_5 "Festlegung der Datenbytes siehe CAN Data Exchange Function Datenfestlegung | Datenbyte 2";
CM_ SG_ 1528 Data_Byte_3_5 "Festlegung der Datenbytes siehe CAN Data Exchange Function Datenfestlegung | Datenbyte 3";
CM_ SG_ 1528 Data_Byte_4_5 "Festlegung der Datenbytes siehe CAN Data Exchange Function Datenfestlegung | Datenbyte 4";
CM_ SG_ 1528 Data_Byte_5_5 "Festlegung der Datenbytes siehe CAN Data Exchange Function Datenfestlegung | Datenbyte 5";
CM_ SG_ 1530 Module_ID_19 "APS";
CM_ SG_ 1530 Data_Byte_1_19 "Festlegung der Datenbytes siehe CAN Data Exchange Function Datenfestlegung | Datenbyte 1";
CM_ SG_ 1530 Data_Byte_2_19 "Festlegung der Datenbytes siehe CAN Data Exchange Function Datenfestlegung | Datenbyte 2";
CM_ SG_ 1530 Data_Byte_3_19 "Festlegung der Datenbytes siehe CAN Data Exchange Function Datenfestlegung | Datenbyte 3";
CM_ SG_ 1530 Data_Byte_4_19 "Festlegung der Datenbytes siehe CAN Data Exchange Function Datenfestlegung | Datenbyte 4";
CM_ SG_ 1530 Data_Byte_5_19 "Festlegung der Datenbytes siehe CAN Data Exchange Function Datenfestlegung | Datenbyte 5";
CM_ SG_ 1504 CL1_LL_Dz "1 = Drehzahlanhebung, Forderung an den Motor bei zu geringer Kaelte- / Heizleistung | Signal fuer Drehzahlanhebung";
CM_ SG_ 1504 CL1_Fa_Zuheiz "1 = Zuheizerfreigabe | Fahrerwunsch Zuheizer";
CM_ SG_ 1504 CL1_Hecksch "1 = Heckscheibenheizung ein | Hzg Heckscheibe angesteuert (Power)";
CM_ SG_ 1504 CL1_Frontsch "1 = Frontscheibenheizung ein | Hzg Frontscheibe angesteuert (Power)";
CM_ SG_ 1504 CL1_Kompressor "1 = Kompressor ein, Zustand incl. 140ms Vorsteuerung, Info an das MSG: Kompressor EIN, PQ34_lang: Anforderung an das MSG: Kompressor einschalten";
CM_ SG_ 1504 CL1_Heizleist "1, wenn beide Temperaturklappen auf Kaltanschlag stehen, an MSG um hohe Kuehlmitteltemp. zu fahren | Keine Heizleistung gewuenscht";
CM_ SG_ 1504 CL1_Sta_Moment "1 = veraltet; Ermittlung des Moments nicht moelich (z.B. keine Drehzahl, kein Kaeltemitteldruck)' | Kompressormoment veraltet";
CM_ SG_ 1504 CL1_Sta_Druck "1 = veraltet; bei Klemme 15 aus | Kaeltemitteldruck veraltet";
CM_ SG_ 1504 CL1_Aussentemp "FF = Fehler | Ansauglufttemperatur fuer die Climaanlage | im PQ25 kein Temperatursensor im Wasserkasten | Aussentemperatur ungefiltert Wasserkasten";
CM_ SG_ 1504 CL1_Druck "FF = Fehler | Kaeltemitteldruck";
CM_ SG_ 1504 CL1_Kompr_Last "Verlustmoment der Klimaanlage in Nm | Lastinfo: Kompressorzustand";
CM_ SG_ 1504 CL1_Gebl_last "Lastinfo: Geblaeseansteuerung";
CM_ SG_ 1504 CL1_Luefter "Ansteuerung des Kuehlerluefters in Prozent";
CM_ SG_ 1504 CL1_Einheit_Temp "1 = Klimaanlage zeigt die Temperatur in Fahrenheit an, Temp auf dem Bus in degC !!";
CM_ SG_ 1504 CL1_AC_Schalter "1 = AC-Schalter gedrueckt | Abbildung des AC-Schalters";
CM_ SG_ 1504 CL1_WAPU_Zuschaltung "1 = Wasserpumpe ist nicht zugeschaltet | Ein/ Ausschalten der Wasserpumpe zwecks CO2 Einsparung";
CM_ SG_ 1504 CL1_Restwaerme "1 = Restwaermefunktion ist aktiviert, Statusinformation, d.h. Geblaeselast ist vorhanden";
CM_ SG_ 1504 CL1_PTC_Hzg "0 = PTC Heizung aus | 1 = Leistung PTC Heizung <= 25% | 2 = Leistung PTC Heizung <= 50% | 3 = Leistung PTC Heizung <= 75% | 4 = Leistung PTC Heizung <= 100% | Status der Klima PTC Heizung";
CM_ SG_ 1504 CL1_Fehlereintr "1 = mindestens 1 Kundendienstfehler ist im Fehlerspeicher eingetragen";
CM_ SG_ 1504 KL_Thermomanagement "Stufen des Thermomanagements";
CM_ SG_ 1504 KL_VK_Betriebsdauer "Durch Klima SG berechnete Betriebsdauer der Standklimatisierung fuer Zielzeitlogik.";
CM_ SG_ 1432 DA1_Daempferreg "Bei Statusaenderung wird der Soll-Zustand ausgegeben. Der Status beschreibt einen Parametersatz: Temporaere Aenderungen der Daempfereinstellungen werden hier nicht abgebildet | (nicht Audi D3) | Status Daempferregelung";
CM_ SG_ 1432 DA1_Warnlampe "Dient der Anzeige von Warnungen im Kombiinstrument | (nicht Colorado) | (nicht Audi D3) | Gelbe Warnlampe";
CM_ SG_ 1432 DA1_Taster "Nach Betaetigung des Tasters wird das Fahrwerk-Menue im ZAB (D1) aktiviert | (nicht Audi D3) | Charisma-Taster (PQ35/46)";
CM_ SG_ 1432 DA1_Systemstatus "Bit wird gesetzt, wenn interne Funktionspruefung i.O. und System generell funktionsfaehig ist. | (nicht Audi D3)";
CM_ SG_ 1432 DA1_Fehlereintr "im Fehlerspeicher der Daempferregelung gibt es einen aktuellen (statischen oder sporadischen) Kundendienst-Fehlerspeichereintrag";
CM_ SG_ 1432 DA1_Textbits "Die Textbits werden verwendet, um im Kombi Texte oder Bilder fuer die Daempferregelung darzustellen | (nicht Colorado) (nicht Audi D3) | Text 1: \"CDC Sport 1\" | Text 2: \"CDC Sport 2\" | Text 3: \"CDC Basis\" | Text 4: \"CDC Komfort\"";
CM_ SG_ 1432 DA1_Zaehler "Freilaufender Botschaftszaehler";
CM_ SG_ 1432 DA1_ESP_Zwang "(nicht Daempfer PQ35/46) | ESP-Zwangszuschaltung";
CM_ SG_ 1432 DA1_LampPruef "Aufpruefbit Warnlampe";
CM_ SG_ 1432 DA1_Charisma "Gateway erkennt, ob im Daempfer Charisma aktiv ist und liest ggf. Tasterzustand (Byte 1, Bit 4) ein";
CM_ SG_ 1432 DA1_Checksumme "Pruefsumme mit Endwert 0x0, Definition im CAN Lastenheft (HS-CAN V4.2a, LS-CAN V1.42)";
CM_ SG_ 1550 EH1_Einh_Strck "0 = km | 1 = mls | Einheit Streckenanzeige (km/mls)";
CM_ SG_ 1550 EH1_Einh_Temp "0 = degC | 1 = degF | Einheit Temperaturanzeige ( degC / degF )";
CM_ SG_ 1550 EH1_Einh_Vol "0 = liter | 1 = gallons | Einheit_Volumen ( liter / gallons)";
CM_ SG_ 1550 EH1_Einh_Verbr "0= Strecke / Volumen | 1 = Volumen / Strecke | Einheit Verbrauchsanzeige ( Vol./Strecke ; Strecke/Vol.)";
CM_ SG_ 1550 EH1_Einh_Druck "0 = Druckangabe in bar | 1 = Druckangabe in psi | 2 = n.n. | 3 = Druck in kPa | Einheit Druck (bar/psi/_/kPa)";
CM_ SG_ 1550 EH1_Datum_Anzeige "Anzeigeformat des Datums (Europaeisch = 0, amerikanisch = 1)";
CM_ SG_ 1550 EH1_Uhr_Anzeige "0 = 24 Stunden Anzeige | 1 = 12 Stunden Anzeige | Anzeige 12 24 Stunden";
CM_ SG_ 1550 EH1_Profil "aktuelle Profilnummer";
CM_ SG_ 1550 EH1_Wochentag "0 =Init, 1=Mo, 2=Di, 3=Mi, 4=Do, 5=Fr, 6=Sa, 7=So | Wochentag";
CM_ SG_ 1550 EH1_Verstellung_Strck "Das Kombi kann mittels Personalisierung die Einheit fuer die Strecke (km/mls) verstellen. | Verstellung der Einheit Strecke via Personalisierung";
CM_ SG_ 1406 EY1_KD_Fehler "Info fuer Diagnose | bei gesetztem Bit befindet sich mindestens ein Kundendienstfehler im Fehlerspeicher";
CM_ SG_ 1626 FL1_KD_Fehler "mindestens ein Fehler ist im Kundendienstfehlerspeicher eingetragen | (separates FLA-SG Inhibit 200ms)";
CM_ SG_ 1626 FL1_FLA_aktiv "FLA aktiv | (separates FLA-SG Inhibit 200ms)";
CM_ SG_ 1626 FL1_ISP_defekt "FLA Innenspiegel defekt | interner Fehler | (separates FLA-SG Inhibit 200ms)";
CM_ SG_ 1626 FL1_Sensor_blockiert "FLA Sensor blockiert | Sichtbeeintraechtigung CMOS-Kamera | (separates FLA-SG Inhibit 200ms)";
CM_ SG_ 1626 FL1_Abblendursache "FLA Abblendursache | 0x0 keine | 0x1 entgegenkommendes Fahrzeug | 0x2 vorausfahrendes Fahrzeug | 0x4 Geschwindigkeitslimit unterschritten | 0x8 Ort erkannt | 0x10 Umgebungshelligkeit generell zu hell, Abblendlicht aus | 0x20 Nebel erkannt | 0x40 Uebertemperatur Imager | 0x80 Verzoegerungsbedingung | 0xFF Fehler | (separates FLA-SG Inhibit 20ms)";
CM_ SG_ 1626 FL1_Fernlicht_PWM "FLA PWM Vorgabe Fernlicht | (separates FLA-SG Inhibit 20ms)";
CM_ SG_ 1626 FL1_ISP_Lichtwert_vo "Innenspiegel: Lichtwert vorne | ISP Lichtwert vorne | (separates FLA-SG Inhibit 200ms)";
CM_ SG_ 1626 FL1_ISP_Lichtwert_hi "Innenspiegel: Lichtwert hinten | ISP Lichtwert hinten | (separates FLA-SG Inhibit 200ms)";
CM_ SG_ 1626 FL1_ISP_Himmelsrichtung "Himmelsrichtung Kompass im EC Spiegel | Wertebereich 0-29 (12deg-Schritte, 0-348deg) | 12 x Wert [Grad] | 0x1E nicht verfuegbar / Init | 0x1F Fehler | ISP Himmelsrichtung | (separates FLA-SG Inhibit 200ms)";
CM_ SG_ 1626 FL1_ISP_Taste "Innenspiegel Taste betaetigt | ISP Taste betaetigt | (separates FLA-SG Inhibit 200ms)";
CM_ SG_ 1626 FL1_ISP_EC_aktiv "Status Innenspiegel (EC-Spiegel) | ISP EC aktiv | (separates FLA-SG Inhibit 200ms)";
CM_ SG_ 1626 FL1_ISP_Kompass_aktiv "Status Kompass Innenspiegel | ISP Kompass aktiv | (separates FLA-SG Inhibit 200ms)";
CM_ SG_ 1626 FL1_Dimmwert_ASP "Dimmwertvorgabe fuer Aussenspiegel | 0x0 - 0x3E = Dimmwert (0-62 = 0-100%) | ISP Dimmwert ASP | (separates FLA-SG Inhibit 20ms)";
CM_ SG_ 1626 FL1_FLA_Aufblenden "FLA Aufblenden | (separates FLA-SG Inhibit 20ms)";
BA_DEF_ BO_ "GenMsgCycleTime" INT 0 65535;
BA_DEF_ BO_ "GenMsgSendType" STRING ;
BA_DEF_ SG_ "GenSigSendType" STRING ;
BA_DEF_DEF_ "GenMsgCycleTime" 0;
BA_DEF_DEF_ "GenMsgSendType" "";
BA_DEF_DEF_ "GenSigSendType" "";
BA_ "GenMsgCycleTime" BO_ 1416 20;
BA_ "GenMsgSendType" BO_ 1416 "Cyclic";
BA_ "GenSigSendType" SG_ 1416 MO7_Hoeheninfo "Cyclic";
BA_ "GenSigSendType" SG_ 1416 MO7_LL_Solldz "Cyclic";
BA_ "GenSigSendType" SG_ 1416 MO7_Fehler_VBegr "Cyclic";
BA_ "GenSigSendType" SG_ 1416 MO7_Sta_VBegr "Cyclic";
BA_ "GenSigSendType" SG_ 1416 MO7_Fehlereintr "Cyclic";
BA_ "GenSigSendType" SG_ 1416 MO7_StaOeltemp "Cyclic";
BA_ "GenSigSendType" SG_ 1416 MO7_Sta_PTC "Cyclic";
BA_ "GenSigSendType" SG_ 1416 MO7_DFM "Cyclic";
BA_ "GenSigSendType" SG_ 1416 MO7_Gradient_Dz "Cyclic";
BA_ "GenSigSendType" SG_ 1416 MO7_GradientVorz "Cyclic";
BA_ "GenSigSendType" SG_ 1416 MO7_Ladedruckneu "Cyclic";
BA_ "GenSigSendType" SG_ 1416 MO7_GenLdResp "Cyclic";
BA_ "GenSigSendType" SG_ 1416 MO7_PTC_bereit "Cyclic";
BA_ "GenSigSendType" SG_ 1416 MO7_Mot_weckfaehig "Cyclic";
BA_ "GenSigSendType" SG_ 1416 MO7_Zus_Kuehl "Cyclic";
BA_ "GenSigSendType" SG_ 1416 MO7_SleepInd "Cyclic";
BA_ "GenSigSendType" SG_ 1416 MO7_RueckLLDz "Cyclic";
BA_ "GenSigSendType" SG_ 1416 MO7_Lastabwurf "Cyclic";
BA_ "GenSigSendType" SG_ 1416 MO7_Gen_ein "Cyclic";
BA_ "GenSigSendType" SG_ 1416 MO7_Lastabw_Heiz "Cyclic";
BA_ "GenSigSendType" SG_ 1416 MO7_StaGluehk "Cyclic";
BA_ "GenSigSendType" SG_ 1416 MO7_Oeltemp "Cyclic";
BA_ "GenMsgCycleTime" BO_ 644 20;
BA_ "GenMsgSendType" BO_ 644 "Cyclic";
BA_ "GenSigSendType" SG_ 644 MOB_Checksum "Cyclic";
BA_ "GenSigSendType" SG_ 644 MOB_Zaehler "Cyclic";
BA_ "GenSigSendType" SG_ 644 MOB_Standby "Cyclic";
BA_ "GenSigSendType" SG_ 644 MOB_Anhaltewunsch "Cyclic";
BA_ "GenSigSendType" SG_ 644 MOB_Freigabe "Cyclic";
BA_ "GenSigSendType" SG_ 644 MOB_Bremsstgr "Cyclic";
BA_ "GenSigSendType" SG_ 644 TSK_v_Begrenzung_aktiv "Cyclic";
BA_ "GenSigSendType" SG_ 644 MOB_Bremsmom "Cyclic";
BA_ "GenSigSendType" SG_ 644 TSK_ax_Getriebe_01 "Cyclic";
BA_ "GenMsgCycleTime" BO_ 980 20;
BA_ "GenMsgSendType" BO_ 980 "Cyclic";
BA_ "GenSigSendType" SG_ 980 PL1_Checksumme "Cyclic";
BA_ "GenSigSendType" SG_ 980 PL1_Zaehler "Cyclic";
BA_ "GenSigSendType" SG_ 980 PL1_Stat_PLA_ESP "Cyclic";
BA_ "GenSigSendType" SG_ 980 PL1_Bremsmoment "Cyclic";
BA_ "GenSigSendType" SG_ 980 PL1_Stat_PLA_EPS "Cyclic";
BA_ "GenSigSendType" SG_ 980 PL1_LW_Soll "Cyclic";
BA_ "GenSigSendType" SG_ 980 PL1_LW_Soll_Sign "Cyclic";
BA_ "GenMsgCycleTime" BO_ 1488 100;
BA_ "GenMsgSendType" BO_ 1488 "Cyclic";
BA_ "GenSigSendType" SG_ 1488 SY1_Lenker "Cyclic";
BA_ "GenSigSendType" SG_ 1488 SY1_CAN_extern "Cyclic";
BA_ "GenSigSendType" SG_ 1488 SY1_Diag_Ant "Cyclic";
BA_ "GenSigSendType" SG_ 1488 SY1_Sleep_Komf "Cyclic";
BA_ "GenSigSendType" SG_ 1488 SY1_Diag_Komf "Cyclic";
BA_ "GenSigSendType" SG_ 1488 SY1_Sleep_Info "Cyclic";
BA_ "GenSigSendType" SG_ 1488 SY1_Diag_Info "Cyclic";
BA_ "GenSigSendType" SG_ 1488 SY1_CAN_Info "Cyclic";
BA_ "GenSigSendType" SG_ 1488 SY1_Verbauinfo "Cyclic";
BA_ "GenSigSendType" SG_ 1488 SY1_Fzg_Klasse "Cyclic";
BA_ "GenSigSendType" SG_ 1488 SY1_Fzg_Marke "Cyclic";
BA_ "GenSigSendType" SG_ 1488 SY1_Fzg_Derivat "Cyclic";
BA_ "GenSigSendType" SG_ 1488 SY1_Fzg_Gen "Cyclic";
BA_ "GenSigSendType" SG_ 1488 SY1_Fzg_Index "Cyclic";
BA_ "GenSigSendType" SG_ 1488 SY1_Tueren "Cyclic";
BA_ "GenSigSendType" SG_ 1488 SY1_Transportmode "Cyclic";
BA_ "GenSigSendType" SG_ 1488 SY1_Fehlereintr "Cyclic";
BA_ "GenSigSendType" SG_ 1488 SY1_Komf_NV "Cyclic";
BA_ "GenSigSendType" SG_ 1488 SY1_Komf_HV "Cyclic";
BA_ "GenSigSendType" SG_ 1488 SY1_Ant_NV "Cyclic";
BA_ "GenSigSendType" SG_ 1488 SY1_Ant_HV "Cyclic";
BA_ "GenSigSendType" SG_ 1488 SY1_Relais_FAS_Zweig "OnChange";
BA_ "GenSigSendType" SG_ 1488 SY1_ELV_Lock_Supply "OnChange";
BA_ "GenSigSendType" SG_ 1488 SY1_QRS_Messmodus "OnChange";
BA_ "GenSigSendType" SG_ 1488 SY1_NWDF_gueltig "Cyclic";
BA_ "GenSigSendType" SG_ 1488 SY1_NWDF "OnChange";
BA_ "GenSigSendType" SG_ 1488 SY1_Notbrems_Status "OnChange";
BA_ "GenMsgCycleTime" BO_ 1838 200;
BA_ "GenMsgSendType" BO_ 1838 "NoMsgSendType";
BA_ "GenSigSendType" SG_ 1838 NMH_BMS_Start_1 "Cyclic";
BA_ "GenSigSendType" SG_ 1838 NMH_BMS_Start_2 "Cyclic";
BA_ "GenSigSendType" SG_ 1838 NMH_BMS_Normal_Mode_1 "Cyclic";
BA_ "GenSigSendType" SG_ 1838 NMH_BMS_Normal_Mode_2 "Cyclic";
BA_ "GenSigSendType" SG_ 1838 NMH_BMS_Car_WakeUp "Cyclic";
BA_ "GenSigSendType" SG_ 1838 NMH_BMS_Per_WakeUp "Cyclic";
BA_ "GenSigSendType" SG_ 1838 NMH_BMS_Fkt_WakeUp "Cyclic";
BA_ "GenSigSendType" SG_ 1838 NMH_BMS_NM_aktiv_Klemme_15 "Cyclic";
BA_ "GenSigSendType" SG_ 1838 NMH_BMS_NM_aktiv_Diagnose "Cyclic";
BA_ "GenSigSendType" SG_ 1838 NMH_BMS_NM_aktiv_Start "Cyclic";
BA_ "GenSigSendType" SG_ 1838 NMH_BMS_NL_aktiv_4 "Cyclic";
BA_ "GenSigSendType" SG_ 1838 NMH_BMS_NL_aktiv_5 "Cyclic";
BA_ "GenSigSendType" SG_ 1838 NMH_BMS_NL_aktiv_6 "Cyclic";
BA_ "GenSigSendType" SG_ 1838 NMH_BMS_NL_aktiv_7 "Cyclic";
BA_ "GenSigSendType" SG_ 1838 NMH_BMS_NL_aktiv_8 "Cyclic";
BA_ "GenSigSendType" SG_ 1838 NMH_BMS_NL_0 "Cyclic";
BA_ "GenSigSendType" SG_ 1838 NMH_BMS_NL_1 "Cyclic";
BA_ "GenSigSendType" SG_ 1838 NMH_BMS_NL_2 "Cyclic";
BA_ "GenSigSendType" SG_ 1838 NMH_BMS_NL_3 "Cyclic";
BA_ "GenSigSendType" SG_ 1838 NMH_BMS_NL_4 "Cyclic";
BA_ "GenSigSendType" SG_ 1838 NMH_BMS_NL_5 "Cyclic";
BA_ "GenSigSendType" SG_ 1838 NMH_BMS_NL_6 "Cyclic";
BA_ "GenSigSendType" SG_ 1838 NMH_BMS_NL_7 "Cyclic";
BA_ "GenSigSendType" SG_ 1838 NMH_BMS_TimeOut_Fehler "Cyclic";
BA_ "GenSigSendType" SG_ 1838 NMH_BMS_CAN_Diag_deaktiv "Cyclic";
BA_ "GenSigSendType" SG_ 1838 NMH_BMS_KompSchutz "Cyclic";
BA_ "GenSigSendType" SG_ 1838 NMH_BMS_Mute_Mode "Cyclic";
BA_ "GenSigSendType" SG_ 1838 NMH_BMS_Transport_Mode "Cyclic";
BA_ "GenSigSendType" SG_ 1838 NMH_BMS_Abschaltstufe_aktiv "Cyclic";
BA_ "GenSigSendType" SG_ 1838 NMH_BMS_Eindraht_Fehler "Cyclic";
BA_ "GenMsgCycleTime" BO_ 1839 200;
BA_ "GenMsgSendType" BO_ 1839 "NoMsgSendType";
BA_ "GenSigSendType" SG_ 1839 NMH_EM_Start_1 "Cyclic";
BA_ "GenSigSendType" SG_ 1839 NMH_EM_Start_2 "Cyclic";
BA_ "GenSigSendType" SG_ 1839 NMH_EM_Normal_Mode_1 "Cyclic";
BA_ "GenSigSendType" SG_ 1839 NMH_EM_Normal_Mode_2 "Cyclic";
BA_ "GenSigSendType" SG_ 1839 NMH_EM_Car_WakeUp "Cyclic";
BA_ "GenSigSendType" SG_ 1839 NMH_EM_Per_WakeUp "Cyclic";
BA_ "GenSigSendType" SG_ 1839 NMH_EM_Fkt_WakeUp "Cyclic";
BA_ "GenSigSendType" SG_ 1839 NMH_EM_NM_aktiv_Klemme_15 "Cyclic";
BA_ "GenSigSendType" SG_ 1839 NMH_EM_NM_aktiv_Diagnose "Cyclic";
BA_ "GenSigSendType" SG_ 1839 NMH_EM_NM_aktiv_Start "Cyclic";
BA_ "GenSigSendType" SG_ 1839 NMH_EM_NL_aktiv_4 "Cyclic";
BA_ "GenSigSendType" SG_ 1839 NMH_EM_NL_aktiv_5 "Cyclic";
BA_ "GenSigSendType" SG_ 1839 NMH_EM_NL_aktiv_6 "Cyclic";
BA_ "GenSigSendType" SG_ 1839 NMH_EM_NL_aktiv_7 "Cyclic";
BA_ "GenSigSendType" SG_ 1839 NMH_EM_NL_aktiv_8 "Cyclic";
BA_ "GenSigSendType" SG_ 1839 NMH_EM_NL_0 "Cyclic";
BA_ "GenSigSendType" SG_ 1839 NMH_EM_NL_1 "Cyclic";
BA_ "GenSigSendType" SG_ 1839 NMH_EM_NL_2 "Cyclic";
BA_ "GenSigSendType" SG_ 1839 NMH_EM_NL_3 "Cyclic";
BA_ "GenSigSendType" SG_ 1839 NMH_EM_NL_4 "Cyclic";
BA_ "GenSigSendType" SG_ 1839 NMH_EM_NL_5 "Cyclic";
BA_ "GenSigSendType" SG_ 1839 NMH_EM_NL_6 "Cyclic";
BA_ "GenSigSendType" SG_ 1839 NMH_EM_NL_7 "Cyclic";
BA_ "GenSigSendType" SG_ 1839 NMH_EM_TimeOut_Fehler "Cyclic";
BA_ "GenSigSendType" SG_ 1839 NMH_EM_CAN_Diag_deaktiv "Cyclic";
BA_ "GenSigSendType" SG_ 1839 NMH_EM_KompSchutz "Cyclic";
BA_ "GenSigSendType" SG_ 1839 NMH_EM_Mute_Mode "Cyclic";
BA_ "GenSigSendType" SG_ 1839 NMH_EM_Transport_Mode "Cyclic";
BA_ "GenSigSendType" SG_ 1839 NMH_EM_Abschaltstufe_aktiv "Cyclic";
BA_ "GenSigSendType" SG_ 1839 NMH_EM_Eindraht_Fehler "Cyclic";
BA_ "GenMsgCycleTime" BO_ 1849 200;
BA_ "GenMsgSendType" BO_ 1849 "NoMsgSendType";
BA_ "GenSigSendType" SG_ 1849 NMH_EPB_Start_1 "Cyclic";
BA_ "GenSigSendType" SG_ 1849 NMH_EPB_Start_2 "Cyclic";
BA_ "GenSigSendType" SG_ 1849 NMH_EPB_Normal_Mode_1 "Cyclic";
BA_ "GenSigSendType" SG_ 1849 NMH_EPB_Normal_Mode_2 "Cyclic";
BA_ "GenSigSendType" SG_ 1849 NMH_EPB_Car_WakeUp "Cyclic";
BA_ "GenSigSendType" SG_ 1849 NMH_EPB_Per_WakeUp "Cyclic";
BA_ "GenSigSendType" SG_ 1849 NMH_EPB_Fkt_WakeUp "Cyclic";
BA_ "GenSigSendType" SG_ 1849 NMH_EPB_NM_aktiv_Klemme_15 "Cyclic";
BA_ "GenSigSendType" SG_ 1849 NMH_EPB_NM_aktiv_Diagnose "Cyclic";
BA_ "GenSigSendType" SG_ 1849 NMH_EPB_NM_aktiv_Start "Cyclic";
BA_ "GenSigSendType" SG_ 1849 NMH_EPB_NL_aktiv_4 "Cyclic";
BA_ "GenSigSendType" SG_ 1849 NMH_EPB_NL_aktiv_5 "Cyclic";
BA_ "GenSigSendType" SG_ 1849 NMH_EPB_NL_aktiv_6 "Cyclic";
BA_ "GenSigSendType" SG_ 1849 NMH_EPB_NL_aktiv_7 "Cyclic";
BA_ "GenSigSendType" SG_ 1849 NMH_EPB_NL_aktiv_8 "Cyclic";
BA_ "GenSigSendType" SG_ 1849 NMH_EPB_NL_0 "Cyclic";
BA_ "GenSigSendType" SG_ 1849 NMH_EPB_NL_1 "Cyclic";
BA_ "GenSigSendType" SG_ 1849 NMH_EPB_NL_2 "Cyclic";
BA_ "GenSigSendType" SG_ 1849 NMH_EPB_NL_3 "Cyclic";
BA_ "GenSigSendType" SG_ 1849 NMH_EPB_NL_4 "Cyclic";
BA_ "GenSigSendType" SG_ 1849 NMH_EPB_NL_5 "Cyclic";
BA_ "GenSigSendType" SG_ 1849 NMH_EPB_NL_6 "Cyclic";
BA_ "GenSigSendType" SG_ 1849 NMH_EPB_NL_7 "Cyclic";
BA_ "GenSigSendType" SG_ 1849 NMH_EPB_TimeOut_Fehler "Cyclic";
BA_ "GenSigSendType" SG_ 1849 NMH_EPB_CAN_Diag_deaktiv "Cyclic";
BA_ "GenSigSendType" SG_ 1849 NMH_EPB_KompSchutz "Cyclic";
BA_ "GenSigSendType" SG_ 1849 NMH_EPB_Mute_Mode "Cyclic";
BA_ "GenSigSendType" SG_ 1849 NMH_EPB_Transport_Mode "Cyclic";
BA_ "GenSigSendType" SG_ 1849 NMH_EPB_Abschaltstufe_aktiv "Cyclic";
BA_ "GenSigSendType" SG_ 1849 NMH_EPB_Eindraht_Fehler "Cyclic";
BA_ "GenMsgCycleTime" BO_ 1824 200;
BA_ "GenMsgSendType" BO_ 1824 "NoMsgSendType";
BA_ "GenSigSendType" SG_ 1824 NMH_GW_Start_1 "Cyclic";
BA_ "GenSigSendType" SG_ 1824 NMH_GW_Start_2 "Cyclic";
BA_ "GenSigSendType" SG_ 1824 NMH_GW_Normal_Mode_1 "Cyclic";
BA_ "GenSigSendType" SG_ 1824 NMH_GW_Normal_Mode_2 "Cyclic";
BA_ "GenSigSendType" SG_ 1824 NMH_GW_Car_WakeUp "Cyclic";
BA_ "GenSigSendType" SG_ 1824 NMH_GW_Per_WakeUp "Cyclic";
BA_ "GenSigSendType" SG_ 1824 NMH_GW_Fkt_WakeUp "Cyclic";
BA_ "GenSigSendType" SG_ 1824 NMH_GW_NM_aktiv_Klemme_15 "Cyclic";
BA_ "GenSigSendType" SG_ 1824 NMH_GW_NM_aktiv_Diagnose "Cyclic";
BA_ "GenSigSendType" SG_ 1824 NMH_GW_NM_aktiv_Start "Cyclic";
BA_ "GenSigSendType" SG_ 1824 NMH_GW_NL_aktiv_4 "Cyclic";
BA_ "GenSigSendType" SG_ 1824 NMH_GW_NL_aktiv_5 "Cyclic";
BA_ "GenSigSendType" SG_ 1824 NMH_GW_NL_aktiv_6 "Cyclic";
BA_ "GenSigSendType" SG_ 1824 NMH_GW_NL_aktiv_7 "Cyclic";
BA_ "GenSigSendType" SG_ 1824 NMH_GW_NL_aktiv_8 "Cyclic";
BA_ "GenSigSendType" SG_ 1824 NMH_GW_NL_0 "Cyclic";
BA_ "GenSigSendType" SG_ 1824 NMH_GW_NL_1 "Cyclic";
BA_ "GenSigSendType" SG_ 1824 NMH_GW_NL_2 "Cyclic";
BA_ "GenSigSendType" SG_ 1824 NMH_GW_NL_3 "Cyclic";
BA_ "GenSigSendType" SG_ 1824 NMH_GW_NL_4 "Cyclic";
BA_ "GenSigSendType" SG_ 1824 NMH_GW_NL_5 "Cyclic";
BA_ "GenSigSendType" SG_ 1824 NMH_GW_NL_6 "Cyclic";
BA_ "GenSigSendType" SG_ 1824 NMH_GW_NL_7 "Cyclic";
BA_ "GenSigSendType" SG_ 1824 NMH_GW_TimeOut_Fehler "Cyclic";
BA_ "GenSigSendType" SG_ 1824 NMH_GW_CAN_Diag_deaktiv "Cyclic";
BA_ "GenSigSendType" SG_ 1824 NMH_GW_KompSchutz "Cyclic";
BA_ "GenSigSendType" SG_ 1824 NMH_GW_Mute_Mode "Cyclic";
BA_ "GenSigSendType" SG_ 1824 NMH_GW_Transport_Mode "Cyclic";
BA_ "GenSigSendType" SG_ 1824 NMH_GW_Abschaltstufe_aktiv "Cyclic";
BA_ "GenSigSendType" SG_ 1824 NMH_GW_Eindraht_Fehler "Cyclic";
BA_ "GenMsgCycleTime" BO_ 1826 200;
BA_ "GenMsgSendType" BO_ 1826 "NoMsgSendType";
BA_ "GenSigSendType" SG_ 1826 NMH_Getriebe_Start_1 "Cyclic";
BA_ "GenSigSendType" SG_ 1826 NMH_Getriebe_Start_2 "Cyclic";
BA_ "GenSigSendType" SG_ 1826 NMH_Getriebe_Normal_Mode_1 "Cyclic";
BA_ "GenSigSendType" SG_ 1826 NMH_Getriebe_Normal_Mode_2 "Cyclic";
BA_ "GenSigSendType" SG_ 1826 NMH_Getriebe_Car_WakeUp "Cyclic";
BA_ "GenSigSendType" SG_ 1826 NMH_Getriebe_Per_WakeUp "Cyclic";
BA_ "GenSigSendType" SG_ 1826 NMH_Getriebe_Fkt_WakeUp "Cyclic";
BA_ "GenSigSendType" SG_ 1826 NMH_Getriebe_NM_aktiv_Klemme_15 "Cyclic";
BA_ "GenSigSendType" SG_ 1826 NMH_Getriebe_NM_aktiv_Diagnose "Cyclic";
BA_ "GenSigSendType" SG_ 1826 NMH_Getriebe_NM_aktiv_Start "Cyclic";
BA_ "GenSigSendType" SG_ 1826 NMH_Getriebe_NL_aktiv_4 "Cyclic";
BA_ "GenSigSendType" SG_ 1826 NMH_Getriebe_NL_aktiv_5 "Cyclic";
BA_ "GenSigSendType" SG_ 1826 NMH_Getriebe_NL_aktiv_6 "Cyclic";
BA_ "GenSigSendType" SG_ 1826 NMH_Getriebe_NL_aktiv_7 "Cyclic";
BA_ "GenSigSendType" SG_ 1826 NMH_Getriebe_NL_aktiv_8 "Cyclic";
BA_ "GenSigSendType" SG_ 1826 NMH_Getriebe_NL_0 "Cyclic";
BA_ "GenSigSendType" SG_ 1826 NMH_Getriebe_NL_1 "Cyclic";
BA_ "GenSigSendType" SG_ 1826 NMH_Getriebe_NL_2 "Cyclic";
BA_ "GenSigSendType" SG_ 1826 NMH_Getriebe_NL_3 "Cyclic";
BA_ "GenSigSendType" SG_ 1826 NMH_Getriebe_NL_4 "Cyclic";
BA_ "GenSigSendType" SG_ 1826 NMH_Getriebe_NL_5 "Cyclic";
BA_ "GenSigSendType" SG_ 1826 NMH_Getriebe_NL_6 "Cyclic";
BA_ "GenSigSendType" SG_ 1826 NMH_Getriebe_NL_7 "Cyclic";
BA_ "GenSigSendType" SG_ 1826 NMH_Getriebe_TimeOut_Fehler "Cyclic";
BA_ "GenSigSendType" SG_ 1826 NMH_Getriebe_CAN_Diag_deaktiv "Cyclic";
BA_ "GenSigSendType" SG_ 1826 NMH_Getriebe_KompSchutz "Cyclic";
BA_ "GenSigSendType" SG_ 1826 NMH_Getriebe_Mute_Mode "Cyclic";
BA_ "GenSigSendType" SG_ 1826 NMH_Getriebe_Transport_Mode "Cyclic";
BA_ "GenSigSendType" SG_ 1826 NMH_Getriebe_Abschaltstufe_aktiv "Cyclic";
BA_ "GenSigSendType" SG_ 1826 NMH_Getriebe_Eindraht_Fehler "Cyclic";
BA_ "GenMsgCycleTime" BO_ 1834 200;
BA_ "GenMsgSendType" BO_ 1834 "NoMsgSendType";
BA_ "GenSigSendType" SG_ 1834 NMH_GE_02_Start_1 "Cyclic";
BA_ "GenSigSendType" SG_ 1834 NMH_GE_02_Start_2 "Cyclic";
BA_ "GenSigSendType" SG_ 1834 NMH_GE_02_Normal_Mode_1 "Cyclic";
BA_ "GenSigSendType" SG_ 1834 NMH_GE_02_Normal_Mode_2 "Cyclic";
BA_ "GenSigSendType" SG_ 1834 NMH_GE_02_Car_WakeUp "Cyclic";
BA_ "GenSigSendType" SG_ 1834 NMH_GE_02_Per_WakeUp "Cyclic";
BA_ "GenSigSendType" SG_ 1834 NMH_GE_02_Fkt_WakeUp "Cyclic";
BA_ "GenSigSendType" SG_ 1834 NMH_GE_02_NM_aktiv_Klemme_15 "Cyclic";
BA_ "GenSigSendType" SG_ 1834 NMH_GE_02_NM_aktiv_Diagnose "Cyclic";
BA_ "GenSigSendType" SG_ 1834 NMH_GE_02_NM_aktiv_Start "Cyclic";
BA_ "GenSigSendType" SG_ 1834 NMH_GE_02_N_Haltephase "Cyclic";
BA_ "GenSigSendType" SG_ 1834 NMH_GE_02_Positionsanzeige "Cyclic";
BA_ "GenSigSendType" SG_ 1834 NMH_GE_02_kein_NL "Cyclic";
BA_ "GenSigSendType" SG_ 1834 NMH_GE_02_NL_Daten_EEPROM "Cyclic";
BA_ "GenSigSendType" SG_ 1834 NMH_GE_02_NL_Drucksens "Cyclic";
BA_ "GenSigSendType" SG_ 1834 NMH_GE_02_NL_Abtrieb "Cyclic";
BA_ "GenSigSendType" SG_ 1834 NMH_GE_02_NL_Waehlhebel "Cyclic";
BA_ "GenSigSendType" SG_ 1834 NMH_GE_02_NL_Wegfahrsperre "Cyclic";
BA_ "GenSigSendType" SG_ 1834 NMH_GE_02_Signalfehler "Cyclic";
BA_ "GenSigSendType" SG_ 1834 NMH_GE_02_TimeOut_Fehler "Cyclic";
BA_ "GenSigSendType" SG_ 1834 NMH_GE_02_CAN_Diag_deaktiv "Cyclic";
BA_ "GenSigSendType" SG_ 1834 NMH_GE_02_KompSchutz "Cyclic";
BA_ "GenSigSendType" SG_ 1834 NMH_GE_02_Mute_Mode "Cyclic";
BA_ "GenSigSendType" SG_ 1834 NMH_GE_02_Transport_Mode "Cyclic";
BA_ "GenSigSendType" SG_ 1834 NMH_GE_02_Abschaltstufe_aktiv "Cyclic";
BA_ "GenSigSendType" SG_ 1834 NMH_GE_02_Eindraht_Fehler "Cyclic";
BA_ "GenMsgCycleTime" BO_ 1836 200;
BA_ "GenMsgSendType" BO_ 1836 "NoMsgSendType";
BA_ "GenSigSendType" SG_ 1836 NMH_Lademanager_Start_1 "Cyclic";
BA_ "GenSigSendType" SG_ 1836 NMH_Lademanager_Start_2 "Cyclic";
BA_ "GenSigSendType" SG_ 1836 NMH_Lademanager_Normal_Mode_1 "Cyclic";
BA_ "GenSigSendType" SG_ 1836 NMH_Lademanager_Normal_Mode_2 "Cyclic";
BA_ "GenSigSendType" SG_ 1836 NMH_Lademanager_Car_WakeUp "Cyclic";
BA_ "GenSigSendType" SG_ 1836 NMH_Lademanager_Per_WakeUp "Cyclic";
BA_ "GenSigSendType" SG_ 1836 NMH_Lademanager_Fkt_WakeUp "Cyclic";
BA_ "GenSigSendType" SG_ 1836 NMH_Lademanager_NM_aktiv_Klemme_15 "Cyclic";
BA_ "GenSigSendType" SG_ 1836 NMH_Lademanager_NM_aktiv_Diagnose "Cyclic";
BA_ "GenSigSendType" SG_ 1836 NMH_Lademanager_NM_aktiv_Start "Cyclic";
BA_ "GenSigSendType" SG_ 1836 NMH_Lademanager_NL_aktiv_4 "Cyclic";
BA_ "GenSigSendType" SG_ 1836 NMH_Lademanager_NL_aktiv_5 "Cyclic";
BA_ "GenSigSendType" SG_ 1836 NMH_Lademanager_NL_aktiv_6 "Cyclic";
BA_ "GenSigSendType" SG_ 1836 NMH_Lademanager_NL_aktiv_7 "Cyclic";
BA_ "GenSigSendType" SG_ 1836 NMH_Lademanager_NL_aktiv_8 "Cyclic";
BA_ "GenSigSendType" SG_ 1836 NMH_Lademanager_NL_0 "Cyclic";
BA_ "GenSigSendType" SG_ 1836 NMH_Lademanager_NL_1 "Cyclic";
BA_ "GenSigSendType" SG_ 1836 NMH_Lademanager_NL_2 "Cyclic";
BA_ "GenSigSendType" SG_ 1836 NMH_Lademanager_NL_3 "Cyclic";
BA_ "GenSigSendType" SG_ 1836 NMH_Lademanager_NL_4 "Cyclic";
BA_ "GenSigSendType" SG_ 1836 NMH_Lademanager_NL_5 "Cyclic";
BA_ "GenSigSendType" SG_ 1836 NMH_Lademanager_NL_6 "Cyclic";
BA_ "GenSigSendType" SG_ 1836 NMH_Lademanager_NL_7 "Cyclic";
BA_ "GenSigSendType" SG_ 1836 NMH_Lademanager_TimeOut_Fehler "Cyclic";
BA_ "GenSigSendType" SG_ 1836 NMH_Lademanager_CAN_Diag_deaktiv "Cyclic";
BA_ "GenSigSendType" SG_ 1836 NMH_Lademanager_KompSchutz "Cyclic";
BA_ "GenSigSendType" SG_ 1836 NMH_Lademanager_Mute_Mode "Cyclic";
BA_ "GenSigSendType" SG_ 1836 NMH_Lademanager_Transport_Mode "Cyclic";
BA_ "GenSigSendType" SG_ 1836 NMH_Lademanager_Abschaltstufe_aktiv "Cyclic";
BA_ "GenSigSendType" SG_ 1836 NMH_Lademanager_Eindraht_Fehler "Cyclic";
BA_ "GenMsgCycleTime" BO_ 1825 200;
BA_ "GenMsgSendType" BO_ 1825 "NoMsgSendType";
BA_ "GenSigSendType" SG_ 1825 NMH_MO_Start_1 "Cyclic";
BA_ "GenSigSendType" SG_ 1825 NMH_MO_Start_2 "Cyclic";
BA_ "GenSigSendType" SG_ 1825 NMH_MO_Normal_Mode_1 "Cyclic";
BA_ "GenSigSendType" SG_ 1825 NMH_MO_Normal_Mode_2 "Cyclic";
BA_ "GenSigSendType" SG_ 1825 NMH_MO_Car_WakeUp "Cyclic";
BA_ "GenSigSendType" SG_ 1825 NMH_MO_Per_WakeUp "Cyclic";
BA_ "GenSigSendType" SG_ 1825 NMH_MO_Fkt_WakeUp "Cyclic";
BA_ "GenSigSendType" SG_ 1825 NMH_MO_NM_aktiv_Klemme_15 "Cyclic";
BA_ "GenSigSendType" SG_ 1825 NMH_MO_NM_aktiv_Diagnose "Cyclic";
BA_ "GenSigSendType" SG_ 1825 NMH_MO_NM_aktiv_Start "Cyclic";
BA_ "GenSigSendType" SG_ 1825 NMH_MO_NL_aktiv_4 "Cyclic";
BA_ "GenSigSendType" SG_ 1825 NMH_MO_NL_aktiv_5 "Cyclic";
BA_ "GenSigSendType" SG_ 1825 NMH_MO_NL_aktiv_6 "Cyclic";
BA_ "GenSigSendType" SG_ 1825 NMH_MO_NL_aktiv_7 "Cyclic";
BA_ "GenSigSendType" SG_ 1825 NMH_MO_NL_aktiv_8 "Cyclic";
BA_ "GenSigSendType" SG_ 1825 NMH_MO_NL_0 "Cyclic";
BA_ "GenSigSendType" SG_ 1825 NMH_MO_NL_1 "Cyclic";
BA_ "GenSigSendType" SG_ 1825 NMH_MO_NL_2 "Cyclic";
BA_ "GenSigSendType" SG_ 1825 NMH_MO_NL_3 "Cyclic";
BA_ "GenSigSendType" SG_ 1825 NMH_MO_NL_4 "Cyclic";
BA_ "GenSigSendType" SG_ 1825 NMH_MO_NL_5 "Cyclic";
BA_ "GenSigSendType" SG_ 1825 NMH_MO_NL_6 "Cyclic";
BA_ "GenSigSendType" SG_ 1825 NMH_MO_NL_7 "Cyclic";
BA_ "GenSigSendType" SG_ 1825 NMH_MO_TimeOut_Fehler "Cyclic";
BA_ "GenSigSendType" SG_ 1825 NMH_MO_CAN_Diag_deaktiv "Cyclic";
BA_ "GenSigSendType" SG_ 1825 NMH_MO_KompSchutz "Cyclic";
BA_ "GenSigSendType" SG_ 1825 NMH_MO_Mute_Mode "Cyclic";
BA_ "GenSigSendType" SG_ 1825 NMH_MO_Transport_Mode "Cyclic";
BA_ "GenSigSendType" SG_ 1825 NMH_MO_Abschaltstufe_aktiv "Cyclic";
BA_ "GenSigSendType" SG_ 1825 NMH_MO_Eindraht_Fehler "Cyclic";
BA_ "GenMsgSendType" BO_ 1652 "NoMsgSendType";
BA_ "GenSigSendType" SG_ 1652 BAP_Data_ACC "OnChange";
BA_ "GenMsgSendType" BO_ 1654 "NoMsgSendType";
BA_ "GenSigSendType" SG_ 1654 BAP_Data_Anzeige "OnChange";
BA_ "GenMsgSendType" BO_ 1657 "NoMsgSendType";
BA_ "GenSigSendType" SG_ 1657 BAP_Data_HYB "OnChange";
BA_ "GenMsgSendType" BO_ 1651 "NoMsgSendType";
BA_ "GenSigSendType" SG_ 1651 BAP_Data_LDW "OnChange";
BA_ "GenMsgSendType" BO_ 1754 "NoMsgSendType";
BA_ "GenSigSendType" SG_ 1754 BAP_Data_OPS "OnChange";
BA_ "GenMsgSendType" BO_ 1656 "NoMsgSendType";
BA_ "GenSigSendType" SG_ 1656 BAP_Data_OPS_02 "OnChange";
BA_ "GenMsgCycleTime" BO_ 946 100;
BA_ "GenMsgSendType" BO_ 946 "Cyclic";
BA_ "GenSigSendType" SG_ 946 BEM_HYB_DC_uMinLV "Cyclic";
BA_ "GenSigSendType" SG_ 946 BEM_HYB_DC_uSollLV "Cyclic";
BA_ "GenSigSendType" SG_ 946 BEM_Freigabe_HV_Ladung "Cyclic";
BA_ "GenSigSendType" SG_ 946 BEM_Hybrid_Info "Cyclic";
BA_ "GenSigSendType" SG_ 946 BEM_NV_NachladAnf "Cyclic";
BA_ "GenSigSendType" SG_ 946 NVEM_Fahrbereit_Handshake "Cyclic";
BA_ "GenSigSendType" SG_ 946 BEM_Generatordiagnose "Cyclic";
BA_ "GenSigSendType" SG_ 946 BEM_Ladezustand "Cyclic";
BA_ "GenMsgCycleTime" BO_ 945 100;
BA_ "GenMsgSendType" BO_ 945 "Cyclic";
BA_ "GenSigSendType" SG_ 945 DC_HYB_iAktLV "Cyclic";
BA_ "GenSigSendType" SG_ 945 DC_HYB_iAktReserveLV "Cyclic";
BA_ "GenSigSendType" SG_ 945 DC_HYB_uAktLV "Cyclic";
BA_ "GenSigSendType" SG_ 945 DC_HYB_LangsRegelung "Cyclic";
BA_ "GenSigSendType" SG_ 945 DC_HYB_Abregelung_Temperatur "Cyclic";
BA_ "GenSigSendType" SG_ 945 DC_HYB_Fehler_RedLeistung "Cyclic";
BA_ "GenSigSendType" SG_ 945 DC_HYB_Fehler_intern "Cyclic";
BA_ "GenSigSendType" SG_ 945 DC_HYB_Fehler_Spannung "Cyclic";
BA_ "GenSigSendType" SG_ 945 DC_TiefsetzBereit "Cyclic";
BA_ "GenSigSendType" SG_ 945 DC_HYB_Auslastungsgrad "Cyclic";
BA_ "GenMsgSendType" BO_ 18 "IfActive";
BA_ "GenSigSendType" SG_ 18 GSG_WFS_RND "OnChange";
BA_ "GenSigSendType" SG_ 18 GSG_WFS_CRC "OnChange";
BA_ "GenMsgSendType" BO_ 19 "NoMsgSendType";
BA_ "GenSigSendType" SG_ 19 WFS_GSG_SIG_S "OnChange";
BA_ "GenSigSendType" SG_ 19 WFS_GSG_Status_Antwort "OnChange";
BA_ "GenSigSendType" SG_ 19 WFS_GSG_Status_Lesespule "OnChange";
BA_ "GenSigSendType" SG_ 19 WFS_GSG_Status_Schluessel "OnChange";
BA_ "GenSigSendType" SG_ 19 WFS_GSG_Status_Anfrage "OnChange";
BA_ "GenSigSendType" SG_ 19 WFS_GSG_Status_P_Klasse "OnChange";
BA_ "GenSigSendType" SG_ 19 WFS_GSG_Status_WFS_5 "OnChange";
BA_ "GenMsgSendType" BO_ 17 "IfActive";
BA_ "GenSigSendType" SG_ 17 WFS_MSG1_SIG_S "OnChange";
BA_ "GenSigSendType" SG_ 17 WFS_MSG1_Status_Antwort "OnChange";
BA_ "GenSigSendType" SG_ 17 WFS_MSG1_Status_Lesespule "OnChange";
BA_ "GenSigSendType" SG_ 17 WFS_MSG1_Status_Schluessel "OnChange";
BA_ "GenSigSendType" SG_ 17 WFS_MSG1_Status_Anfrage "OnChange";
BA_ "GenSigSendType" SG_ 17 WFS_MSG1_Status_P_Klasse "OnChange";
BA_ "GenSigSendType" SG_ 17 WFS_MSG1_Status_WFS_5 "OnChange";
BA_ "GenMsgSendType" BO_ 21 "IfActive";
BA_ "GenSigSendType" SG_ 21 WFS_MSG2_SIG_S "OnChange";
BA_ "GenSigSendType" SG_ 21 WFS_MSG2_Status_Antwort "OnChange";
BA_ "GenSigSendType" SG_ 21 WFS_MSG2_Status_Lesespule "OnChange";
BA_ "GenSigSendType" SG_ 21 WFS_MSG2_Status_Schluessel "OnChange";
BA_ "GenSigSendType" SG_ 21 WFS_MSG2_Status_Anfrage "OnChange";
BA_ "GenSigSendType" SG_ 21 WFS_MSG2_Status_P_Klasse "OnChange";
BA_ "GenSigSendType" SG_ 21 WFS_MSG2_Status_WFS_5 "OnChange";
BA_ "GenMsgSendType" BO_ 23 "IfActive";
BA_ "GenSigSendType" SG_ 23 WFS_MSG3_SIG_S "OnChange";
BA_ "GenSigSendType" SG_ 23 WFS_MSG3_Status_Antwort "OnChange";
BA_ "GenSigSendType" SG_ 23 WFS_MSG3_Status_Lesespule "OnChange";
BA_ "GenSigSendType" SG_ 23 WFS_MSG3_Status_Schluessel "OnChange";
BA_ "GenSigSendType" SG_ 23 WFS_MSG3_Status_Anfrage "OnChange";
BA_ "GenSigSendType" SG_ 23 WFS_MSG3_Status_P_Klasse "OnChange";
BA_ "GenSigSendType" SG_ 23 WFS_MSG3_Status_WFS_5 "OnChange";
BA_ "GenMsgSendType" BO_ 25 "IfActive";
BA_ "GenSigSendType" SG_ 25 WFS_MSG4_SIG_S "OnChange";
BA_ "GenSigSendType" SG_ 25 WFS_MSG4_Status_Antwort "OnChange";
BA_ "GenSigSendType" SG_ 25 WFS_MSG4_Status_Lesespule "OnChange";
BA_ "GenSigSendType" SG_ 25 WFS_MSG4_Status_Schluessel "OnChange";
BA_ "GenSigSendType" SG_ 25 WFS_MSG4_Status_Anfrage "OnChange";
BA_ "GenSigSendType" SG_ 25 WFS_MSG4_Status_P_Klasse "OnChange";
BA_ "GenSigSendType" SG_ 25 WFS_MSG4_Status_WFS_5 "OnChange";
BA_ "GenMsgSendType" BO_ 1879 "NoMsgSendType";
BA_ "GenSigSendType" SG_ 1879 ISO_ACC_Req_Data "OnChange";
BA_ "GenMsgSendType" BO_ 1985 "NoMsgSendType";
BA_ "GenSigSendType" SG_ 1985 ISO_ACC_Resp_Data "OnChange";
BA_ "GenMsgSendType" BO_ 1892 "NoMsgSendType";
BA_ "GenSigSendType" SG_ 1892 ISO_AGA_Req_Data "OnChange";
BA_ "GenMsgSendType" BO_ 1813 "NoMsgSendType";
BA_ "GenSigSendType" SG_ 1813 ISO_Airbag_01_Req_Data "OnChange";
BA_ "GenMsgSendType" BO_ 1919 "NoMsgSendType";
BA_ "GenSigSendType" SG_ 1919 ISO_Airbag_01_Resp_Data "OnChange";
BA_ "GenMsgSendType" BO_ 1807 "NoMsgSendType";
BA_ "GenSigSendType" SG_ 1807 ISO_Allrad_Req_Data "OnChange";
BA_ "GenMsgSendType" BO_ 1913 "NoMsgSendType";
BA_ "GenSigSendType" SG_ 1913 ISO_Allrad_Resp_Data "OnChange";
BA_ "GenMsgSendType" BO_ 1874 "NoMsgSendType";
BA_ "GenSigSendType" SG_ 1874 ISO_EPB_Req_Data "OnChange";
BA_ "GenMsgSendType" BO_ 1980 "NoMsgSendType";
BA_ "GenSigSendType" SG_ 1980 ISO_EPB_Resp_Data "OnChange";
BA_ "GenMsgSendType" BO_ 1802 "NoMsgSendType";
BA_ "GenSigSendType" SG_ 1802 ISO_EPH_Req_Data "OnChange";
BA_ "GenMsgSendType" BO_ 1908 "NoMsgSendType";
BA_ "GenSigSendType" SG_ 1908 ISO_EPH_Resp_Data "OnChange";
BA_ "GenMsgSendType" BO_ 1840 "NoMsgSendType";
BA_ "GenSigSendType" SG_ 1840 ISO_FLA_Req_Data "OnChange";
BA_ "GenMsgSendType" BO_ 1946 "NoMsgSendType";
BA_ "GenSigSendType" SG_ 1946 ISO_FLA_Resp_Data "OnChange";
BA_ "GenMsgSendType" BO_ 1795 "NoMsgSendType";
BA_ "GenSigSendType" SG_ 1795 ISO_Funktionaler_Req_Abgas "OnChange";
BA_ "GenMsgSendType" BO_ 2015 "NoMsgSendType";
BA_ "GenSigSendType" SG_ 2015 ISO_OBD_Funktionaler_Req_Data "OnChange";
BA_ "GenMsgSendType" BO_ 2017 "NoMsgSendType";
BA_ "GenSigSendType" SG_ 2017 ISO_Getriebe_01_Req_Data "OnChange";
BA_ "GenMsgSendType" BO_ 2025 "NoMsgSendType";
BA_ "GenSigSendType" SG_ 2025 ISO_Getriebe_01_Resp_Data "OnChange";
BA_ "GenMsgSendType" BO_ 1891 "NoMsgSendType";
BA_ "GenSigSendType" SG_ 1891 ISO_Gurtmikro_Req_Data "OnChange";
BA_ "GenMsgSendType" BO_ 1997 "NoMsgSendType";
BA_ "GenSigSendType" SG_ 1997 ISO_Gurtmikro_Resp_Data "OnChange";
BA_ "GenMsgSendType" BO_ 1860 "NoMsgSendType";
BA_ "GenSigSendType" SG_ 1860 ISO_Ladegeraet_Req_Data "OnChange";
BA_ "GenMsgSendType" BO_ 1810 "NoMsgSendType";
BA_ "GenSigSendType" SG_ 1810 ISO_Lenkhilfe_Req_Data "OnChange";
BA_ "GenMsgSendType" BO_ 1916 "NoMsgSendType";
BA_ "GenSigSendType" SG_ 1916 ISO_Lenkhilfe_Resp_Data "OnChange";
BA_ "GenMsgSendType" BO_ 1832 "NoMsgSendType";
BA_ "GenSigSendType" SG_ 1832 ISO_LIN_Flash_Req_Data "OnChange";
BA_ "GenMsgSendType" BO_ 1938 "NoMsgSendType";
BA_ "GenSigSendType" SG_ 1938 ISO_LIN_Flash_Resp_Data "OnChange";
BA_ "GenMsgSendType" BO_ 1876 "NoMsgSendType";
BA_ "GenSigSendType" SG_ 1876 ISO_LWRAFS_Req_Data "OnChange";
BA_ "GenMsgSendType" BO_ 1982 "NoMsgSendType";
BA_ "GenSigSendType" SG_ 1982 ISO_LWRAFS_Resp_Data "OnChange";
BA_ "GenMsgSendType" BO_ 2016 "NoMsgSendType";
BA_ "GenSigSendType" SG_ 2016 ISO_MO_01_Req_Data "OnChange";
BA_ "GenMsgSendType" BO_ 2024 "NoMsgSendType";
BA_ "GenSigSendType" SG_ 2024 ISO_MO_01_Resp_Data "OnChange";
BA_ "GenMsgSendType" BO_ 2018 "NoMsgSendType";
BA_ "GenSigSendType" SG_ 2018 ISO_OBD_01_Req_Data "OnChange";
BA_ "GenMsgSendType" BO_ 2026 "NoMsgSendType";
BA_ "GenSigSendType" SG_ 2026 ISO_OBD_01_Resp_Data "OnChange";
BA_ "GenMsgSendType" BO_ 2019 "NoMsgSendType";
BA_ "GenSigSendType" SG_ 2019 ISO_OBD_02_Req_Data "OnChange";
BA_ "GenMsgSendType" BO_ 2027 "NoMsgSendType";
BA_ "GenSigSendType" SG_ 2027 ISO_OBD_02_Resp_Data "OnChange";
BA_ "GenMsgSendType" BO_ 2020 "NoMsgSendType";
BA_ "GenSigSendType" SG_ 2020 ISO_OBD_03_Req_Data "OnChange";
BA_ "GenMsgSendType" BO_ 2028 "NoMsgSendType";
BA_ "GenSigSendType" SG_ 2028 ISO_OBD_03_Resp_Data "OnChange";
BA_ "GenMsgSendType" BO_ 2021 "NoMsgSendType";
BA_ "GenSigSendType" SG_ 2021 ISO_OBD_04_Req_Data "OnChange";
BA_ "GenMsgSendType" BO_ 2029 "NoMsgSendType";
BA_ "GenSigSendType" SG_ 2029 ISO_OBD_04_Resp_Data "OnChange";
BA_ "GenMsgSendType" BO_ 2022 "NoMsgSendType";
BA_ "GenSigSendType" SG_ 2022 ISO_OBD_05_Req_Data "OnChange";
BA_ "GenMsgSendType" BO_ 2030 "NoMsgSendType";
BA_ "GenSigSendType" SG_ 2030 ISO_OBD_05_Resp_Data "OnChange";
BA_ "GenMsgSendType" BO_ 2023 "NoMsgSendType";
BA_ "GenSigSendType" SG_ 2023 ISO_OBD_06_Req_Data "OnChange";
BA_ "GenMsgSendType" BO_ 2031 "NoMsgSendType";
BA_ "GenSigSendType" SG_ 2031 ISO_OBD_06_Resp_Data "OnChange";
BA_ "GenMsgSendType" BO_ 1822 "NoMsgSendType";
BA_ "GenSigSendType" SG_ 1822 ISO_Quersperre_Req_Data "OnChange";
BA_ "GenMsgSendType" BO_ 1928 "NoMsgSendType";
BA_ "GenSigSendType" SG_ 1928 ISO_Quersperre_Resp_Data "OnChange";
BA_ "GenMsgCycleTime" BO_ 1386 40;
BA_ "GenMsgSendType" BO_ 1386 "Cyclic";
BA_ "GenSigSendType" SG_ 1386 ACA_Checksum "Cyclic";
BA_ "GenSigSendType" SG_ 1386 ACA_StaACC "Cyclic";
BA_ "GenSigSendType" SG_ 1386 ACA_ID_StaACC "Cyclic";
BA_ "GenSigSendType" SG_ 1386 ACA_Fahrerhinw "Cyclic";
BA_ "GenSigSendType" SG_ 1386 ACA_AnzDisplay "Cyclic";
BA_ "GenSigSendType" SG_ 1386 ACA_Zeitluecke "Cyclic";
BA_ "GenSigSendType" SG_ 1386 ACA_V_Wunsch "Cyclic";
BA_ "GenSigSendType" SG_ 1386 ACA_kmh_mph "Cyclic";
BA_ "GenSigSendType" SG_ 1386 ACA_Akustik1 "Cyclic";
BA_ "GenSigSendType" SG_ 1386 ACA_Akustik2 "Cyclic";
BA_ "GenSigSendType" SG_ 1386 ACA_PrioDisp "Cyclic";
BA_ "GenSigSendType" SG_ 1386 ACA_gemZeitl "Cyclic";
BA_ "GenSigSendType" SG_ 1386 ACA_ACC_Verz "Cyclic";
BA_ "GenSigSendType" SG_ 1386 ACA_StaGRA "Cyclic";
BA_ "GenSigSendType" SG_ 1386 ACA_ID_StaGRA "Cyclic";
BA_ "GenSigSendType" SG_ 1386 ACA_Codierung "Cyclic";
BA_ "GenSigSendType" SG_ 1386 ACA_Tachokranz "Cyclic";
BA_ "GenSigSendType" SG_ 1386 ACA_Aend_Zeitluecke "Cyclic";
BA_ "GenSigSendType" SG_ 1386 ACA_Zaehler "Cyclic";
BA_ "GenMsgCycleTime" BO_ 872 20;
BA_ "GenMsgSendType" BO_ 872 "Cyclic";
BA_ "GenSigSendType" SG_ 872 ACS_Checksum "Cyclic";
BA_ "GenSigSendType" SG_ 872 ACS_Zaehler "Cyclic";
BA_ "GenSigSendType" SG_ 872 ACS_Sta_ADR "Cyclic";
BA_ "GenSigSendType" SG_ 872 ACS_ADR_Schub "Cyclic";
BA_ "GenSigSendType" SG_ 872 ACS_Schubabsch "Cyclic";
BA_ "GenSigSendType" SG_ 872 ACS_StSt_Info "Cyclic";
BA_ "GenSigSendType" SG_ 872 ACS_MomEingriff "Cyclic";
BA_ "GenSigSendType" SG_ 872 ACS_Typ_ACC "Cyclic";
BA_ "GenSigSendType" SG_ 872 ACS_FreigSollB "Cyclic";
BA_ "GenSigSendType" SG_ 872 ACS_Sollbeschl "Cyclic";
BA_ "GenSigSendType" SG_ 872 ACS_Anhaltewunsch "Cyclic";
BA_ "GenSigSendType" SG_ 872 ACS_Fehler "Cyclic";
BA_ "GenSigSendType" SG_ 872 ACS_zul_Regelabw "Cyclic";
BA_ "GenSigSendType" SG_ 872 ACS_max_AendGrad "Cyclic";
BA_ "GenMsgCycleTime" BO_ 1688 100;
BA_ "GenMsgSendType" BO_ 1688 "Cyclic";
BA_ "GenSigSendType" SG_ 1688 AFZ_ParaSW_L "Cyclic";
BA_ "GenSigSendType" SG_ 1688 AFZ_ParaSW_R "Cyclic";
BA_ "GenSigSendType" SG_ 1688 AFZ_Modus "Cyclic";
BA_ "GenSigSendType" SG_ 1688 AFZ_Init "Cyclic";
BA_ "GenSigSendType" SG_ 1688 AFZ_SafePos "Cyclic";
BA_ "GenSigSendType" SG_ 1688 AFZ_IstPosMot_L "Cyclic";
BA_ "GenSigSendType" SG_ 1688 AFZ_IstPosMot_R "Cyclic";
BA_ "GenSigSendType" SG_ 1688 AFZ_Soll_EVG "Cyclic";
BA_ "GenSigSendType" SG_ 1688 AFZ_IstDimAbLi "Cyclic";
BA_ "GenSigSendType" SG_ 1688 AFZ_IstDimAbRe "Cyclic";
BA_ "GenSigSendType" SG_ 1688 AFZ_StaLamp_L "Cyclic";
BA_ "GenSigSendType" SG_ 1688 AFZ_StaLamp_R "Cyclic";
BA_ "GenMsgCycleTime" BO_ 1360 200;
BA_ "GenMsgSendType" BO_ 1360 "Cyclic";
BA_ "GenSigSendType" SG_ 1360 AB2_Checksum "Cyclic";
BA_ "GenSigSendType" SG_ 1360 AB2_Beleg_HF "Cyclic";
BA_ "GenSigSendType" SG_ 1360 AB2_Beleg_HBF "Cyclic";
BA_ "GenSigSendType" SG_ 1360 AB2_Beleg_HM "Cyclic";
BA_ "GenSigSendType" SG_ 1360 AB2_Beleg_BF "Cyclic";
BA_ "GenSigSendType" SG_ 1360 AB2_OOP_Fa "Cyclic";
BA_ "GenSigSendType" SG_ 1360 AB2_OOP_BF "Cyclic";
BA_ "GenSigSendType" SG_ 1360 AB2_Sta_BF "Cyclic";
BA_ "GenSigSendType" SG_ 1360 AB2_Gurt_2FaS "Cyclic";
BA_ "GenSigSendType" SG_ 1360 AB2_Gurt_2BfS "Cyclic";
BA_ "GenSigSendType" SG_ 1360 AB2_Gurt_2Mi "Cyclic";
BA_ "GenSigSendType" SG_ 1360 AB2_Gurt_3FaS "Cyclic";
BA_ "GenSigSendType" SG_ 1360 AB2_Gurt_3BfS "Cyclic";
BA_ "GenSigSendType" SG_ 1360 AB2_Gurt_3Mi "Cyclic";
BA_ "GenSigSendType" SG_ 1360 AB_Deaktivierung_HV "OnChangeWithRepetition";
BA_ "GenSigSendType" SG_ 1360 AB_Abschaltanf_SIH_BF "OnChange";
BA_ "GenSigSendType" SG_ 1360 AB2_Zaehler "Cyclic";
BA_ "GenMsgCycleTime" BO_ 1404 1000;
BA_ "GenMsgSendType" BO_ 1404 "Cyclic";
BA_ "GenSigSendType" SG_ 1404 BY1_KD_Fehler "Cyclic";
BA_ "GenSigSendType" SG_ 1404 BMS_Gesamtst_Spgfreiheit "OnChange";
BA_ "GenSigSendType" SG_ 1404 BY1_Zaehler "Cyclic";
BA_ "GenSigSendType" SG_ 1404 BMS_Temperatur "Cyclic";
BA_ "GenSigSendType" SG_ 1404 BMS_Temperierung_Anf "Cyclic";
BA_ "GenSigSendType" SG_ 1404 BMS_As_Entladezaehler_Ueberlauf "Cyclic";
BA_ "GenSigSendType" SG_ 1404 BMS_As_Entladezaehler "Cyclic";
BA_ "GenSigSendType" SG_ 1404 BMS_IstVorlaufTemperatur "Cyclic";
BA_ "GenSigSendType" SG_ 1404 BY1_Checksumme "Cyclic";
BA_ "GenMsgCycleTime" BO_ 1524 1000;
BA_ "GenMsgSendType" BO_ 1524 "Cyclic";
BA_ "GenSigSendType" SG_ 1524 BCN_Checksumme "Cyclic";
BA_ "GenSigSendType" SG_ 1524 BCN_BremsenVar "Cyclic";
BA_ "GenSigSendType" SG_ 1524 BCN_AntriebsVar "Cyclic";
BA_ "GenMsgCycleTime" BO_ 1528 50;
BA_ "GenMsgSendType" BO_ 1528 "NoMsgSendType";
BA_ "GenSigSendType" SG_ 1528 Module_ID_5 "IfActiveWithRepetition";
BA_ "GenSigSendType" SG_ 1528 Update_Indikator_5 "IfActiveWithRepetition";
BA_ "GenSigSendType" SG_ 1528 Funktions_ID_5 "IfActiveWithRepetition";
BA_ "GenSigSendType" SG_ 1528 OpCode_5 "IfActiveWithRepetition";
BA_ "GenSigSendType" SG_ 1528 Controller_ID_5 "IfActiveWithRepetition";
BA_ "GenSigSendType" SG_ 1528 Data_Byte_1_5 "IfActiveWithRepetition";
BA_ "GenSigSendType" SG_ 1528 Data_Byte_2_5 "IfActiveWithRepetition";
BA_ "GenSigSendType" SG_ 1528 Data_Byte_3_5 "IfActiveWithRepetition";
BA_ "GenSigSendType" SG_ 1528 Data_Byte_4_5 "IfActiveWithRepetition";
BA_ "GenSigSendType" SG_ 1528 Data_Byte_5_5 "IfActiveWithRepetition";
BA_ "GenMsgCycleTime" BO_ 1530 50;
BA_ "GenMsgSendType" BO_ 1530 "NoMsgSendType";
BA_ "GenSigSendType" SG_ 1530 Module_ID_19 "IfActiveWithRepetition";
BA_ "GenSigSendType" SG_ 1530 Update_Indikator_19 "IfActiveWithRepetition";
BA_ "GenSigSendType" SG_ 1530 Funktions_ID_19 "IfActiveWithRepetition";
BA_ "GenSigSendType" SG_ 1530 OpCode_19 "IfActiveWithRepetition";
BA_ "GenSigSendType" SG_ 1530 Controller_ID_19 "IfActiveWithRepetition";
BA_ "GenSigSendType" SG_ 1530 Data_Byte_1_19 "IfActiveWithRepetition";
BA_ "GenSigSendType" SG_ 1530 Data_Byte_2_19 "IfActiveWithRepetition";
BA_ "GenSigSendType" SG_ 1530 Data_Byte_3_19 "IfActiveWithRepetition";
BA_ "GenSigSendType" SG_ 1530 Data_Byte_4_19 "IfActiveWithRepetition";
BA_ "GenSigSendType" SG_ 1530 Data_Byte_5_19 "IfActiveWithRepetition";
BA_ "GenMsgCycleTime" BO_ 1504 100;
BA_ "GenMsgSendType" BO_ 1504 "Cyclic";
BA_ "GenSigSendType" SG_ 1504 CL1_LL_Dz "OnChange";
BA_ "GenSigSendType" SG_ 1504 CL1_Fa_Zuheiz "OnChange";
BA_ "GenSigSendType" SG_ 1504 CL1_Hecksch "OnChange";
BA_ "GenSigSendType" SG_ 1504 CL1_Frontsch "OnChange";
BA_ "GenSigSendType" SG_ 1504 CL1_Kompressor "OnChange";
BA_ "GenSigSendType" SG_ 1504 CL1_Heizleist "OnChange";
BA_ "GenSigSendType" SG_ 1504 CL1_Sta_Moment "OnChange";
BA_ "GenSigSendType" SG_ 1504 CL1_Sta_Druck "OnChange";
BA_ "GenSigSendType" SG_ 1504 CL1_Aussentemp "Cyclic";
BA_ "GenSigSendType" SG_ 1504 CL1_Druck "Cyclic";
BA_ "GenSigSendType" SG_ 1504 CL1_Kompr_Last "Cyclic";
BA_ "GenSigSendType" SG_ 1504 CL1_Gebl_last "Cyclic";
BA_ "GenSigSendType" SG_ 1504 CL1_Luefter "Cyclic";
BA_ "GenSigSendType" SG_ 1504 CL1_Einheit_Temp "Cyclic";
BA_ "GenSigSendType" SG_ 1504 CL1_AC_Schalter "Cyclic";
BA_ "GenSigSendType" SG_ 1504 CL1_WAPU_Zuschaltung "Cyclic";
BA_ "GenSigSendType" SG_ 1504 CL1_Restwaerme "Cyclic";
BA_ "GenSigSendType" SG_ 1504 CL1_PTC_Hzg "Cyclic";
BA_ "GenSigSendType" SG_ 1504 CL1_Fehlereintr "Cyclic";
BA_ "GenSigSendType" SG_ 1504 KL_Thermomanagement "Cyclic";
BA_ "GenSigSendType" SG_ 1504 KL_VK_Betriebsdauer "Cyclic";
BA_ "GenMsgCycleTime" BO_ 1432 100;
BA_ "GenMsgSendType" BO_ 1432 "Cyclic";
BA_ "GenSigSendType" SG_ 1432 DA1_Daempferreg "Cyclic";
BA_ "GenSigSendType" SG_ 1432 DA1_Warnlampe "Cyclic";
BA_ "GenSigSendType" SG_ 1432 DA1_Taster "Cyclic";
BA_ "GenSigSendType" SG_ 1432 DA1_Systemstatus "Cyclic";
BA_ "GenSigSendType" SG_ 1432 DA1_Fehlereintr "Cyclic";
BA_ "GenSigSendType" SG_ 1432 DA1_Textbits "Cyclic";
BA_ "GenSigSendType" SG_ 1432 DA1_Zaehler "Cyclic";
BA_ "GenSigSendType" SG_ 1432 DA1_ESP_Zwang "Cyclic";
BA_ "GenSigSendType" SG_ 1432 DA1_LampPruef "Cyclic";
BA_ "GenSigSendType" SG_ 1432 DA1_Charisma "Cyclic";
BA_ "GenSigSendType" SG_ 1432 DA1_Checksumme "Cyclic";
BA_ "GenMsgCycleTime" BO_ 1550 1000;
BA_ "GenMsgSendType" BO_ 1550 "Cyclic";
BA_ "GenSigSendType" SG_ 1550 EH1_Einh_Strck "OnChange";
BA_ "GenSigSendType" SG_ 1550 EH1_Einh_Temp "OnChange";
BA_ "GenSigSendType" SG_ 1550 EH1_Einh_Vol "OnChange";
BA_ "GenSigSendType" SG_ 1550 EH1_Einh_Verbr "OnChange";
BA_ "GenSigSendType" SG_ 1550 EH1_Einh_Druck "OnChange";
BA_ "GenSigSendType" SG_ 1550 EH1_Datum_Anzeige "OnChange";
BA_ "GenSigSendType" SG_ 1550 EH1_Uhr_Anzeige "OnChange";
BA_ "GenSigSendType" SG_ 1550 EH1_Profil "OnChange";
BA_ "GenSigSendType" SG_ 1550 EH1_Wochentag "OnChange";
BA_ "GenSigSendType" SG_ 1550 EH1_Verstellung_Strck "OnChange";
BA_ "GenMsgCycleTime" BO_ 1406 1000;
BA_ "GenMsgSendType" BO_ 1406 "Cyclic";
BA_ "GenSigSendType" SG_ 1406 EY1_KD_Fehler "Cyclic";
BA_ "GenMsgCycleTime" BO_ 1626 1000;
BA_ "GenMsgSendType" BO_ 1626 "Cyclic";
BA_ "GenSigSendType" SG_ 1626 FL1_KD_Fehler "OnChange";
BA_ "GenSigSendType" SG_ 1626 FL1_FLA_aktiv "OnChange";
BA_ "GenSigSendType" SG_ 1626 FL1_ISP_defekt "OnChange";
BA_ "GenSigSendType" SG_ 1626 FL1_Sensor_blockiert "OnChange";
BA_ "GenSigSendType" SG_ 1626 FL1_Abblendursache "OnChange";
BA_ "GenSigSendType" SG_ 1626 FL1_Fernlicht_PWM "OnChange";
BA_ "GenSigSendType" SG_ 1626 FL1_ISP_Lichtwert_vo "OnChange";
BA_ "GenSigSendType" SG_ 1626 FL1_ISP_Lichtwert_hi "OnChange";
BA_ "GenSigSendType" SG_ 1626 FL1_ISP_Himmelsrichtung "OnChange";
BA_ "GenSigSendType" SG_ 1626 FL1_ISP_Taste "OnChange";
BA_ "GenSigSendType" SG_ 1626 FL1_ISP_EC_aktiv "OnChange";
BA_ "GenSigSendType" SG_ 1626 FL1_ISP_Kompass_aktiv "OnChange";
BA_ "GenSigSendType" SG_ 1626 FL1_Dimmwert_ASP "OnChange";
BA_ "GenSigSendType" SG_ 1626 FL1_FLA_Aufblenden "OnChange";
VAL_ 1416 MO7_Hoeheninfo 255 "Fehler" ;
VAL_ 1416 MO7_LL_Solldz 1 "LLDZ_hat_Wert_1_Stufe_erreicht" 0 "keine_Anf_einer_erhoehten_LL_DZ" ;
VAL_ 1416 MO7_Fehler_VBegr 1 "V_Begrenzung_moeglich" 0 "V_Begrenzung_nicht_moeglich" ;
VAL_ 1416 MO7_Sta_VBegr 1 "aktiv" 0 "inaktiv" ;
VAL_ 1416 MO7_Fehlereintr 1 "Fehlerspeichereintrag" 0 "kein_Fehlerspeichereintrag" ;
VAL_ 1416 MO7_StaOeltemp 1 "n_iO" 0 "iO" ;
VAL_ 1416 MO7_Sta_PTC 7 "PTC_aus" 3 "PTC_33_Prozent_aktiv" 1 "PTC_66_Prozent_aktiv" 0 "PTC_100_Prozent_aktiv" ;
VAL_ 1416 MO7_DFM 255 "Fehler" ;
VAL_ 1416 MO7_Gradient_Dz 127 "ist_groessergleich_127_min" ;
VAL_ 1416 MO7_GradientVorz 1 "negatives_Vorzeichen" 0 "positives_Vorzeichen" ;
VAL_ 1416 MO7_Ladedruckneu 255 "Fehler" ;
VAL_ 1416 MO7_PTC_bereit 0 "kein_3stuf_PTC_verbaut" ;
VAL_ 1416 MO7_Mot_weckfaehig 1 "Wecken_ACAN_gef" 0 "kein_Wecken_ACAN" ;
VAL_ 1416 MO7_Zus_Kuehl 1 "Heckscheibenheizung_ein" 0 "Heckscheibenheizung_aus" ;
VAL_ 1416 MO7_SleepInd 1 "Sleep_bereit" 0 "CAN_wird_benoetigt" ;
VAL_ 1416 MO7_RueckLLDz 1 "LLDZ_hat_Wert_2_Stufe_erreicht" 0 "keine_Anf_einer_erhoehten_LL_DZ" ;
VAL_ 1416 MO7_Lastabwurf 3 "Stufe_3" 2 "Stufe_2" 1 "Stufe_1" 0 "Stufe_0" ;
VAL_ 1416 MO7_Gen_ein 1 "Generator_ein" 0 "Generator_aus" ;
VAL_ 1416 MO7_Lastabw_Heiz 1 "Hochleistungsheizsys_aktivierbar" 0 "Hochleistungsheizsys_deaktiviert" ;
VAL_ 1416 MO7_StaGluehk 15 "Fehler" ;
VAL_ 1416 MO7_Oeltemp 255 "Fehler" 1 "Init" 0 "nicht_verbaut" ;
VAL_ 644 MOB_Standby 1 "Bremse_in_Vorhaltposition_bringe" 0 "Bremse_in_0_Stellung" ;
VAL_ 644 MOB_Anhaltewunsch 1 "Fzg_haelt_an" 0 "kein_Haltewunsch" ;
VAL_ 644 MOB_Freigabe 1 "Bremsanf_freigegeben" 0 "Bremsanf_nicht_freigegeb" ;
VAL_ 644 TSK_v_Begrenzung_aktiv 1 "aktiv" 0 "inaktiv" ;
VAL_ 644 MOB_Bremsmom 8191 "Fehler" ;
VAL_ 644 TSK_ax_Getriebe_01 255 "Neutralwert" ;
VAL_ 980 PL1_Stat_PLA_ESP 10 "PLA_ESP_Abbruch" 9 "PLA_ESP_Neustart" 8 "PLA_ESP_funktionsbereit" 6 "PLA_ESP_Bremse_aktiv" 4 "PLA_ESP_aktivierbar" ;
VAL_ 980 PL1_Bremsmoment 8191 "Fehler" ;
VAL_ 980 PL1_LW_Soll_Sign 1 "negatives_Vorzeichen" 0 "positives_Vorzeichen" ;
VAL_ 1488 SY1_Lenker 1 "Rechtslenker" 0 "Linkslenker" ;
VAL_ 1488 SY1_CAN_extern 1 "CANextern_zugeschaltet" 0 "CANextern_getrennt" ;
VAL_ 1488 SY1_Diag_Ant 1 "CAN_Antrieb_in_Diagnose" 0 "zZt_keine_Antrieb_Diagnose" ;
VAL_ 1488 SY1_Sleep_Komf 1 "Busruhe" 0 "keine_Busruhe" ;
VAL_ 1488 SY1_Diag_Komf 1 "Diagnoseanf_im_CAN_Komf_erkannt" 0 "zZt_keine_Komfort_Diagnose" ;
VAL_ 1488 SY1_Sleep_Info 1 "Busruhe" 0 "keine_Busruhe" ;
VAL_ 1488 SY1_Diag_Info 1 "Diagnoseanf_im_CAN_Infot_erkannt" 0 "zZt_keine_Infotainement_Diagnose" ;
VAL_ 1488 SY1_CAN_Info 1 "verbaut" 0 "nicht_verbaut" ;
VAL_ 1488 SY1_Verbauinfo 1 "gueltig" 0 "ungueltig" ;
VAL_ 1488 SY1_Fzg_Klasse 9 "L_Klasse" 8 "LT_Klasse" 7 "T_Klasse" 6 "D_Klasse" 5 "C_Klasse" 4 "B_Klasse" 3 "A_Klasse" 2 "A0_Klasse" 1 "A00_Klasse" 0 "A000_Klasse" ;
VAL_ 1488 SY1_Fzg_Marke 15 "Porsche" 14 "Ford" 8 "RollsRoyce" 7 "Bentley" 6 "Lamborghini" 5 "Bugatti" 4 "VN_VWNutzfzg" 3 "SK_Skoda" 2 "SE_Seat" 1 "AU_Audi" 0 "VW_Volkswagen" ;
VAL_ 1488 SY1_Fzg_Derivat 15 "nicht_bekannt" 9 "Sonstige" 8 "MPV" 7 "CityVan_PickUp" 6 "Offroad" 5 "Cabrio_Roadstar_Spider" 4 "Coupe_Sportwagen" 3 "Fliessheck" 2 "Variant" 1 "Stufenheck_Nutz" 0 "Kurzheck_Multivan" ;
VAL_ 1488 SY1_Fzg_Index 15 "nicht_bekannt" 9 "Sonstige" 8 "Hochdach" 7 "Flachdach" 6 "geschlossene_Aufbauten" 5 "offene_Aufbauten" 4 "Hochmotorisierung" 3 "Syncro" 2 "geaenderte_Front_Heck" 1 "langer_Radstand" 0 "kurzer_Radstand" ;
VAL_ 1488 SY1_Tueren 1 "Vier_Tueren_oder_mehr" 0 "Kleiner_vier_Tueren" ;
VAL_ 1488 SY1_Transportmode 1 "aktiv" 0 "nicht_aktiv" ;
VAL_ 1488 SY1_Fehlereintr 1 "Fehlerspeichereintrag" 0 "kein_Fehlerspeichereintrag" ;
VAL_ 1488 SY1_Relais_FAS_Zweig 3 "reserviert" 2 "Relais_im_Fehlerfall_geoeffnet" 1 "Relais_planmaessig_geoeffnet" 0 "Relais_geschlossen" ;
VAL_ 1488 SY1_ELV_Lock_Supply 1 "Freigabe" 0 "keine_Freigabe" ;
VAL_ 1488 SY1_QRS_Messmodus 1 "QRS_ein" 0 "QRS_aus" ;
VAL_ 1488 SY1_NWDF_gueltig 1 "NWDF_Fkt_unterstuetzt" 0 "NWDF_Fkt_nicht_unterstuetzt" ;
VAL_ 1488 SY1_NWDF 1 "Ueberwachung_freigegeben" 0 "Ueberwachung_nicht_freigegeben" ;
VAL_ 1488 SY1_Notbrems_Status 1 "Notbremssituation" 0 "keine_Notbremsung" ;
VAL_ 1838 NMH_BMS_Start_1 1 "START_v_SLEEP" ;
VAL_ 1838 NMH_BMS_Start_2 1 "START_v_PREP_TO_SLEEP" ;
VAL_ 1838 NMH_BMS_Normal_Mode_1 1 "NORMAL_MODE_v_START" ;
VAL_ 1838 NMH_BMS_Normal_Mode_2 1 "NORMAL_MODE_v_READY_TO_SLEEP" ;
VAL_ 1838 NMH_BMS_Car_WakeUp 1 "Car_WakeUp" ;
VAL_ 1838 NMH_BMS_Per_WakeUp 3 "KL_15_HW" 2 "P_Wakeup_Ursache_unbekannt" 1 "CAN" 0 "Funktionswakeup" ;
VAL_ 1838 NMH_BMS_Fkt_WakeUp 0 "Peripheriewakeup" ;
VAL_ 1838 NMH_BMS_NM_aktiv_Klemme_15 1 "Klemme_15_ein" ;
VAL_ 1838 NMH_BMS_NM_aktiv_Diagnose 1 "Diagnose_bei_Kl_15_aus" ;
VAL_ 1838 NMH_BMS_NM_aktiv_Start 1 "Mindestaktivzeit_START" ;
VAL_ 1838 NMH_BMS_NL_aktiv_4 1 "HV_aktiv" ;
VAL_ 1838 NMH_BMS_NL_aktiv_5 1 "Nachlaufursache_5" ;
VAL_ 1838 NMH_BMS_NL_aktiv_6 1 "Nachlaufursache_6" ;
VAL_ 1838 NMH_BMS_NL_aktiv_7 1 "Nachlaufursache_7" ;
VAL_ 1838 NMH_BMS_NL_aktiv_8 1 "Nachlaufursache_8" ;
VAL_ 1838 NMH_BMS_NL_0 1 "EEPROM_Schreibzugriff" ;
VAL_ 1838 NMH_BMS_NL_1 1 "Luefter_aktiv" ;
VAL_ 1838 NMH_BMS_TimeOut_Fehler 1 "Timeout_Fehlereintrag" ;
VAL_ 1838 NMH_BMS_CAN_Diag_deaktiv 1 "keine_CANbez_Eigendiag" ;
VAL_ 1838 NMH_BMS_KompSchutz 1 "Komponentenschutz_aktiv" ;
VAL_ 1838 NMH_BMS_Mute_Mode 1 "Mute_Mode_aktiv" ;
VAL_ 1838 NMH_BMS_Transport_Mode 1 "Transport_Mode_aktiv" ;
VAL_ 1838 NMH_BMS_Abschaltstufe_aktiv 1 "Abschaltstufe_aktiv" ;
VAL_ 1838 NMH_BMS_Eindraht_Fehler 1 "Eindrahtbetrieb_erkannt" ;
VAL_ 1839 NMH_EM_Start_1 1 "START_v_SLEEP" ;
VAL_ 1839 NMH_EM_Start_2 1 "START_v_PREP_TO_SLEEP" ;
VAL_ 1839 NMH_EM_Normal_Mode_1 1 "NORMAL_MODE_v_START" ;
VAL_ 1839 NMH_EM_Normal_Mode_2 1 "NORMAL_MODE_v_READY_TO_SLEEP" ;
VAL_ 1839 NMH_EM_Car_WakeUp 1 "Car_WakeUp" ;
VAL_ 1839 NMH_EM_Per_WakeUp 3 "KL_15_HW" 2 "P_Wakeup_Ursache_unbekannt" 1 "CAN" 0 "Funktionswakeup" ;
VAL_ 1839 NMH_EM_Fkt_WakeUp 0 "Peripheriewakeup" ;
VAL_ 1839 NMH_EM_NM_aktiv_Klemme_15 1 "Klemme_15_ein" ;
VAL_ 1839 NMH_EM_NM_aktiv_Diagnose 1 "Diagnose_bei_Kl_15_aus" ;
VAL_ 1839 NMH_EM_NM_aktiv_Start 1 "Mindestaktivzeit_START" ;
VAL_ 1839 NMH_EM_NL_aktiv_4 1 "HV_Entladung_nicht_moeglich" 0 "kein_Nachlauf" ;
VAL_ 1839 NMH_EM_NL_aktiv_5 1 "Nachlaufursache_5" ;
VAL_ 1839 NMH_EM_NL_aktiv_6 1 "Nachlaufursache_6" ;
VAL_ 1839 NMH_EM_NL_aktiv_7 1 "Nachlaufursache_7" ;
VAL_ 1839 NMH_EM_NL_aktiv_8 1 "Nachlaufursache_8" ;
VAL_ 1839 NMH_EM_NL_0 1 "EEPROM_Schreibzugriff" ;
VAL_ 1839 NMH_EM_NL_1 1 "Kuehlpumpe_aktiv" ;
VAL_ 1839 NMH_EM_TimeOut_Fehler 1 "Timeout_Fehlereintrag" ;
VAL_ 1839 NMH_EM_CAN_Diag_deaktiv 1 "keine_CANbez_Eigendiag" ;
VAL_ 1839 NMH_EM_KompSchutz 1 "Komponentenschutz_aktiv" ;
VAL_ 1839 NMH_EM_Mute_Mode 1 "Mute_Mode_aktiv" ;
VAL_ 1839 NMH_EM_Transport_Mode 1 "Transport_Mode_aktiv" ;
VAL_ 1839 NMH_EM_Abschaltstufe_aktiv 1 "Abschaltstufe_aktiv" ;
VAL_ 1839 NMH_EM_Eindraht_Fehler 1 "Eindrahtbetrieb_erkannt" ;
VAL_ 1849 NMH_EPB_Start_1 1 "START_v_SLEEP" ;
VAL_ 1849 NMH_EPB_Start_2 1 "START_v_PREP_TO_SLEEP" ;
VAL_ 1849 NMH_EPB_Normal_Mode_1 1 "NORMAL_MODE_v_START" ;
VAL_ 1849 NMH_EPB_Normal_Mode_2 1 "NORMAL_MODE_v_READY_TO_SLEEP" ;
VAL_ 1849 NMH_EPB_Car_WakeUp 1 "Car_WakeUp" ;
VAL_ 1849 NMH_EPB_Per_WakeUp 5 "Schalter_EPB" 3 "KL_15_HW" 2 "P_Wakeup_Ursache_unbekannt" 1 "CAN" 0 "Funktionswakeup" ;
VAL_ 1849 NMH_EPB_Fkt_WakeUp 0 "Peripheriewakeup" ;
VAL_ 1849 NMH_EPB_NM_aktiv_Klemme_15 1 "Klemme_15_ein" ;
VAL_ 1849 NMH_EPB_NM_aktiv_Diagnose 1 "Diagnose_bei_Kl_15_aus" ;
VAL_ 1849 NMH_EPB_NM_aktiv_Start 1 "Mindestaktivzeit_START" ;
VAL_ 1849 NMH_EPB_NL_aktiv_4 1 "Nachlaufursache_4" ;
VAL_ 1849 NMH_EPB_NL_aktiv_5 1 "Nachlaufursache_5" ;
VAL_ 1849 NMH_EPB_NL_aktiv_6 1 "Nachlaufursache_6" ;
VAL_ 1849 NMH_EPB_NL_aktiv_7 1 "Nachlaufursache_7" ;
VAL_ 1849 NMH_EPB_NL_aktiv_8 1 "Nachlaufursache_8" ;
VAL_ 1849 NMH_EPB_TimeOut_Fehler 1 "Timeout_Fehlereintrag" ;
VAL_ 1849 NMH_EPB_CAN_Diag_deaktiv 1 "keine_CANbez_Eigendiag" ;
VAL_ 1849 NMH_EPB_KompSchutz 1 "Komponentenschutz_aktiv" ;
VAL_ 1849 NMH_EPB_Mute_Mode 1 "Mute_Mode_aktiv" ;
VAL_ 1849 NMH_EPB_Transport_Mode 1 "Transport_Mode_aktiv" ;
VAL_ 1849 NMH_EPB_Abschaltstufe_aktiv 1 "Abschaltstufe_aktiv" ;
VAL_ 1849 NMH_EPB_Eindraht_Fehler 1 "Eindrahtbetrieb_erkannt" ;
VAL_ 1824 NMH_GW_Start_1 1 "START_v_SLEEP" ;
VAL_ 1824 NMH_GW_Start_2 1 "START_v_PREP_TO_SLEEP" ;
VAL_ 1824 NMH_GW_Normal_Mode_1 1 "NORMAL_MODE_v_START" ;
VAL_ 1824 NMH_GW_Normal_Mode_2 1 "NORMAL_MODE_v_READY_TO_SLEEP" ;
VAL_ 1824 NMH_GW_Car_WakeUp 1 "Car_WakeUp" ;
VAL_ 1824 NMH_GW_Per_WakeUp 12 "DiagCANTransceiver" 11 "WULtg" 10 "LIN2Transceiver" 9 "LIN1Transceiver" 8 "ECANTransceiver" 7 "ICANTransceiver" 6 "KCANTransceiver" 5 "DCANTransceiver" 4 "ACANTransceiver" 3 "KL_15_HW" 2 "P_Wakeup_Ursache_unbekannt" 1 "CAN" 0 "Funktionswakeup" ;
VAL_ 1824 NMH_GW_Fkt_WakeUp 7 "BEM" 6 "LIN1Event" 5 "ECANEvent" 4 "ICANEvent" 3 "KCANEvent" 2 "KBICANEvent" 1 "ACANEvent" 0 "Peripheriewakeup" ;
VAL_ 1824 NMH_GW_NM_aktiv_Klemme_15 1 "Klemme_15_ein" ;
VAL_ 1824 NMH_GW_NM_aktiv_Diagnose 1 "Diagnose_bei_Kl_15_aus" ;
VAL_ 1824 NMH_GW_NM_aktiv_Start 1 "Mindestaktivzeit_START" ;
VAL_ 1824 NMH_GW_NL_aktiv_4 1 "Nachlaufursache_4" ;
VAL_ 1824 NMH_GW_NL_aktiv_5 1 "Nachlaufursache_5" ;
VAL_ 1824 NMH_GW_NL_aktiv_6 1 "Nachlaufursache_6" ;
VAL_ 1824 NMH_GW_NL_aktiv_7 1 "Nachlaufursache_7" ;
VAL_ 1824 NMH_GW_NL_aktiv_8 1 "Nachlaufursache_8" ;
VAL_ 1824 NMH_GW_NL_0 1 "" ;
VAL_ 1824 NMH_GW_TimeOut_Fehler 1 "Timeout_Fehlereintrag" ;
VAL_ 1824 NMH_GW_CAN_Diag_deaktiv 1 "keine_CANbez_Eigendiag" ;
VAL_ 1824 NMH_GW_KompSchutz 1 "Komponentenschutz_aktiv" ;
VAL_ 1824 NMH_GW_Mute_Mode 1 "Mute_Mode_aktiv" ;
VAL_ 1824 NMH_GW_Transport_Mode 1 "Transport_Mode_aktiv" ;
VAL_ 1824 NMH_GW_Abschaltstufe_aktiv 1 "Abschaltstufe_aktiv" ;
VAL_ 1824 NMH_GW_Eindraht_Fehler 1 "Eindrahtbetrieb_erkannt" ;
VAL_ 1826 NMH_Getriebe_Start_1 1 "START_v_SLEEP" ;
VAL_ 1826 NMH_Getriebe_Start_2 1 "START_v_PREP_TO_SLEEP" ;
VAL_ 1826 NMH_Getriebe_Normal_Mode_1 1 "NORMAL_MODE_v_START" ;
VAL_ 1826 NMH_Getriebe_Normal_Mode_2 1 "NORMAL_MODE_v_READY_TO_SLEEP" ;
VAL_ 1826 NMH_Getriebe_Car_WakeUp 1 "Car_WakeUp" ;
VAL_ 1826 NMH_Getriebe_Per_WakeUp 3 "KL_15_HW" 2 "P_Wakeup_Ursache_unbekannt" 1 "CAN" 0 "Funktionswakeup" ;
VAL_ 1826 NMH_Getriebe_Fkt_WakeUp 0 "Peripheriewakeup" ;
VAL_ 1826 NMH_Getriebe_NM_aktiv_Klemme_15 1 "Klemme_15_ein" ;
VAL_ 1826 NMH_Getriebe_NM_aktiv_Diagnose 1 "Diagnose_bei_Kl_15_aus" ;
VAL_ 1826 NMH_Getriebe_NM_aktiv_Start 1 "Mindestaktivzeit_START" ;
VAL_ 1826 NMH_Getriebe_NL_aktiv_4 1 "Nachlaufursache_4" ;
VAL_ 1826 NMH_Getriebe_NL_aktiv_5 1 "Nachlaufursache_5" ;
VAL_ 1826 NMH_Getriebe_NL_aktiv_6 1 "Nachlaufursache_6" ;
VAL_ 1826 NMH_Getriebe_NL_aktiv_7 1 "Nachlaufursache_7" ;
VAL_ 1826 NMH_Getriebe_NL_aktiv_8 1 "Nachlaufursache_8" ;
VAL_ 1826 NMH_Getriebe_TimeOut_Fehler 1 "Timeout_Fehlereintrag" ;
VAL_ 1826 NMH_Getriebe_CAN_Diag_deaktiv 1 "keine_CANbez_Eigendiag" ;
VAL_ 1826 NMH_Getriebe_KompSchutz 1 "Komponentenschutz_aktiv" ;
VAL_ 1826 NMH_Getriebe_Mute_Mode 1 "Mute_Mode_aktiv" ;
VAL_ 1826 NMH_Getriebe_Transport_Mode 1 "Transport_Mode_aktiv" ;
VAL_ 1826 NMH_Getriebe_Abschaltstufe_aktiv 1 "Abschaltstufe_aktiv" ;
VAL_ 1826 NMH_Getriebe_Eindraht_Fehler 1 "Eindrahtbetrieb_erkannt" ;
VAL_ 1834 NMH_GE_02_Start_1 1 "START_v_SLEEP" ;
VAL_ 1834 NMH_GE_02_Start_2 1 "START_v_PREP_TO_SLEEP" ;
VAL_ 1834 NMH_GE_02_Normal_Mode_1 1 "NORMAL_MODE_v_START" ;
VAL_ 1834 NMH_GE_02_Normal_Mode_2 1 "NORMAL_MODE_v_READY_TO_SLEEP" ;
VAL_ 1834 NMH_GE_02_Car_WakeUp 1 "Car_WakeUp" ;
VAL_ 1834 NMH_GE_02_Per_WakeUp 3 "KL_15_HW" 2 "P_Wakeup_Ursache_unbekannt" 1 "CAN" 0 "Funktionswakeup" ;
VAL_ 1834 NMH_GE_02_Fkt_WakeUp 0 "Peripheriewakeup" ;
VAL_ 1834 NMH_GE_02_NM_aktiv_Klemme_15 1 "Klemme_15_ein" ;
VAL_ 1834 NMH_GE_02_NM_aktiv_Diagnose 1 "Diagnose_bei_Kl_15_aus" ;
VAL_ 1834 NMH_GE_02_NM_aktiv_Start 1 "Mindestaktivzeit_START" ;
VAL_ 1834 NMH_GE_02_N_Haltephase 1 "Nachlaufursache_4" ;
VAL_ 1834 NMH_GE_02_Positionsanzeige 1 "Positionsanzeige_aktiv" ;
VAL_ 1834 NMH_GE_02_kein_NL 1 "kein_lokaler_Nachlauf" ;
VAL_ 1834 NMH_GE_02_NL_Daten_EEPROM 1 "Klemme_15_ein" ;
VAL_ 1834 NMH_GE_02_NL_Drucksens 1 "Klemme_15_ein" ;
VAL_ 1834 NMH_GE_02_NL_Abtrieb 1 "Klemme_15_ein" ;
VAL_ 1834 NMH_GE_02_NL_Waehlhebel 1 "Klemme_15_ein" ;
VAL_ 1834 NMH_GE_02_NL_Wegfahrsperre 1 "Klemme_15_ein" ;
VAL_ 1834 NMH_GE_02_Signalfehler 1 "Timeout_Fehlereintrag" ;
VAL_ 1834 NMH_GE_02_TimeOut_Fehler 1 "Timeout_Fehlereintrag" ;
VAL_ 1834 NMH_GE_02_CAN_Diag_deaktiv 1 "keine_CANbez_Eigendiag" ;
VAL_ 1834 NMH_GE_02_KompSchutz 1 "Komponentenschutz_aktiv" ;
VAL_ 1834 NMH_GE_02_Mute_Mode 1 "Mute_Mode_aktiv" ;
VAL_ 1834 NMH_GE_02_Transport_Mode 1 "Transport_Mode_aktiv" ;
VAL_ 1834 NMH_GE_02_Abschaltstufe_aktiv 1 "Abschaltstufe_aktiv" ;
VAL_ 1834 NMH_GE_02_Eindraht_Fehler 1 "Eindrahtbetrieb_erkannt" ;
VAL_ 1836 NMH_Lademanager_Start_1 1 "START_v_SLEEP" ;
VAL_ 1836 NMH_Lademanager_Start_2 1 "START_v_PREP_TO_SLEEP" ;
VAL_ 1836 NMH_Lademanager_Normal_Mode_1 1 "NORMAL_MODE_v_START" ;
VAL_ 1836 NMH_Lademanager_Normal_Mode_2 1 "NORMAL_MODE_v_READY_TO_SLEEP" ;
VAL_ 1836 NMH_Lademanager_Car_WakeUp 1 "Car_WakeUp" ;
VAL_ 1836 NMH_Lademanager_Per_WakeUp 10 "Nicht_belegter_Port_weckt" 9 "Interner_Watchdog_Reset" 8 "Interner_Reset" 7 "Ladedose_B_Stecker_stecken" 6 "Ladedose_A_Stecker_stecken" 5 "Chademo_StartStop" 4 "Taster_Sofortladen" 3 "KL_15_HW" 2 "P_Wakeup_Ursache_unbekannt" 1 "CAN" 0 "Funktionswakeup" ;
VAL_ 1836 NMH_Lademanager_Fkt_WakeUp 5 "Externer_Watchdog" 4 "Interner_Reset" 3 "Kl_30_Reset" 2 "RTC_Mitternachtswecker" 1 "RTC_Timer" 0 "Peripheriewakeup" ;
VAL_ 1836 NMH_Lademanager_NM_aktiv_Klemme_15 1 "Klemme_15_ein" ;
VAL_ 1836 NMH_Lademanager_NM_aktiv_Diagnose 1 "Diagnose_bei_Kl_15_aus" ;
VAL_ 1836 NMH_Lademanager_NM_aktiv_Start 1 "Mindestaktivzeit_START" ;
VAL_ 1836 NMH_Lademanager_NL_aktiv_4 1 "Ladezeitberechnung" ;
VAL_ 1836 NMH_Lademanager_NL_aktiv_5 1 "Ladevorgang_aktiv" ;
VAL_ 1836 NMH_Lademanager_NL_aktiv_6 1 "Batterietemperierung_aktiv" ;
VAL_ 1836 NMH_Lademanager_NL_aktiv_7 1 "Fahrprofilanpassung" ;
VAL_ 1836 NMH_Lademanager_NL_aktiv_8 1 "Nachlaufursache_8" ;
VAL_ 1836 NMH_Lademanager_TimeOut_Fehler 1 "Timeout_Fehlereintrag" ;
VAL_ 1836 NMH_Lademanager_CAN_Diag_deaktiv 1 "keine_CANbez_Eigendiag" ;
VAL_ 1836 NMH_Lademanager_KompSchutz 1 "Komponentenschutz_aktiv" ;
VAL_ 1836 NMH_Lademanager_Mute_Mode 1 "Mute_Mode_aktiv" ;
VAL_ 1836 NMH_Lademanager_Transport_Mode 1 "Transport_Mode_aktiv" ;
VAL_ 1836 NMH_Lademanager_Abschaltstufe_aktiv 1 "Abschaltstufe_aktiv" ;
VAL_ 1836 NMH_Lademanager_Eindraht_Fehler 1 "Eindrahtbetrieb_erkannt" ;
VAL_ 1825 NMH_MO_Start_1 1 "START_v_SLEEP" ;
VAL_ 1825 NMH_MO_Start_2 1 "START_v_PREP_TO_SLEEP" ;
VAL_ 1825 NMH_MO_Normal_Mode_1 1 "NORMAL_MODE_v_START" ;
VAL_ 1825 NMH_MO_Normal_Mode_2 1 "NORMAL_MODE_v_READY_TO_SLEEP" ;
VAL_ 1825 NMH_MO_Car_WakeUp 1 "Car_WakeUp" ;
VAL_ 1825 NMH_MO_Per_WakeUp 5 "Ladestecker_gesteckt" 4 "analoge_Weckleitung" 3 "KL_15_HW" 2 "P_Wakeup_Ursache_unbekannt" 1 "CAN" 0 "Funktionswakeup" ;
VAL_ 1825 NMH_MO_Fkt_WakeUp 0 "Peripheriewakeup" ;
VAL_ 1825 NMH_MO_NM_aktiv_Klemme_15 1 "Klemme_15_ein" ;
VAL_ 1825 NMH_MO_NM_aktiv_Diagnose 1 "Diagnose_bei_Kl_15_aus" ;
VAL_ 1825 NMH_MO_NM_aktiv_Start 1 "Mindestaktivzeit_START" ;
VAL_ 1825 NMH_MO_NL_aktiv_4 1 "EKP_Vorlauf" ;
VAL_ 1825 NMH_MO_NL_aktiv_5 1 "STH_Betrieb" ;
VAL_ 1825 NMH_MO_NL_aktiv_6 1 "Abschaltung_aktiv" ;
VAL_ 1825 NMH_MO_NL_aktiv_7 1 "Innenraumklimatisierung_oder_Betankung" ;
VAL_ 1825 NMH_MO_NL_aktiv_8 1 "LM_Systemanforderung" ;
VAL_ 1825 NMH_MO_NL_1 1 "Kuehlerluefter_Strg_ZWP_aktiv" ;
VAL_ 1825 NMH_MO_NL_2 1 "Diagnosefunktionen_aktiv" ;
VAL_ 1825 NMH_MO_NL_3 1 "WFS_aktiv" ;
VAL_ 1825 NMH_MO_NL_4 1 "EEPROM_Zugriffe_RAM_ROM_Tests" ;
VAL_ 1825 NMH_MO_NL_5 1 "Sonstige_Nachlaeufe_aktiv" ;
VAL_ 1825 NMH_MO_TimeOut_Fehler 1 "Timeout_Fehlereintrag" ;
VAL_ 1825 NMH_MO_CAN_Diag_deaktiv 1 "keine_CANbez_Eigendiag" ;
VAL_ 1825 NMH_MO_KompSchutz 1 "Komponentenschutz_aktiv" ;
VAL_ 1825 NMH_MO_Mute_Mode 1 "Mute_Mode_aktiv" ;
VAL_ 1825 NMH_MO_Transport_Mode 1 "Transport_Mode_aktiv" ;
VAL_ 1825 NMH_MO_Abschaltstufe_aktiv 1 "Abschaltstufe_aktiv" ;
VAL_ 1825 NMH_MO_Eindraht_Fehler 1 "Eindrahtbetrieb_erkannt" ;
VAL_ 946 BEM_HYB_DC_uMinLV 255 "Fehler" 254 "Init" ;
VAL_ 946 BEM_Freigabe_HV_Ladung 1 "HV_Ladung_freigegeben" 0 "HV_Ladung_nicht_freigegeben" ;
VAL_ 946 BEM_Hybrid_Info 3 "Systemfehler" 2 "kein_Motorstart_ueber_12V_Starter_nach_el_Fahrtbetrieb" 1 "Motorstart_ueber_12V_Starter_nur_bei_0kmh_moeglich" 0 "keine_Einschraenkung_durch_Energiemanagement" ;
VAL_ 946 BEM_NV_NachladAnf 3 "Fehler" 2 "Init" 1 "Anforderung_NV_Nachladung" 0 "keine_Anforderung" ;
VAL_ 946 NVEM_Fahrbereit_Handshake 7 "Fehler" 6 "Init" 5 "reserviert" 4 "reserviert" 3 "Fahrbereitsschaft_weg" 2 "Fahreinschraenkung" 1 "Messvorgang_aktiv" 0 "iO" ;
VAL_ 946 BEM_Generatordiagnose 3 "Hybrid_DC_DC_Wandler_defekt" 2 "Generator_def" 1 "Ladekontrolle_ein" 0 "keine_Anzeige" ;
VAL_ 946 BEM_Ladezustand 15 "Fehler" 14 "Init" ;
VAL_ 945 DC_HYB_iAktLV 1023 "Fehler" 1022 "Init" ;
VAL_ 945 DC_HYB_iAktReserveLV 1023 "Fehler" 1022 "Init" ;
VAL_ 945 DC_HYB_uAktLV 255 "Fehler" 254 "Init" ;
VAL_ 945 DC_HYB_LangsRegelung 1 "langsame_Regelung" 0 "normale_Regelung" ;
VAL_ 945 DC_HYB_Abregelung_Temperatur 1 "Abregelung_Temperatur" 0 "keine_Begrenzung" ;
VAL_ 945 DC_HYB_Fehler_RedLeistung 1 "Fehler_RedLeistung" 0 "kein_Fehler" ;
VAL_ 945 DC_HYB_Fehler_intern 1 "Fehler_intern" 0 "kein_Fehler" ;
VAL_ 945 DC_HYB_Fehler_Spannung 1 "Fehler_Spannung" 0 "kein_Fehler" ;
VAL_ 945 DC_TiefsetzBereit 1 "Tiefsetzbereit" 0 "Standby" ;
VAL_ 945 DC_HYB_Auslastungsgrad 255 "Fehler" ;
VAL_ 19 WFS_GSG_Status_Antwort 1 "bewerten" 0 "verwerfen" ;
VAL_ 19 WFS_GSG_Status_Lesespule 1 "kein Fehler" 0 "Fehler" ;
VAL_ 19 WFS_GSG_Status_Schluessel 1 "berechtigt" 0 "nicht berechtigt" ;
VAL_ 19 WFS_GSG_Status_Anfrage 1 "i.O." 0 "n.i.O." ;
VAL_ 19 WFS_GSG_Status_P_Klasse 1 "i.O." 0 "n.i.O." ;
VAL_ 17 WFS_MSG1_Status_Antwort 1 "bewerten" 0 "verwerfen" ;
VAL_ 17 WFS_MSG1_Status_Lesespule 1 "kein Fehler" 0 "Fehler" ;
VAL_ 17 WFS_MSG1_Status_Schluessel 1 "berechtigt" 0 "nicht berechtigt" ;
VAL_ 17 WFS_MSG1_Status_Anfrage 1 "i.O." 0 "n.i.O." ;
VAL_ 17 WFS_MSG1_Status_P_Klasse 1 "i.O." 0 "n.i.O." ;
VAL_ 21 WFS_MSG2_Status_Antwort 1 "bewerten" 0 "verwerfen" ;
VAL_ 21 WFS_MSG2_Status_Lesespule 1 "kein Fehler" 0 "Fehler" ;
VAL_ 21 WFS_MSG2_Status_Schluessel 1 "berechtigt" 0 "nicht berechtigt" ;
VAL_ 21 WFS_MSG2_Status_Anfrage 1 "i.O." 0 "n.i.O." ;
VAL_ 21 WFS_MSG2_Status_P_Klasse 1 "i.O." 0 "n.i.O." ;
VAL_ 23 WFS_MSG3_Status_Antwort 1 "bewerten" 0 "verwerfen" ;
VAL_ 23 WFS_MSG3_Status_Lesespule 1 "kein Fehler" 0 "Fehler" ;
VAL_ 23 WFS_MSG3_Status_Schluessel 1 "berechtigt" 0 "nicht berechtigt" ;
VAL_ 23 WFS_MSG3_Status_Anfrage 1 "i.O." 0 "n.i.O." ;
VAL_ 23 WFS_MSG3_Status_P_Klasse 1 "i.O." 0 "n.i.O." ;
VAL_ 25 WFS_MSG4_Status_Antwort 1 "bewerten" 0 "verwerfen" ;
VAL_ 25 WFS_MSG4_Status_Lesespule 1 "kein Fehler" 0 "Fehler" ;
VAL_ 25 WFS_MSG4_Status_Schluessel 1 "berechtigt" 0 "nicht berechtigt" ;
VAL_ 25 WFS_MSG4_Status_Anfrage 1 "i.O." 0 "n.i.O." ;
VAL_ 25 WFS_MSG4_Status_P_Klasse 1 "i.O." 0 "n.i.O." ;
VAL_ 1386 ACA_StaACC 7 "ACC_irrev_aus" 6 "ACC_rev_aus" 5 "frei" 4 "ACC_im_Hintergrund" 3 "ACC_aktiv" 2 "ACC_passiv" 1 "Reserve" 0 "Hauptschalter_aus" ;
VAL_ 1386 ACA_ID_StaACC 0 "keine_Anzeige" ;
VAL_ 1386 ACA_Fahrerhinw 1 "Ein" 0 "Aus" ;
VAL_ 1386 ACA_AnzDisplay 1 "Anzeige_erw" 0 "Anzeige_nicht_erw" ;
VAL_ 1386 ACA_Zeitluecke 15 "Zeitluecke15" 14 "Zeitluecke14" 13 "Zeitluecke13" 12 "Zeitluecke12" 11 "Zeitluecke11" 10 "Zeitluecke10" 9 "Zeitluecke9" 8 "Zeitluecke8" 7 "Zeitluecke7" 6 "Zeitluecke6" 5 "Zeitluecke5" 4 "Zeitluecke4" 3 "Zeitluecke3" 2 "Zeitluecke2" 1 "Zeitluecke1" 0 "nicht_definiert" ;
VAL_ 1386 ACA_V_Wunsch 255 "kein_Wert_im_Speicher" ;
VAL_ 1386 ACA_kmh_mph 1 "mph" 0 "km_h" ;
VAL_ 1386 ACA_Akustik1 1 "Gong" 0 "kein_Gong" ;
VAL_ 1386 ACA_Akustik2 1 "Summer" 0 "kein_Summer" ;
VAL_ 1386 ACA_PrioDisp 3 "keine_Anzeige_Anf" 2 "niedrige_Prio" 1 "mittlere_Prio" 0 "hohe_Prio" ;
VAL_ 1386 ACA_gemZeitl 15 "Zeitluecke15" 14 "Zeitluecke14" 13 "Zeitluecke13" 12 "Zeitluecke12" 11 "Zeitluecke11" 10 "Zeitluecke10" 9 "Zeitluecke9" 8 "Zeitluecke8" 7 "Zeitluecke7" 6 "Zeitluecke6" 5 "Zeitluecke5" 4 "Zeitluecke4" 3 "Zeitluecke3" 2 "Zeitluecke2" 1 "Zeitluecke1" 0 "Kein_Objekt_erfasst" ;
VAL_ 1386 ACA_ACC_Verz 1 "ACC_verzoegert" 0 "ACC_verzoegert_nicht" ;
VAL_ 1386 ACA_StaGRA 7 "GRA_Fehler" 6 "frei" 5 "frei" 4 "GRA_uebertreten" 3 "GRA_aktiv" 2 "GRA_passiv" 1 "Reserve" 0 "Hauptschalter_aus" ;
VAL_ 1386 ACA_ID_StaGRA 0 "keine_Anzeige" ;
VAL_ 1386 ACA_Codierung 1 "GRA" 0 "ACC" ;
VAL_ 1386 ACA_Tachokranz 1 "beleuchtet" 0 "nicht_beleuchtet" ;
VAL_ 1386 ACA_Aend_Zeitluecke 1 "Anzeige_angef" 0 "keine_Anzeige" ;
VAL_ 872 ACS_Sta_ADR 3 "irrev_Fehler" 2 "ADR_passiv" 1 "ADR_aktiv" 0 "ADR_nicht_aktiv" ;
VAL_ 872 ACS_ADR_Schub 1 "Verz_begr_auf_Schub" 0 "Verz_nicht_begr_auf_Schub" ;
VAL_ 872 ACS_Schubabsch 1 "SA_nicht_zulaessig" 0 "SA_zulaessig" ;
VAL_ 872 ACS_StSt_Info 3 "Systemfehler" 2 "Motoranlauf_zwingend_notwendig_(Startanforderung)" 1 "Motoranlauf_nicht_zwingend_notwendig_(Stoppverbot,keine_Startanforderung)" 0 "Motorlauf_nicht_notwendig_(Stoppfreigabe)" ;
VAL_ 872 ACS_MomEingriff 1 "MomEingr_verhindern" 0 "keine_Beeinfl_MomEingr_Mot" ;
VAL_ 872 ACS_Typ_ACC 3 "ACC_nicht_verbaut" 2 "frei" 1 "ACC_mit_FollowToStop" 0 "Basis_ACC" ;
VAL_ 872 ACS_FreigSollB 1 "Sollbeschl_freigeg" 0 "Sollbeschl_nicht_freigeg" ;
VAL_ 872 ACS_Sollbeschl 2047 "Fehler" 2046 "ADR_nicht_aktiv" ;
VAL_ 872 ACS_Anhaltewunsch 1 "Fzg_haelt_an" 0 "kein_Haltewunsch" ;
VAL_ 872 ACS_Fehler 1 "Fehlerspeichereintrag" 0 "kein_Fehlerspeichereintrag" ;
VAL_ 872 ACS_zul_Regelabw 255 "Fehler" 254 "ADR_nicht_aktiv" ;
VAL_ 872 ACS_max_AendGrad 255 "Fehler" 254 "Neutralwert" 0 "Neutralwert" ;
VAL_ 1688 AFZ_ParaSW_L 1 "Parametrisierung_erfolgt" 0 "Parametrisierung_nicht_erfolgt" ;
VAL_ 1688 AFZ_ParaSW_R 1 "Parametrisierung_erfolgt" 0 "Parametrisierung_nicht_erfolgt" ;
VAL_ 1688 AFZ_Modus 1 "AFS_ausgeschaltet" 0 "AFS_aktiv" ;
VAL_ 1688 AFZ_Init 1 "Initlauf_erfolgt" 0 "Initlauf_nicht_erfolgt" ;
VAL_ 1688 AFZ_SafePos 1 "Sicherheitsposition_ein" 0 "Sicherheitsposition_aus" ;
VAL_ 1688 AFZ_IstPosMot_L 255 "Fehler" 254 "Wert_ist_unbekannt" ;
VAL_ 1688 AFZ_IstPosMot_R 255 "Fehler" 254 "Wert_ist_unbekannt" ;
VAL_ 1688 AFZ_Soll_EVG 255 "Fehler" 254 "Wert_ist_unbekannt" ;
VAL_ 1688 AFZ_IstDimAbLi 255 "Fehler" 254 "Wert_ist_unbekannt" ;
VAL_ 1688 AFZ_IstDimAbRe 255 "Fehler" 254 "Wert_ist_unbekannt" ;
VAL_ 1688 AFZ_StaLamp_L 1 "Fehler" 0 "kein_Fehler" ;
VAL_ 1688 AFZ_StaLamp_R 1 "Fehler" 0 "kein_Fehler" ;
VAL_ 1360 AB2_Beleg_HF 3 "hinten_Fahrer_belegt" 2 "hinten_Fahrer_nicht_belegt" 1 "hinten_Fahrer_Fehler" 0 "hinten_Fahrer_nicht_verfuegbar" ;
VAL_ 1360 AB2_Beleg_HBF 3 "hinten_Beifahrer_belegt" 2 "hinten_Beifahrer_nicht_belegt" 1 "hinten_Beifahrer_Fehler" 0 "hinten_Beif_nicht_verfuegbar" ;
VAL_ 1360 AB2_Beleg_HM 3 "hinten_Mitte_belegt" 2 "hinten_Mitte_nicht_belegt" 1 "hinten_Mitte_Fehler" 0 "hinten_Mitte_nicht_verfuegbar" ;
VAL_ 1360 AB2_Beleg_BF 3 "Beifahrersitz_belegt" 2 "Beifahrersitz_nicht_belegt" 1 "Fehler" 0 "nicht_verfuegbar" ;
VAL_ 1360 AB2_OOP_Fa 7 "nicht_benutzt" 6 "Fahrer_out_of_pos_30" 5 "Fahrer_out_of_pos_70" 4 "Fahrer_in_Position" 1 "Fehler" 0 "nicht_verfuegbar" ;
VAL_ 1360 AB2_OOP_BF 7 "nicht_benutzt" 6 "Fahrer_out_of_pos_30" 5 "Fahrer_out_of_pos_70" 4 "Fahrer_in_Position" 1 "Fehler" 0 "nicht_verfuegbar" ;
VAL_ 1360 AB2_Sta_BF 3 "nicht_benutzt" 2 "BF_Airbag_aktiviert" 1 "BF_Airbag_deaktiviert" 0 "keine_Anzeige" ;
VAL_ 1360 AB2_Gurt_2FaS 3 "Gurt_gesteckt" 2 "Gurt_nicht_gesteckt" 1 "Fehler" 0 "nicht_verfuegbar" ;
VAL_ 1360 AB2_Gurt_2BfS 3 "Gurt_gesteckt" 2 "Gurt_nicht_gesteckt" 1 "Fehler" 0 "nicht_verfuegbar" ;
VAL_ 1360 AB2_Gurt_2Mi 3 "Gurt_gesteckt" 2 "Gurt_nicht_gesteckt" 1 "Fehler" 0 "nicht_verfuegbar" ;
VAL_ 1360 AB2_Gurt_3FaS 3 "Gurt_gesteckt" 2 "Gurt_nicht_gesteckt" 1 "Fehler" 0 "nicht_verfuegbar" ;
VAL_ 1360 AB2_Gurt_3BfS 3 "Gurt_gesteckt" 2 "Gurt_nicht_gesteckt" 1 "Fehler" 0 "nicht_verfuegbar" ;
VAL_ 1360 AB2_Gurt_3Mi 3 "Gurt_gesteckt" 2 "Gurt_nicht_gesteckt" 1 "Fehler" 0 "nicht_verfuegbar" ;
VAL_ 1360 AB_Deaktivierung_HV 7 "Fehler" 6 "Deaktivierung_6" 5 "Deaktivierung_5" 4 "Deaktivierung_4" 3 "Deaktivierung_3" 2 "Deaktivierung_2" 1 "Deaktivierung_1" 0 "keine_Deaktivierung" ;
VAL_ 1360 AB_Abschaltanf_SIH_BF 1 "Abschaltung_angefordert" 0 "Normalbetrieb" ;
VAL_ 1404 BY1_KD_Fehler 1 "Fehlerspeichereintrag" 0 "kein_Fehlerspeichereintrag" ;
VAL_ 1404 BMS_Gesamtst_Spgfreiheit 3 "Fehler_nicht_spannungsfrei" 2 "HV_System_nicht_spannungsfrei" 1 "HV_System_spannungsfrei" 0 "Funktion_nicht_aktiviert" ;
VAL_ 1404 BMS_Temperatur 255 "Fehler" 254 "Init" ;
VAL_ 1404 BMS_Temperierung_Anf 7 "Umwaelzungsbedarf" 6 "hoher_Heizbedarf" 5 "mittlerer_Heizbedarf" 4 "niedriger_Heizbedarf" 3 "kein_Temperierungsbedarf_Init" 2 "niedriger_Kuehlbedarf" 1 "mittlerer_Kuehlbedarf" 0 "hoher_Kuehlbedarf" ;
VAL_ 1404 BMS_As_Entladezaehler_Ueberlauf 1 "Ueberlauf" 0 "kein_Ueberlauf" ;
VAL_ 1404 BMS_IstVorlaufTemperatur 255 "Fehler" 254 "Init" ;
VAL_ 1524 BCN_AntriebsVar 3 "reserviert" 2 "quattro" 1 "front" 0 "keine_Variante" ;
VAL_ 1504 CL1_LL_Dz 1 "Anhebung" 0 "keine_Anhebung" ;
VAL_ 1504 CL1_Fa_Zuheiz 1 "Ein" 0 "Aus" ;
VAL_ 1504 CL1_Hecksch 1 "Ein" 0 "Aus" ;
VAL_ 1504 CL1_Frontsch 1 "Ein" 0 "Aus" ;
VAL_ 1504 CL1_Kompressor 1 "Ein" 0 "Aus" ;
VAL_ 1504 CL1_Heizleist 1 "keine_Heizleistung" 0 "Heizleistung" ;
VAL_ 1504 CL1_Sta_Moment 1 "veraltet" 0 "aktuell" ;
VAL_ 1504 CL1_Sta_Druck 1 "veraltet" 0 "aktuell" ;
VAL_ 1504 CL1_Aussentemp 255 "Fehler" ;
VAL_ 1504 CL1_Druck 255 "Fehler" ;
VAL_ 1504 CL1_Kompr_Last 255 "Fehler" ;
VAL_ 1504 CL1_Gebl_last 255 "Fehler" ;
VAL_ 1504 CL1_Luefter 255 "Fehler" ;
VAL_ 1504 CL1_Einheit_Temp 1 "Fahrenheit" 0 "Grad_C" ;
VAL_ 1504 CL1_AC_Schalter 1 "ein_gedrueckt_oder_an" 0 "aus" ;
VAL_ 1504 CL1_WAPU_Zuschaltung 1 "WAPU_AUS" 0 "WAPU_EIN" ;
VAL_ 1504 CL1_Restwaerme 1 "aktiviert" 0 "nicht_aktiviert" ;
VAL_ 1504 CL1_Fehlereintr 1 "Fehlerspeichereintrag" 0 "kein_Fehlerspeichereintrag" ;
VAL_ 1504 KL_Thermomanagement 3 "volle_Freigabe_TMM" 2 "mittlere_Freigabe_TMM" 1 "kleine_Freigabe_TMM" 0 "keine_Freigabe_TMM" ;
VAL_ 1504 KL_VK_Betriebsdauer 63 "Fehler" 62 "Init" ;
VAL_ 1432 DA1_Daempferreg 7 "Notfahrfunktion" 6 "nicht_definiert" 5 "nicht_aktiv" 4 "sport_2" 3 "sport_1" 2 "normal" 1 "komfortabel" 0 "Init_oder_kein_Wert_verfuegbar" ;
VAL_ 1432 DA1_Warnlampe 1 "Lampe_ein" 0 "Lampe_aus" ;
VAL_ 1432 DA1_Taster 1 "Taste_gedrueckt" 0 "Taste_nicht_gedrueckt" ;
VAL_ 1432 DA1_Systemstatus 1 "funktionsfaehig" 0 "nicht_funktionsfaehig" ;
VAL_ 1432 DA1_Fehlereintr 1 "Fehlerspeichereintrag" 0 "kein_Fehlerspeichereintrag" ;
VAL_ 1432 DA1_Textbits 0 "kein_Text" ;
VAL_ 1432 DA1_ESP_Zwang 1 "ESP_zwangszuschalten" 0 "ESP_nicht_zuschalten" ;
VAL_ 1432 DA1_LampPruef 1 "Lampe_aufpruefen" 0 "Lampe_nicht_aufpr" ;
VAL_ 1432 DA1_Charisma 1 "Charisma_aktiv" 0 "kein_Charisma" ;
VAL_ 1550 EH1_Einh_Strck 1 "mls" 0 "km" ;
VAL_ 1550 EH1_Einh_Temp 1 "Grad_F" 0 "Grad_C" ;
VAL_ 1550 EH1_Einh_Vol 1 "gallons" 0 "liter" ;
VAL_ 1550 EH1_Einh_Verbr 1 "Vol_Strecke" 0 "Strecke_Vol" ;
VAL_ 1550 EH1_Einh_Druck 3 "kPa" 2 "nn" 1 "psi" 0 "bar" ;
VAL_ 1550 EH1_Datum_Anzeige 1 "MM_TT_JJJJ" 0 "TT_MM_JJJJ" ;
VAL_ 1550 EH1_Uhr_Anzeige 1 "12h_Anz" 0 "24h_Anz" ;
VAL_ 1550 EH1_Wochentag 7 "So" 6 "Sa" 5 "Fr" 4 "Do" 3 "Mi" 2 "Di" 1 "Mo" 0 "Init" ;
VAL_ 1550 EH1_Verstellung_Strck 1 "ja" 0 "nein" ;
VAL_ 1406 EY1_KD_Fehler 1 "Fehlerspeichereintrag" 0 "kein_Fehlerspeichereintrag" ;
VAL_ 1626 FL1_KD_Fehler 1 "Fehlerspeichereintrag" 0 "kein_Fehlerspeichereintrag" ;
VAL_ 1626 FL1_FLA_aktiv 1 "aktiv" 0 "nicht_aktiv" ;
VAL_ 1626 FL1_ISP_defekt 1 "defekt" 0 "nicht_defekt" ;
VAL_ 1626 FL1_Sensor_blockiert 1 "Sensor_blockiert" 0 "Sensor_iO" ;
VAL_ 1626 FL1_Abblendursache 255 "Fehler" 128 "Verz_Bed" 64 "Uebertemp" 32 "Nebel" 16 "zu_hell" 8 "Ort_erkannt" 4 "v_unterschr" 2 "voraus_Fzg" 1 "entg_Fzg" 0 "keine" ;
VAL_ 1626 FL1_Fernlicht_PWM 127 "Fehler" ;
VAL_ 1626 FL1_ISP_Lichtwert_vo 63 "Fehler" 62 "Init" ;
VAL_ 1626 FL1_ISP_Lichtwert_hi 63 "Fehler" 62 "Init" ;
VAL_ 1626 FL1_ISP_Himmelsrichtung 31 "Fehler" 30 "Init" ;
VAL_ 1626 FL1_ISP_Taste 1 "betaetigt" 0 "nicht_betaetigt" ;
VAL_ 1626 FL1_ISP_EC_aktiv 1 "aktiv" 0 "nicht_aktiv" ;
VAL_ 1626 FL1_ISP_Kompass_aktiv 1 "aktiv" 0 "nicht_aktiv" ;
VAL_ 1626 FL1_Dimmwert_ASP 63 "Fehler" ;
VAL_ 1626 FL1_FLA_Aufblenden 1 "aufblenden" 0 "nicht_aufblenden" ;
